VERSION ""

NS_ :

BS_:

BU_:  Battery  Charger  Host

BO_ 2566852863 BATT_eventMatrix_A_9: 8 Battery
 SG_ BATT_packModIdFault_9 : 8|1@1+ (1,0) [0|1] "" Host
 SG_ BATT_packModExitedFromBus_9 : 16|1@1+ (1,0) [0|1] "" Host
 SG_ BATT_packFetChgWelded_9 : 35|1@1+ (1,0) [0|1] "" Host
 SG_ BATT_packFetDsgWelded_9 : 36|1@1+ (1,0) [0|1] "" Host
 SG_ BATT_fetDsgShortedAux_9 : 63|1@1+ (1,0) [0|1] "" Host
 SG_ BATT_fetChgShortedAux_9 : 25|1@1+ (1,0) [0|1] "" Host
 SG_ BATT_prechargeFetFail_9 : 39|1@1+ (1,0) [0|1] "" Host
 SG_ BATT_abnormalResetReason_9 : 31|1@1+ (1,0) [0|1] "" Host
 SG_ BATT_prechargeTooSlow_9 : 49|1@1+ (1,0) [0|1] "" Host
 SG_ BATT_prechargeTooFast_9 : 50|1@1+ (1,0) [0|1] "" Host
 SG_ BATT_prechargeTimeout_9 : 51|1@1+ (1,0) [0|1] "" Host
 SG_ BATT_fetChgShorted_9 : 23|1@1+ (1,0) [0|1] "" Host
 SG_ BATT_fetChgFailToClose_9 : 22|1@1+ (1,0) [0|1] "" Host
 SG_ BATT_packModSelectFault_9 : 21|1@1+ (1,0) [0|1] "" Host
 SG_ BATT_packModConnectFault_9 : 20|1@1+ (1,0) [0|1] "" Host
 SG_ BATT_packModMIA_9 : 19|1@1+ (1,0) [0|1] "" Host
 SG_ BATT_packModImbalance_9 : 18|1@1+ (1,0) [0|1] "" Host
 SG_ BATT_afeFault_9 : 17|1@1+ (1,0) [0|1] "" Host
 SG_ BATT_chargerMIA_9 : 60|1@1+ (1,0) [0|1] "" Host
 SG_ BATT_chargerError_9 : 59|1@1+ (1,0) [0|1] "" Host
 SG_ BATT_vBrickUnderWar_9 : 58|1@1+ (1,0) [0|1] "" Host
 SG_ BATT_vBrickUnderSev_9 : 57|1@1+ (1,0) [0|1] "" Host
 SG_ BATT_vBrickUnderMod_9 : 56|1@1+ (1,0) [0|1] "" Host
 SG_ BATT_vBrickOverWar_9 : 55|1@1+ (1,0) [0|1] "" Host
 SG_ BATT_vBrickOverSev_9 : 54|1@1+ (1,0) [0|1] "" Host
 SG_ BATT_vBrickOverMod_9 : 53|1@1+ (1,0) [0|1] "" Host
 SG_ BATT_vBrickImbalance_9 : 52|1@1+ (1,0) [0|1] "" Host
 SG_ BATT_loggerAlmostFull_9 : 61|1@1+ (1,0) [0|1] "" Host
 SG_ BATT_tempModuleUnderWar_9 : 48|1@1+ (1,0) [0|1] "" Host
 SG_ BATT_tempModuleUnderSev_9 : 47|1@1+ (1,0) [0|1] "" Host
 SG_ BATT_tempModuleUnderMod_9 : 46|1@1+ (1,0) [0|1] "" Host
 SG_ BATT_tempModuleOverWar_9 : 45|1@1+ (1,0) [0|1] "" Host
 SG_ BATT_tempModuleOverSev_9 : 44|1@1+ (1,0) [0|1] "" Host
 SG_ BATT_tempModuleOverMod_9 : 43|1@1+ (1,0) [0|1] "" Host
 SG_ BATT_tempBrickImbalance_9 : 42|1@1+ (1,0) [0|1] "" Host
 SG_ BATT_taskLockupError_9 : 41|1@1+ (1,0) [0|1] "" Host
 SG_ BATT_tempBoardOverWar_9 : 40|1@1+ (1,0) [0|1] "" Host
 SG_ BATT_tempBoardOverSev_9 : 38|1@1+ (1,0) [0|1] "" Host
 SG_ BATT_tempBoardOverMod_9 : 37|1@1+ (1,0) [0|1] "" Host
 SG_ BATT_sensePackVoltError_9 : 34|1@1+ (1,0) [0|1] "" Host
 SG_ BATT_senseLoadVoltError_9 : 33|1@1+ (1,0) [0|1] "" Host
 SG_ BATT_loggerFull_9 : 62|1@1+ (1,0) [0|1] "" Host
 SG_ BATT_senseCurrentError_9 : 32|1@1+ (1,0) [0|1] "" Host
 SG_ BATT_senseBrickTempError_9 : 30|1@1+ (1,0) [0|1] "" Host
 SG_ BATT_resPackHigh_9 : 29|1@1+ (1,0) [0|1] "" Host
 SG_ BATT_ramOverUtilError_9 : 28|1@1+ (1,0) [0|1] "" Host
 SG_ BATT_powerPackInsufficient_9 : 27|1@1+ (1,0) [0|1] "" Host
 SG_ BATT_packCellSoftShort_9 : 26|1@1+ (1,0) [0|1] "" Host
 SG_ BATT_iOverHardware_9 : 24|1@1+ (1,0) [0|1] "" Host
 SG_ BATT_fetOverTemp_9 : 15|1@1+ (1,0) [0|1] "" Host
 SG_ BATT_iOverDischarge_9 : 14|1@1+ (1,0) [0|1] "" Host
 SG_ BATT_iOverCharge_9 : 13|1@1+ (1,0) [0|1] "" Host
 SG_ BATT_inverterDriveMIA_9 : 12|1@1+ (1,0) [0|1] "" Host
 SG_ BATT_iUnderCharge_9 : 11|1@1+ (1,0) [0|1] "" Host
 SG_ BATT_hostMIA_9 : 10|1@1+ (1,0) [0|1] "" Host
 SG_ BATT_fetDsgShorted_9 : 7|1@1+ (1,0) [0|1] "" Host
 SG_ BATT_fetDsgFailToClose_9 : 6|1@1+ (1,0) [0|1] "" Host
 SG_ BATT_capLow_9 : 5|1@1+ (1,0) [0|1] "" Host
 SG_ BATT_brickOverDischarge_9 : 4|1@1+ (1,0) [0|1] "" Host
 SG_ BATT_brickOverCharge_9 : 3|1@1+ (1,0) [0|1] "" Host
 SG_ BATT_bmsProcessorError_9 : 2|1@1+ (1,0) [0|1] "" Host
 SG_ BATT_bmsMemoryError_9 : 1|1@1+ (1,0) [0|1] "" Host
 SG_ BATT_afeError_9 : 0|1@1+ (1,0) [0|1] "" Host

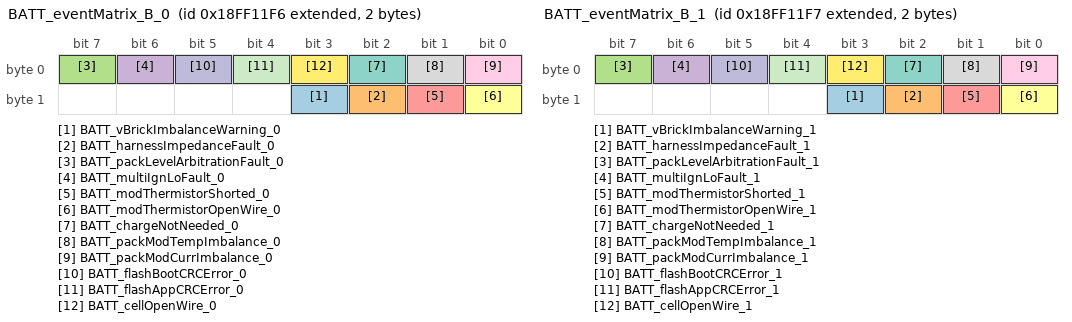
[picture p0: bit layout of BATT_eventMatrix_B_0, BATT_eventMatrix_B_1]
BO_ 2566853110 BATT_eventMatrix_B_0: 2 Battery
 SG_ BATT_vBrickImbalanceWarning_0 : 11|1@1+ (1,0) [0|1] "" Host
 SG_ BATT_harnessImpedanceFault_0 : 10|1@1+ (1,0) [0|1] "mOhms" Host
 SG_ BATT_packLevelArbitrationFault_0 : 7|1@1+ (1,0) [0|1] "" Host
 SG_ BATT_multiIgnLoFault_0 : 6|1@1+ (1,0) [0|1] "" Host
 SG_ BATT_modThermistorShorted_0 : 9|1@1+ (1,0) [0|1] "" Host
 SG_ BATT_modThermistorOpenWire_0 : 8|1@1+ (1,0) [0|1] "" Host
 SG_ BATT_chargeNotNeeded_0 : 2|1@1+ (1,0) [0|1] "" Host
 SG_ BATT_packModTempImbalance_0 : 1|1@1+ (1,0) [0|1] "" Host
 SG_ BATT_packModCurrImbalance_0 : 0|1@1+ (1,0) [0|1] "" Host
 SG_ BATT_flashBootCRCError_0 : 5|1@1+ (1,0) [0|1] "" Host
 SG_ BATT_flashAppCRCError_0 : 4|1@1+ (1,0) [0|1] "" Host
 SG_ BATT_cellOpenWire_0 : 3|1@1+ (1,0) [0|1] "" Host

BO_ 2566853111 BATT_eventMatrix_B_1: 2 Battery
 SG_ BATT_vBrickImbalanceWarning_1 : 11|1@1+ (1,0) [0|1] "" Host
 SG_ BATT_harnessImpedanceFault_1 : 10|1@1+ (1,0) [0|1] "mOhms" Host
 SG_ BATT_packLevelArbitrationFault_1 : 7|1@1+ (1,0) [0|1] "" Host
 SG_ BATT_multiIgnLoFault_1 : 6|1@1+ (1,0) [0|1] "" Host
 SG_ BATT_modThermistorShorted_1 : 9|1@1+ (1,0) [0|1] "" Host
 SG_ BATT_modThermistorOpenWire_1 : 8|1@1+ (1,0) [0|1] "" Host
 SG_ BATT_chargeNotNeeded_1 : 2|1@1+ (1,0) [0|1] "" Host
 SG_ BATT_packModTempImbalance_1 : 1|1@1+ (1,0) [0|1] "" Host
 SG_ BATT_packModCurrImbalance_1 : 0|1@1+ (1,0) [0|1] "" Host
 SG_ BATT_flashBootCRCError_1 : 5|1@1+ (1,0) [0|1] "" Host
 SG_ BATT_flashAppCRCError_1 : 4|1@1+ (1,0) [0|1] "" Host
 SG_ BATT_cellOpenWire_1 : 3|1@1+ (1,0) [0|1] "" Host

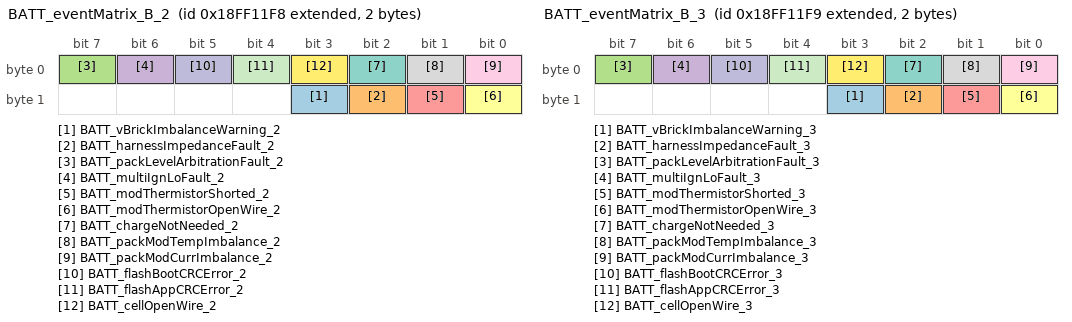
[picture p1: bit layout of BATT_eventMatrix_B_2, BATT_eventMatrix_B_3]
BO_ 2566853112 BATT_eventMatrix_B_2: 2 Battery
 SG_ BATT_vBrickImbalanceWarning_2 : 11|1@1+ (1,0) [0|1] "" Host
 SG_ BATT_harnessImpedanceFault_2 : 10|1@1+ (1,0) [0|1] "mOhms" Host
 SG_ BATT_packLevelArbitrationFault_2 : 7|1@1+ (1,0) [0|1] "" Host
 SG_ BATT_multiIgnLoFault_2 : 6|1@1+ (1,0) [0|1] "" Host
 SG_ BATT_modThermistorShorted_2 : 9|1@1+ (1,0) [0|1] "" Host
 SG_ BATT_modThermistorOpenWire_2 : 8|1@1+ (1,0) [0|1] "" Host
 SG_ BATT_chargeNotNeeded_2 : 2|1@1+ (1,0) [0|1] "" Host
 SG_ BATT_packModTempImbalance_2 : 1|1@1+ (1,0) [0|1] "" Host
 SG_ BATT_packModCurrImbalance_2 : 0|1@1+ (1,0) [0|1] "" Host
 SG_ BATT_flashBootCRCError_2 : 5|1@1+ (1,0) [0|1] "" Host
 SG_ BATT_flashAppCRCError_2 : 4|1@1+ (1,0) [0|1] "" Host
 SG_ BATT_cellOpenWire_2 : 3|1@1+ (1,0) [0|1] "" Host

BO_ 2566853113 BATT_eventMatrix_B_3: 2 Battery
 SG_ BATT_vBrickImbalanceWarning_3 : 11|1@1+ (1,0) [0|1] "" Host
 SG_ BATT_harnessImpedanceFault_3 : 10|1@1+ (1,0) [0|1] "mOhms" Host
 SG_ BATT_packLevelArbitrationFault_3 : 7|1@1+ (1,0) [0|1] "" Host
 SG_ BATT_multiIgnLoFault_3 : 6|1@1+ (1,0) [0|1] "" Host
 SG_ BATT_modThermistorShorted_3 : 9|1@1+ (1,0) [0|1] "" Host
 SG_ BATT_modThermistorOpenWire_3 : 8|1@1+ (1,0) [0|1] "" Host
 SG_ BATT_chargeNotNeeded_3 : 2|1@1+ (1,0) [0|1] "" Host
 SG_ BATT_packModTempImbalance_3 : 1|1@1+ (1,0) [0|1] "" Host
 SG_ BATT_packModCurrImbalance_3 : 0|1@1+ (1,0) [0|1] "" Host
 SG_ BATT_flashBootCRCError_3 : 5|1@1+ (1,0) [0|1] "" Host
 SG_ BATT_flashAppCRCError_3 : 4|1@1+ (1,0) [0|1] "" Host
 SG_ BATT_cellOpenWire_3 : 3|1@1+ (1,0) [0|1] "" Host

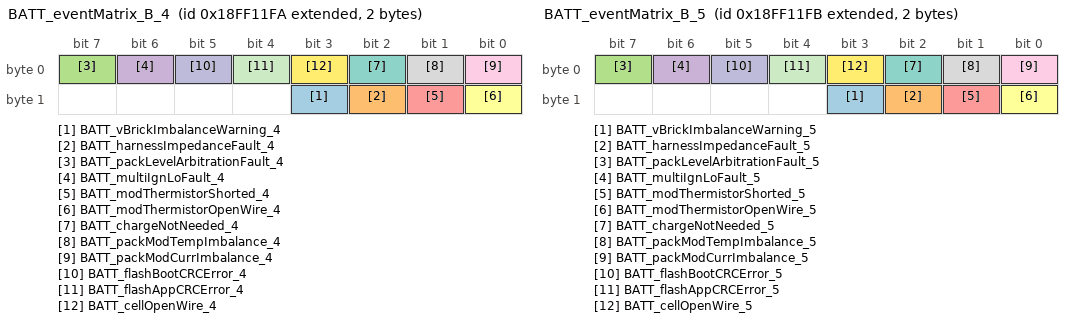
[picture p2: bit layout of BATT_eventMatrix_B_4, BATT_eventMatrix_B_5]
BO_ 2566853114 BATT_eventMatrix_B_4: 2 Battery
 SG_ BATT_vBrickImbalanceWarning_4 : 11|1@1+ (1,0) [0|1] "" Host
 SG_ BATT_harnessImpedanceFault_4 : 10|1@1+ (1,0) [0|1] "mOhms" Host
 SG_ BATT_packLevelArbitrationFault_4 : 7|1@1+ (1,0) [0|1] "" Host
 SG_ BATT_multiIgnLoFault_4 : 6|1@1+ (1,0) [0|1] "" Host
 SG_ BATT_modThermistorShorted_4 : 9|1@1+ (1,0) [0|1] "" Host
 SG_ BATT_modThermistorOpenWire_4 : 8|1@1+ (1,0) [0|1] "" Host
 SG_ BATT_chargeNotNeeded_4 : 2|1@1+ (1,0) [0|1] "" Host
 SG_ BATT_packModTempImbalance_4 : 1|1@1+ (1,0) [0|1] "" Host
 SG_ BATT_packModCurrImbalance_4 : 0|1@1+ (1,0) [0|1] "" Host
 SG_ BATT_flashBootCRCError_4 : 5|1@1+ (1,0) [0|1] "" Host
 SG_ BATT_flashAppCRCError_4 : 4|1@1+ (1,0) [0|1] "" Host
 SG_ BATT_cellOpenWire_4 : 3|1@1+ (1,0) [0|1] "" Host

BO_ 2566853115 BATT_eventMatrix_B_5: 2 Battery
 SG_ BATT_vBrickImbalanceWarning_5 : 11|1@1+ (1,0) [0|1] "" Host
 SG_ BATT_harnessImpedanceFault_5 : 10|1@1+ (1,0) [0|1] "mOhms" Host
 SG_ BATT_packLevelArbitrationFault_5 : 7|1@1+ (1,0) [0|1] "" Host
 SG_ BATT_multiIgnLoFault_5 : 6|1@1+ (1,0) [0|1] "" Host
 SG_ BATT_modThermistorShorted_5 : 9|1@1+ (1,0) [0|1] "" Host
 SG_ BATT_modThermistorOpenWire_5 : 8|1@1+ (1,0) [0|1] "" Host
 SG_ BATT_chargeNotNeeded_5 : 2|1@1+ (1,0) [0|1] "" Host
 SG_ BATT_packModTempImbalance_5 : 1|1@1+ (1,0) [0|1] "" Host
 SG_ BATT_packModCurrImbalance_5 : 0|1@1+ (1,0) [0|1] "" Host
 SG_ BATT_flashBootCRCError_5 : 5|1@1+ (1,0) [0|1] "" Host
 SG_ BATT_flashAppCRCError_5 : 4|1@1+ (1,0) [0|1] "" Host
 SG_ BATT_cellOpenWire_5 : 3|1@1+ (1,0) [0|1] "" Host

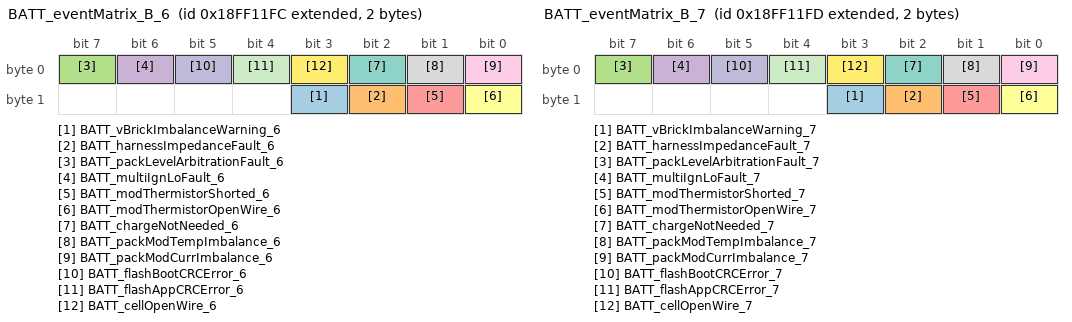
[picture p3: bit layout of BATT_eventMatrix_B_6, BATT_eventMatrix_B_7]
BO_ 2566853116 BATT_eventMatrix_B_6: 2 Battery
 SG_ BATT_vBrickImbalanceWarning_6 : 11|1@1+ (1,0) [0|1] "" Host
 SG_ BATT_harnessImpedanceFault_6 : 10|1@1+ (1,0) [0|1] "mOhms" Host
 SG_ BATT_packLevelArbitrationFault_6 : 7|1@1+ (1,0) [0|1] "" Host
 SG_ BATT_multiIgnLoFault_6 : 6|1@1+ (1,0) [0|1] "" Host
 SG_ BATT_modThermistorShorted_6 : 9|1@1+ (1,0) [0|1] "" Host
 SG_ BATT_modThermistorOpenWire_6 : 8|1@1+ (1,0) [0|1] "" Host
 SG_ BATT_chargeNotNeeded_6 : 2|1@1+ (1,0) [0|1] "" Host
 SG_ BATT_packModTempImbalance_6 : 1|1@1+ (1,0) [0|1] "" Host
 SG_ BATT_packModCurrImbalance_6 : 0|1@1+ (1,0) [0|1] "" Host
 SG_ BATT_flashBootCRCError_6 : 5|1@1+ (1,0) [0|1] "" Host
 SG_ BATT_flashAppCRCError_6 : 4|1@1+ (1,0) [0|1] "" Host
 SG_ BATT_cellOpenWire_6 : 3|1@1+ (1,0) [0|1] "" Host

BO_ 2566853117 BATT_eventMatrix_B_7: 2 Battery
 SG_ BATT_vBrickImbalanceWarning_7 : 11|1@1+ (1,0) [0|1] "" Host
 SG_ BATT_harnessImpedanceFault_7 : 10|1@1+ (1,0) [0|1] "mOhms" Host
 SG_ BATT_packLevelArbitrationFault_7 : 7|1@1+ (1,0) [0|1] "" Host
 SG_ BATT_multiIgnLoFault_7 : 6|1@1+ (1,0) [0|1] "" Host
 SG_ BATT_modThermistorShorted_7 : 9|1@1+ (1,0) [0|1] "" Host
 SG_ BATT_modThermistorOpenWire_7 : 8|1@1+ (1,0) [0|1] "" Host
 SG_ BATT_chargeNotNeeded_7 : 2|1@1+ (1,0) [0|1] "" Host
 SG_ BATT_packModTempImbalance_7 : 1|1@1+ (1,0) [0|1] "" Host
 SG_ BATT_packModCurrImbalance_7 : 0|1@1+ (1,0) [0|1] "" Host
 SG_ BATT_flashBootCRCError_7 : 5|1@1+ (1,0) [0|1] "" Host
 SG_ BATT_flashAppCRCError_7 : 4|1@1+ (1,0) [0|1] "" Host
 SG_ BATT_cellOpenWire_7 : 3|1@1+ (1,0) [0|1] "" Host

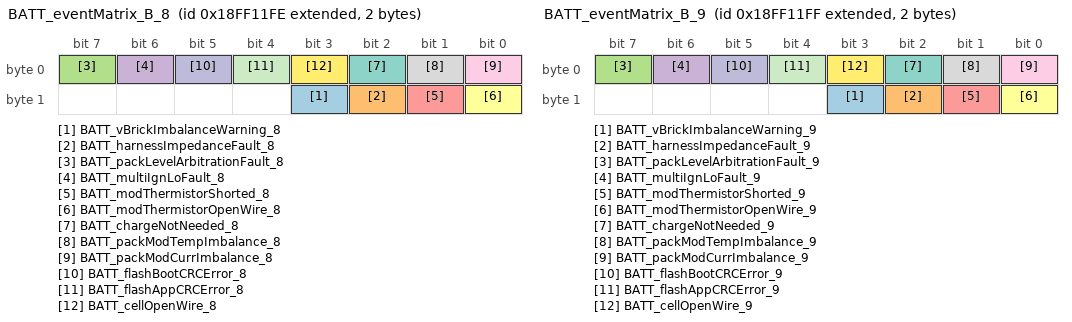
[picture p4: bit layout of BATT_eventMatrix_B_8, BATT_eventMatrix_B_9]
BO_ 2566853118 BATT_eventMatrix_B_8: 2 Battery
 SG_ BATT_vBrickImbalanceWarning_8 : 11|1@1+ (1,0) [0|1] "" Host
 SG_ BATT_harnessImpedanceFault_8 : 10|1@1+ (1,0) [0|1] "mOhms" Host
 SG_ BATT_packLevelArbitrationFault_8 : 7|1@1+ (1,0) [0|1] "" Host
 SG_ BATT_multiIgnLoFault_8 : 6|1@1+ (1,0) [0|1] "" Host
 SG_ BATT_modThermistorShorted_8 : 9|1@1+ (1,0) [0|1] "" Host
 SG_ BATT_modThermistorOpenWire_8 : 8|1@1+ (1,0) [0|1] "" Host
 SG_ BATT_chargeNotNeeded_8 : 2|1@1+ (1,0) [0|1] "" Host
 SG_ BATT_packModTempImbalance_8 : 1|1@1+ (1,0) [0|1] "" Host
 SG_ BATT_packModCurrImbalance_8 : 0|1@1+ (1,0) [0|1] "" Host
 SG_ BATT_flashBootCRCError_8 : 5|1@1+ (1,0) [0|1] "" Host
 SG_ BATT_flashAppCRCError_8 : 4|1@1+ (1,0) [0|1] "" Host
 SG_ BATT_cellOpenWire_8 : 3|1@1+ (1,0) [0|1] "" Host

BO_ 2566853119 BATT_eventMatrix_B_9: 2 Battery
 SG_ BATT_vBrickImbalanceWarning_9 : 11|1@1+ (1,0) [0|1] "" Host
 SG_ BATT_harnessImpedanceFault_9 : 10|1@1+ (1,0) [0|1] "mOhms" Host
 SG_ BATT_packLevelArbitrationFault_9 : 7|1@1+ (1,0) [0|1] "" Host
 SG_ BATT_multiIgnLoFault_9 : 6|1@1+ (1,0) [0|1] "" Host
 SG_ BATT_modThermistorShorted_9 : 9|1@1+ (1,0) [0|1] "" Host
 SG_ BATT_modThermistorOpenWire_9 : 8|1@1+ (1,0) [0|1] "" Host
 SG_ BATT_chargeNotNeeded_9 : 2|1@1+ (1,0) [0|1] "" Host
 SG_ BATT_packModTempImbalance_9 : 1|1@1+ (1,0) [0|1] "" Host
 SG_ BATT_packModCurrImbalance_9 : 0|1@1+ (1,0) [0|1] "" Host
 SG_ BATT_flashBootCRCError_9 : 5|1@1+ (1,0) [0|1] "" Host
 SG_ BATT_flashAppCRCError_9 : 4|1@1+ (1,0) [0|1] "" Host
 SG_ BATT_cellOpenWire_9 : 3|1@1+ (1,0) [0|1] "" Host

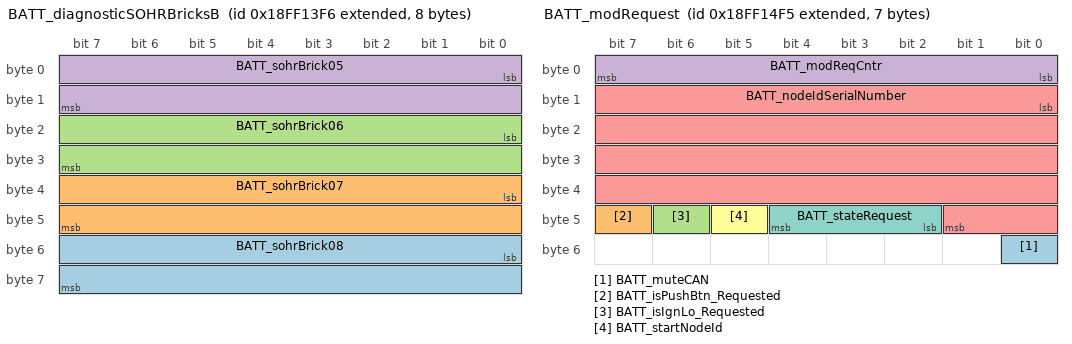
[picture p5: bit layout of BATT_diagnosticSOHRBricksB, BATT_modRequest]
BO_ 2566853622 BATT_diagnosticSOHRBricksB: 8 Battery
 SG_ BATT_sohrBrick08 : 48|16@1+ (0.00075,0) [0|49.15125] "Ah" Host
 SG_ BATT_sohrBrick07 : 32|16@1+ (0.00075,0) [0|49.15125] "Ah" Host
 SG_ BATT_sohrBrick06 : 16|16@1+ (0.00075,0) [0|49.15125] "Ah" Host
 SG_ BATT_sohrBrick05 : 0|16@1+ (0.00075,0) [0|49.15125] "Ah" Host

BO_ 2566853877 BATT_modRequest: 7 Battery
 SG_ BATT_muteCAN : 48|1@1+ (1,0) [0|1] "" Host,Battery
 SG_ BATT_isPushBtn_Requested : 47|1@1+ (1,0) [0|1] "" Battery,Host
 SG_ BATT_isIgnLo_Requested : 46|1@1+ (1,0) [0|1] "" Battery,Host
 SG_ BATT_modReqCntr : 0|8@1+ (1,0) [0|255] "" Battery,Host
 SG_ BATT_nodeIdSerialNumber : 8|34@1+ (1,0) [0|17179869183] "" Battery,Host
 SG_ BATT_startNodeId : 45|1@1+ (1,0) [0|1] "" Battery,Host
 SG_ BATT_stateRequest : 42|3@1+ (1,0) [0|7] "" Battery,Host

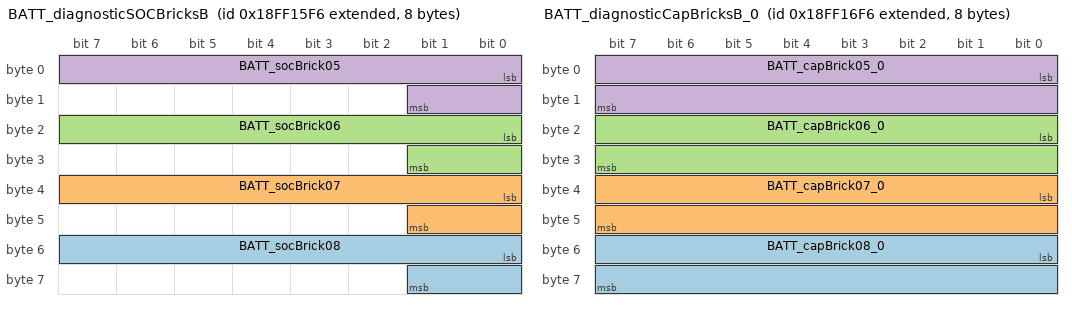
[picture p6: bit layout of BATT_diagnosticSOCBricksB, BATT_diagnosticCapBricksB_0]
BO_ 2566854134 BATT_diagnosticSOCBricksB: 8 Battery
 SG_ BATT_socBrick08 : 48|10@1+ (0.1,0) [0|102.3] "%" Host
 SG_ BATT_socBrick07 : 32|10@1+ (0.1,0) [0|102.3] "%" Host
 SG_ BATT_socBrick06 : 16|10@1+ (0.1,0) [0|102.3] "%" Host
 SG_ BATT_socBrick05 : 0|10@1+ (0.1,0) [0|102.3] "%" Host

BO_ 2566854390 BATT_diagnosticCapBricksB_0: 8 Battery
 SG_ BATT_capBrick08_0 : 48|16@1+ (0.0025,0) [0|163.8375] "Ah" Host
 SG_ BATT_capBrick07_0 : 32|16@1+ (0.0025,0) [0|163.8375] "Ah" Host
 SG_ BATT_capBrick06_0 : 16|16@1+ (0.0025,0) [0|163.8375] "Ah" Host
 SG_ BATT_capBrick05_0 : 0|16@1+ (0.0025,0) [0|163.8375] "Ah" Host

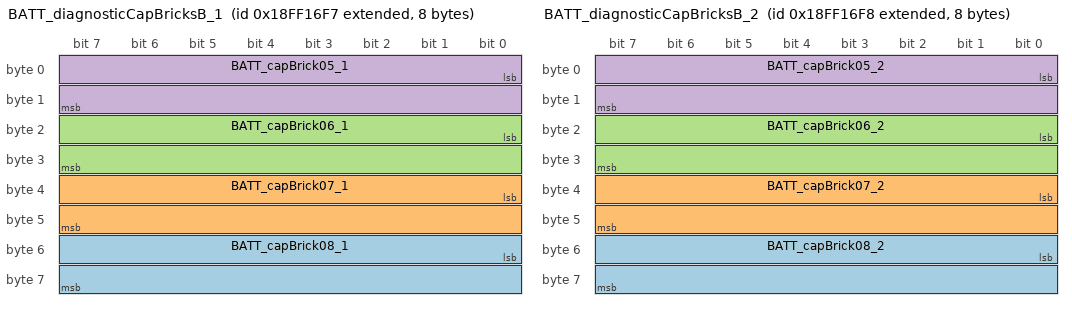
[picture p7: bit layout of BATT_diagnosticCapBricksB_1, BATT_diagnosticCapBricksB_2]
BO_ 2566854391 BATT_diagnosticCapBricksB_1: 8 Battery
 SG_ BATT_capBrick08_1 : 48|16@1+ (0.0025,0) [0|163.8375] "Ah" Host
 SG_ BATT_capBrick07_1 : 32|16@1+ (0.0025,0) [0|163.8375] "Ah" Host
 SG_ BATT_capBrick06_1 : 16|16@1+ (0.0025,0) [0|163.8375] "Ah" Host
 SG_ BATT_capBrick05_1 : 0|16@1+ (0.0025,0) [0|163.8375] "Ah" Host

BO_ 2566854392 BATT_diagnosticCapBricksB_2: 8 Battery
 SG_ BATT_capBrick08_2 : 48|16@1+ (0.0025,0) [0|163.8375] "Ah" Host
 SG_ BATT_capBrick07_2 : 32|16@1+ (0.0025,0) [0|163.8375] "Ah" Host
 SG_ BATT_capBrick06_2 : 16|16@1+ (0.0025,0) [0|163.8375] "Ah" Host
 SG_ BATT_capBrick05_2 : 0|16@1+ (0.0025,0) [0|163.8375] "Ah" Host

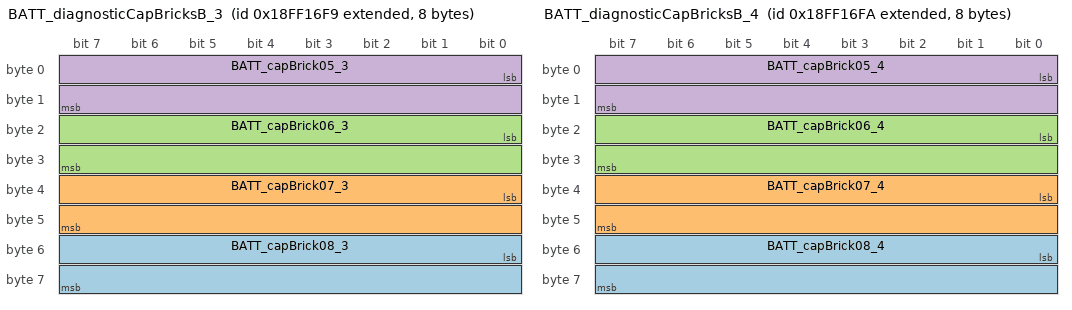
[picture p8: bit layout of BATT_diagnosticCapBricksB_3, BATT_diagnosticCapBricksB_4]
BO_ 2566854393 BATT_diagnosticCapBricksB_3: 8 Battery
 SG_ BATT_capBrick08_3 : 48|16@1+ (0.0025,0) [0|163.8375] "Ah" Host
 SG_ BATT_capBrick07_3 : 32|16@1+ (0.0025,0) [0|163.8375] "Ah" Host
 SG_ BATT_capBrick06_3 : 16|16@1+ (0.0025,0) [0|163.8375] "Ah" Host
 SG_ BATT_capBrick05_3 : 0|16@1+ (0.0025,0) [0|163.8375] "Ah" Host

BO_ 2566854394 BATT_diagnosticCapBricksB_4: 8 Battery
 SG_ BATT_capBrick08_4 : 48|16@1+ (0.0025,0) [0|163.8375] "Ah" Host
 SG_ BATT_capBrick07_4 : 32|16@1+ (0.0025,0) [0|163.8375] "Ah" Host
 SG_ BATT_capBrick06_4 : 16|16@1+ (0.0025,0) [0|163.8375] "Ah" Host
 SG_ BATT_capBrick05_4 : 0|16@1+ (0.0025,0) [0|163.8375] "Ah" Host

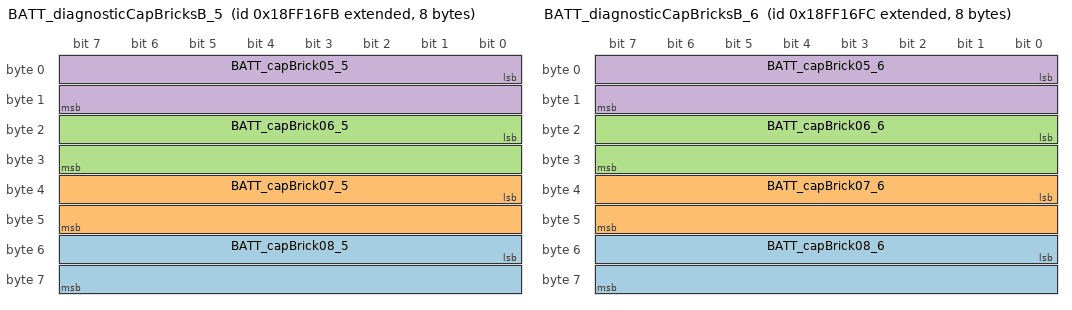
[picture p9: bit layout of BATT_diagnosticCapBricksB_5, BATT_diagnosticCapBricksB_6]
BO_ 2566854395 BATT_diagnosticCapBricksB_5: 8 Battery
 SG_ BATT_capBrick08_5 : 48|16@1+ (0.0025,0) [0|163.8375] "Ah" Host
 SG_ BATT_capBrick07_5 : 32|16@1+ (0.0025,0) [0|163.8375] "Ah" Host
 SG_ BATT_capBrick06_5 : 16|16@1+ (0.0025,0) [0|163.8375] "Ah" Host
 SG_ BATT_capBrick05_5 : 0|16@1+ (0.0025,0) [0|163.8375] "Ah" Host

BO_ 2566854396 BATT_diagnosticCapBricksB_6: 8 Battery
 SG_ BATT_capBrick08_6 : 48|16@1+ (0.0025,0) [0|163.8375] "Ah" Host
 SG_ BATT_capBrick07_6 : 32|16@1+ (0.0025,0) [0|163.8375] "Ah" Host
 SG_ BATT_capBrick06_6 : 16|16@1+ (0.0025,0) [0|163.8375] "Ah" Host
 SG_ BATT_capBrick05_6 : 0|16@1+ (0.0025,0) [0|163.8375] "Ah" Host

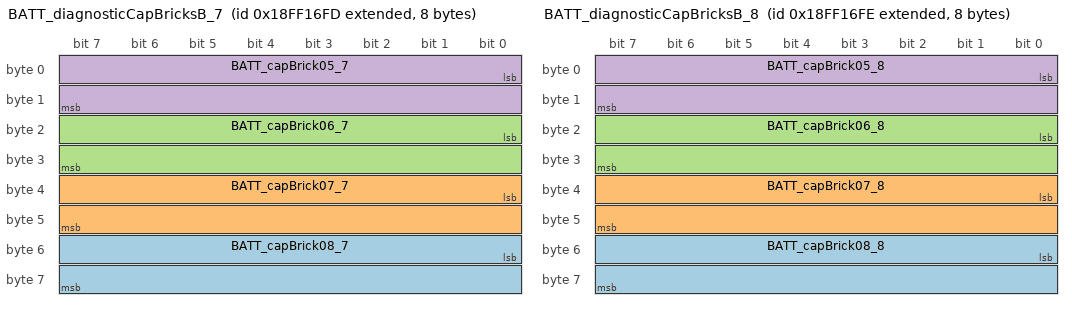
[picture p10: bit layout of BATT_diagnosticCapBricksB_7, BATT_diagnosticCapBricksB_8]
BO_ 2566854397 BATT_diagnosticCapBricksB_7: 8 Battery
 SG_ BATT_capBrick08_7 : 48|16@1+ (0.0025,0) [0|163.8375] "Ah" Host
 SG_ BATT_capBrick07_7 : 32|16@1+ (0.0025,0) [0|163.8375] "Ah" Host
 SG_ BATT_capBrick06_7 : 16|16@1+ (0.0025,0) [0|163.8375] "Ah" Host
 SG_ BATT_capBrick05_7 : 0|16@1+ (0.0025,0) [0|163.8375] "Ah" Host

BO_ 2566854398 BATT_diagnosticCapBricksB_8: 8 Battery
 SG_ BATT_capBrick08_8 : 48|16@1+ (0.0025,0) [0|163.8375] "Ah" Host
 SG_ BATT_capBrick07_8 : 32|16@1+ (0.0025,0) [0|163.8375] "Ah" Host
 SG_ BATT_capBrick06_8 : 16|16@1+ (0.0025,0) [0|163.8375] "Ah" Host
 SG_ BATT_capBrick05_8 : 0|16@1+ (0.0025,0) [0|163.8375] "Ah" Host

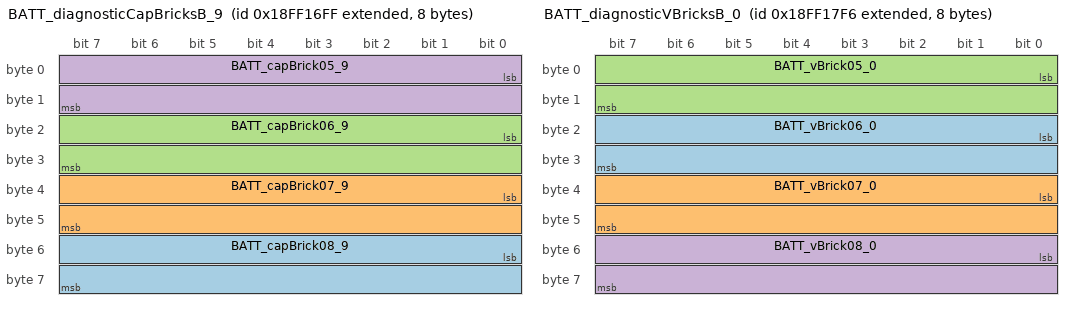
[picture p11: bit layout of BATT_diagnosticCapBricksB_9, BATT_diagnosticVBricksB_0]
BO_ 2566854399 BATT_diagnosticCapBricksB_9: 8 Battery
 SG_ BATT_capBrick08_9 : 48|16@1+ (0.0025,0) [0|163.8375] "Ah" Host
 SG_ BATT_capBrick07_9 : 32|16@1+ (0.0025,0) [0|163.8375] "Ah" Host
 SG_ BATT_capBrick06_9 : 16|16@1+ (0.0025,0) [0|163.8375] "Ah" Host
 SG_ BATT_capBrick05_9 : 0|16@1+ (0.0025,0) [0|163.8375] "Ah" Host

BO_ 2566854646 BATT_diagnosticVBricksB_0: 8 Battery
 SG_ BATT_vBrick06_0 : 16|16@1+ (7.6e-05,0) [0|4.98066] "V" Host
 SG_ BATT_vBrick07_0 : 32|16@1+ (7.6e-05,0) [0|4.98066] "V" Host
 SG_ BATT_vBrick05_0 : 0|16@1+ (7.6e-05,0) [0|4.98066] "V" Host
 SG_ BATT_vBrick08_0 : 48|16@1+ (7.6e-05,0) [0|4.98066] "V" Host

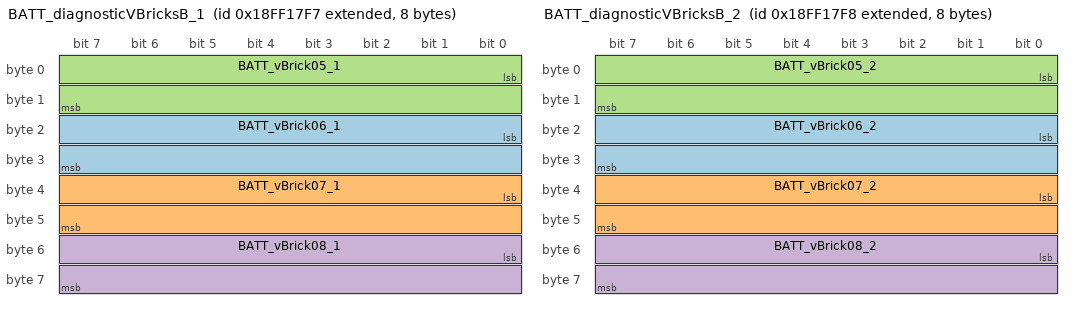
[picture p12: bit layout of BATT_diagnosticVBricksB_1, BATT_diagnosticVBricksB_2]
BO_ 2566854647 BATT_diagnosticVBricksB_1: 8 Battery
 SG_ BATT_vBrick06_1 : 16|16@1+ (7.6e-05,0) [0|4.98066] "V" Host
 SG_ BATT_vBrick07_1 : 32|16@1+ (7.6e-05,0) [0|4.98066] "V" Host
 SG_ BATT_vBrick05_1 : 0|16@1+ (7.6e-05,0) [0|4.98066] "V" Host
 SG_ BATT_vBrick08_1 : 48|16@1+ (7.6e-05,0) [0|4.98066] "V" Host

BO_ 2566854648 BATT_diagnosticVBricksB_2: 8 Battery
 SG_ BATT_vBrick06_2 : 16|16@1+ (7.6e-05,0) [0|4.98066] "V" Host
 SG_ BATT_vBrick07_2 : 32|16@1+ (7.6e-05,0) [0|4.98066] "V" Host
 SG_ BATT_vBrick05_2 : 0|16@1+ (7.6e-05,0) [0|4.98066] "V" Host
 SG_ BATT_vBrick08_2 : 48|16@1+ (7.6e-05,0) [0|4.98066] "V" Host

BO_ 2566854649 BATT_diagnosticVBricksB_3: 8 Battery
 SG_ BATT_vBrick06_3 : 16|16@1+ (7.6e-05,0) [0|4.98066] "V" Host
 SG_ BATT_vBrick07_3 : 32|16@1+ (7.6e-05,0) [0|4.98066] "V" Host
 SG_ BATT_vBrick05_3 : 0|16@1+ (7.6e-05,0) [0|4.98066] "V" Host
 SG_ BATT_vBrick08_3 : 48|16@1+ (7.6e-05,0) [0|4.98066] "V" Host

BO_ 2566854650 BATT_diagnosticVBricksB_4: 8 Battery
 SG_ BATT_vBrick06_4 : 16|16@1+ (7.6e-05,0) [0|4.98066] "V" Host
 SG_ BATT_vBrick07_4 : 32|16@1+ (7.6e-05,0) [0|4.98066] "V" Host
 SG_ BATT_vBrick05_4 : 0|16@1+ (7.6e-05,0) [0|4.98066] "V" Host
 SG_ BATT_vBrick08_4 : 48|16@1+ (7.6e-05,0) [0|4.98066] "V" Host

BO_ 2566854651 BATT_diagnosticVBricksB_5: 8 Battery
 SG_ BATT_vBrick06_5 : 16|16@1+ (7.6e-05,0) [0|4.98066] "V" Host
 SG_ BATT_vBrick07_5 : 32|16@1+ (7.6e-05,0) [0|4.98066] "V" Host
 SG_ BATT_vBrick05_5 : 0|16@1+ (7.6e-05,0) [0|4.98066] "V" Host
 SG_ BATT_vBrick08_5 : 48|16@1+ (7.6e-05,0) [0|4.98066] "V" Host

BO_ 2566854652 BATT_diagnosticVBricksB_6: 8 Battery
 SG_ BATT_vBrick06_6 : 16|16@1+ (7.6e-05,0) [0|4.98066] "V" Host
 SG_ BATT_vBrick07_6 : 32|16@1+ (7.6e-05,0) [0|4.98066] "V" Host
 SG_ BATT_vBrick05_6 : 0|16@1+ (7.6e-05,0) [0|4.98066] "V" Host
 SG_ BATT_vBrick08_6 : 48|16@1+ (7.6e-05,0) [0|4.98066] "V" Host

BO_ 2566854653 BATT_diagnosticVBricksB_7: 8 Battery
 SG_ BATT_vBrick06_7 : 16|16@1+ (7.6e-05,0) [0|4.98066] "V" Host
 SG_ BATT_vBrick07_7 : 32|16@1+ (7.6e-05,0) [0|4.98066] "V" Host
 SG_ BATT_vBrick05_7 : 0|16@1+ (7.6e-05,0) [0|4.98066] "V" Host
 SG_ BATT_vBrick08_7 : 48|16@1+ (7.6e-05,0) [0|4.98066] "V" Host

BO_ 2566854654 BATT_diagnosticVBricksB_8: 8 Battery
 SG_ BATT_vBrick06_8 : 16|16@1+ (7.6e-05,0) [0|4.98066] "V" Host
 SG_ BATT_vBrick07_8 : 32|16@1+ (7.6e-05,0) [0|4.98066] "V" Host
 SG_ BATT_vBrick05_8 : 0|16@1+ (7.6e-05,0) [0|4.98066] "V" Host
 SG_ BATT_vBrick08_8 : 48|16@1+ (7.6e-05,0) [0|4.98066] "V" Host

BO_ 2566854655 BATT_diagnosticVBricksB_9: 8 Battery
 SG_ BATT_vBrick06_9 : 16|16@1+ (7.6e-05,0) [0|4.98066] "V" Host
 SG_ BATT_vBrick07_9 : 32|16@1+ (7.6e-05,0) [0|4.98066] "V" Host
 SG_ BATT_vBrick05_9 : 0|16@1+ (7.6e-05,0) [0|4.98066] "V" Host
 SG_ BATT_vBrick08_9 : 48|16@1+ (7.6e-05,0) [0|4.98066] "V" Host

BO_ 2566854902 BATT_diagnosticResBricksB: 8 Battery
 SG_ BATT_resBrick08 : 48|16@1+ (0.01,0) [0|655.35] "mOhms" Host
 SG_ BATT_resBrick07 : 32|16@1+ (0.01,0) [0|655.35] "mOhms" Host
 SG_ BATT_resBrick06 : 16|16@1+ (0.01,0) [0|655.35] "mOhms" Host
 SG_ BATT_resBrick05 : 0|16@1+ (0.01,0) [0|655.35] "mOhms" Host

BO_ 2566855158 BATT_modTemperaturesB_0: 8 Battery
 SG_ BATT_tPreChg_0 : 16|16@1- (0.1,0) [-40|125] "deg C" Host
 SG_ BATT_tShunt_0 : 48|16@1- (0.1,0) [-40|125] "deg C" Host
 SG_ BATT_tFET_0 : 32|16@1- (0.1,0) [-40|125] "deg C" Host

BO_ 2566855159 BATT_modTemperaturesB_1: 8 Battery
 SG_ BATT_tPreChg_1 : 16|16@1- (0.1,0) [-40|125] "deg C" Host
 SG_ BATT_tShunt_1 : 48|16@1- (0.1,0) [-40|125] "deg C" Host
 SG_ BATT_tFET_1 : 32|16@1- (0.1,0) [-40|125] "deg C" Host

BO_ 2566855160 BATT_modTemperaturesB_2: 8 Battery
 SG_ BATT_tPreChg_2 : 16|16@1- (0.1,0) [-40|125] "deg C" Host
 SG_ BATT_tShunt_2 : 48|16@1- (0.1,0) [-40|125] "deg C" Host
 SG_ BATT_tFET_2 : 32|16@1- (0.1,0) [-40|125] "deg C" Host

BO_ 2566855161 BATT_modTemperaturesB_3: 8 Battery
 SG_ BATT_tPreChg_3 : 16|16@1- (0.1,0) [-40|125] "deg C" Host
 SG_ BATT_tShunt_3 : 48|16@1- (0.1,0) [-40|125] "deg C" Host
 SG_ BATT_tFET_3 : 32|16@1- (0.1,0) [-40|125] "deg C" Host

BO_ 2566855162 BATT_modTemperaturesB_4: 8 Battery
 SG_ BATT_tPreChg_4 : 16|16@1- (0.1,0) [-40|125] "deg C" Host
 SG_ BATT_tShunt_4 : 48|16@1- (0.1,0) [-40|125] "deg C" Host
 SG_ BATT_tFET_4 : 32|16@1- (0.1,0) [-40|125] "deg C" Host

BO_ 2566855163 BATT_modTemperaturesB_5: 8 Battery
 SG_ BATT_tPreChg_5 : 16|16@1- (0.1,0) [-40|125] "deg C" Host
 SG_ BATT_tShunt_5 : 48|16@1- (0.1,0) [-40|125] "deg C" Host
 SG_ BATT_tFET_5 : 32|16@1- (0.1,0) [-40|125] "deg C" Host

BO_ 2566855164 BATT_modTemperaturesB_6: 8 Battery
 SG_ BATT_tPreChg_6 : 16|16@1- (0.1,0) [-40|125] "deg C" Host
 SG_ BATT_tShunt_6 : 48|16@1- (0.1,0) [-40|125] "deg C" Host
 SG_ BATT_tFET_6 : 32|16@1- (0.1,0) [-40|125] "deg C" Host

BO_ 2566855165 BATT_modTemperaturesB_7: 8 Battery
 SG_ BATT_tPreChg_7 : 16|16@1- (0.1,0) [-40|125] "deg C" Host
 SG_ BATT_tShunt_7 : 48|16@1- (0.1,0) [-40|125] "deg C" Host
 SG_ BATT_tFET_7 : 32|16@1- (0.1,0) [-40|125] "deg C" Host

BO_ 2566855166 BATT_modTemperaturesB_8: 8 Battery
 SG_ BATT_tPreChg_8 : 16|16@1- (0.1,0) [-40|125] "deg C" Host
 SG_ BATT_tShunt_8 : 48|16@1- (0.1,0) [-40|125] "deg C" Host
 SG_ BATT_tFET_8 : 32|16@1- (0.1,0) [-40|125] "deg C" Host

BO_ 2566855167 BATT_modTemperaturesB_9: 8 Battery
 SG_ BATT_tPreChg_9 : 16|16@1- (0.1,0) [-40|125] "deg C" Host
 SG_ BATT_tShunt_9 : 48|16@1- (0.1,0) [-40|125] "deg C" Host
 SG_ BATT_tFET_9 : 32|16@1- (0.1,0) [-40|125] "deg C" Host

BO_ 2566856694 BATT_boardIO_0: 3 Battery
 SG_ BATT_boardIO_nSD_PWR_AVL_0 : 20|1@1+ (1,0) [0|0] "" Host
 SG_ BATT_boardIO_nL9963_FAULT_0 : 19|1@1+ (1,0) [0|0] "" Host
 SG_ BATT_boardIO_PRE_CHG_FB_0 : 18|1@1+ (1,0) [0|0] "" Host
 SG_ BATT_boardIO_BTN_WAKE_LCH_0 : 17|1@1+ (1,0) [0|0] "" Host
 SG_ BATT_boardIO_BTN_WAKE_0 : 16|1@1+ (1,0) [0|0] "" Host
 SG_ BATT_boardIO_IGN_L_0 : 13|1@1+ (1,0) [0|0] "" Host
 SG_ BATT_boardIO_IGN_H_0 : 12|1@1+ (1,0) [0|0] "" Host
 SG_ BATT_boardIO_EXT_5V_STATUS_0 : 11|1@1+ (1,0) [0|0] "" Host
 SG_ BATT_boardIO_L9963_FAULT_LA_0 : 10|1@1+ (1,0) [0|0] "" Host
 SG_ BATT_boardIO_RTC_WAKE_LA_0 : 9|1@1+ (1,0) [0|0] "" Host
 SG_ BATT_boardIO_CAN_WAKE_LATCH_0 : 8|1@1+ (1,0) [0|0] "" Host
 SG_ BATT_boardIO_DIS_OC_FLT_LA_0 : 5|1@1+ (1,0) [0|1] "" Host
 SG_ BATT_boardIO_RTC_WAKE_LATCH_0 : 4|1@1+ (1,0) [0|0] "" Host
 SG_ BATT_boardIO_L9963_FAULT_0 : 3|1@1+ (1,0) [0|1] "" Host
 SG_ BATT_boardIO_IGN_L_LCH_0 : 2|1@1+ (1,0) [0|0] "" Host
 SG_ BATT_boardIO_IGN_H_LCH_0 : 1|1@1+ (1,0) [0|0] "" Host
 SG_ BATT_boardIO_CAN_WAKE_0 : 0|1@1+ (1,0) [0|1] "" Host

BO_ 2566856695 BATT_boardIO_1: 3 Battery
 SG_ BATT_boardIO_nSD_PWR_AVL_1 : 20|1@1+ (1,0) [0|0] "" Host
 SG_ BATT_boardIO_nL9963_FAULT_1 : 19|1@1+ (1,0) [0|0] "" Host
 SG_ BATT_boardIO_PRE_CHG_FB_1 : 18|1@1+ (1,0) [0|0] "" Host
 SG_ BATT_boardIO_BTN_WAKE_LCH_1 : 17|1@1+ (1,0) [0|0] "" Host
 SG_ BATT_boardIO_BTN_WAKE_1 : 16|1@1+ (1,0) [0|0] "" Host
 SG_ BATT_boardIO_IGN_L_1 : 13|1@1+ (1,0) [0|0] "" Host
 SG_ BATT_boardIO_IGN_H_1 : 12|1@1+ (1,0) [0|0] "" Host
 SG_ BATT_boardIO_EXT_5V_STATUS_1 : 11|1@1+ (1,0) [0|0] "" Host
 SG_ BATT_boardIO_L9963_FAULT_LA_1 : 10|1@1+ (1,0) [0|0] "" Host
 SG_ BATT_boardIO_RTC_WAKE_LA_1 : 9|1@1+ (1,0) [0|0] "" Host
 SG_ BATT_boardIO_CAN_WAKE_LATCH_1 : 8|1@1+ (1,0) [0|0] "" Host
 SG_ BATT_boardIO_DIS_OC_FLT_LA_1 : 5|1@1+ (1,0) [0|1] "" Host
 SG_ BATT_boardIO_RTC_WAKE_LATCH_1 : 4|1@1+ (1,0) [0|0] "" Host
 SG_ BATT_boardIO_L9963_FAULT_1 : 3|1@1+ (1,0) [0|1] "" Host
 SG_ BATT_boardIO_IGN_L_LCH_1 : 2|1@1+ (1,0) [0|0] "" Host
 SG_ BATT_boardIO_IGN_H_LCH_1 : 1|1@1+ (1,0) [0|0] "" Host
 SG_ BATT_boardIO_CAN_WAKE_1 : 0|1@1+ (1,0) [0|1] "" Host

BO_ 2566856696 BATT_boardIO_2: 3 Battery
 SG_ BATT_boardIO_nSD_PWR_AVL_2 : 20|1@1+ (1,0) [0|0] "" Host
 SG_ BATT_boardIO_nL9963_FAULT_2 : 19|1@1+ (1,0) [0|0] "" Host
 SG_ BATT_boardIO_PRE_CHG_FB_2 : 18|1@1+ (1,0) [0|0] "" Host
 SG_ BATT_boardIO_BTN_WAKE_LCH_2 : 17|1@1+ (1,0) [0|0] "" Host
 SG_ BATT_boardIO_BTN_WAKE_2 : 16|1@1+ (1,0) [0|0] "" Host
 SG_ BATT_boardIO_IGN_L_2 : 13|1@1+ (1,0) [0|0] "" Host
 SG_ BATT_boardIO_IGN_H_2 : 12|1@1+ (1,0) [0|0] "" Host
 SG_ BATT_boardIO_EXT_5V_STATUS_2 : 11|1@1+ (1,0) [0|0] "" Host
 SG_ BATT_boardIO_L9963_FAULT_LA_2 : 10|1@1+ (1,0) [0|0] "" Host
 SG_ BATT_boardIO_RTC_WAKE_LA_2 : 9|1@1+ (1,0) [0|0] "" Host
 SG_ BATT_boardIO_CAN_WAKE_LATCH_2 : 8|1@1+ (1,0) [0|0] "" Host
 SG_ BATT_boardIO_DIS_OC_FLT_LA_2 : 5|1@1+ (1,0) [0|1] "" Host
 SG_ BATT_boardIO_RTC_WAKE_LATCH_2 : 4|1@1+ (1,0) [0|0] "" Host
 SG_ BATT_boardIO_L9963_FAULT_2 : 3|1@1+ (1,0) [0|1] "" Host
 SG_ BATT_boardIO_IGN_L_LCH_2 : 2|1@1+ (1,0) [0|0] "" Host
 SG_ BATT_boardIO_IGN_H_LCH_2 : 1|1@1+ (1,0) [0|0] "" Host
 SG_ BATT_boardIO_CAN_WAKE_2 : 0|1@1+ (1,0) [0|1] "" Host

BO_ 2566856697 BATT_boardIO_3: 3 Battery
 SG_ BATT_boardIO_nSD_PWR_AVL_3 : 20|1@1+ (1,0) [0|0] "" Host
 SG_ BATT_boardIO_nL9963_FAULT_3 : 19|1@1+ (1,0) [0|0] "" Host
 SG_ BATT_boardIO_PRE_CHG_FB_3 : 18|1@1+ (1,0) [0|0] "" Host
 SG_ BATT_boardIO_BTN_WAKE_LCH_3 : 17|1@1+ (1,0) [0|0] "" Host
 SG_ BATT_boardIO_BTN_WAKE_3 : 16|1@1+ (1,0) [0|0] "" Host
 SG_ BATT_boardIO_IGN_L_3 : 13|1@1+ (1,0) [0|0] "" Host
 SG_ BATT_boardIO_IGN_H_3 : 12|1@1+ (1,0) [0|0] "" Host
 SG_ BATT_boardIO_EXT_5V_STATUS_3 : 11|1@1+ (1,0) [0|0] "" Host
 SG_ BATT_boardIO_L9963_FAULT_LA_3 : 10|1@1+ (1,0) [0|0] "" Host
 SG_ BATT_boardIO_RTC_WAKE_LA_3 : 9|1@1+ (1,0) [0|0] "" Host
 SG_ BATT_boardIO_CAN_WAKE_LATCH_3 : 8|1@1+ (1,0) [0|0] "" Host
 SG_ BATT_boardIO_DIS_OC_FLT_LA_3 : 5|1@1+ (1,0) [0|1] "" Host
 SG_ BATT_boardIO_RTC_WAKE_LATCH_3 : 4|1@1+ (1,0) [0|0] "" Host
 SG_ BATT_boardIO_L9963_FAULT_3 : 3|1@1+ (1,0) [0|1] "" Host
 SG_ BATT_boardIO_IGN_L_LCH_3 : 2|1@1+ (1,0) [0|0] "" Host
 SG_ BATT_boardIO_IGN_H_LCH_3 : 1|1@1+ (1,0) [0|0] "" Host
 SG_ BATT_boardIO_CAN_WAKE_3 : 0|1@1+ (1,0) [0|1] "" Host

BO_ 2566856698 BATT_boardIO_4: 3 Battery
 SG_ BATT_boardIO_nSD_PWR_AVL_4 : 20|1@1+ (1,0) [0|0] "" Host
 SG_ BATT_boardIO_nL9963_FAULT_4 : 19|1@1+ (1,0) [0|0] "" Host
 SG_ BATT_boardIO_PRE_CHG_FB_4 : 18|1@1+ (1,0) [0|0] "" Host
 SG_ BATT_boardIO_BTN_WAKE_LCH_4 : 17|1@1+ (1,0) [0|0] "" Host
 SG_ BATT_boardIO_BTN_WAKE_4 : 16|1@1+ (1,0) [0|0] "" Host
 SG_ BATT_boardIO_IGN_L_4 : 13|1@1+ (1,0) [0|0] "" Host
 SG_ BATT_boardIO_IGN_H_4 : 12|1@1+ (1,0) [0|0] "" Host
 SG_ BATT_boardIO_EXT_5V_STATUS_4 : 11|1@1+ (1,0) [0|0] "" Host
 SG_ BATT_boardIO_L9963_FAULT_LA_4 : 10|1@1+ (1,0) [0|0] "" Host
 SG_ BATT_boardIO_RTC_WAKE_LA_4 : 9|1@1+ (1,0) [0|0] "" Host
 SG_ BATT_boardIO_CAN_WAKE_LATCH_4 : 8|1@1+ (1,0) [0|0] "" Host
 SG_ BATT_boardIO_DIS_OC_FLT_LA_4 : 5|1@1+ (1,0) [0|1] "" Host
 SG_ BATT_boardIO_RTC_WAKE_LATCH_4 : 4|1@1+ (1,0) [0|0] "" Host
 SG_ BATT_boardIO_L9963_FAULT_4 : 3|1@1+ (1,0) [0|1] "" Host
 SG_ BATT_boardIO_IGN_L_LCH_4 : 2|1@1+ (1,0) [0|0] "" Host
 SG_ BATT_boardIO_IGN_H_LCH_4 : 1|1@1+ (1,0) [0|0] "" Host
 SG_ BATT_boardIO_CAN_WAKE_4 : 0|1@1+ (1,0) [0|1] "" Host

BO_ 2566856699 BATT_boardIO_5: 3 Battery
 SG_ BATT_boardIO_nSD_PWR_AVL_5 : 20|1@1+ (1,0) [0|0] "" Host
 SG_ BATT_boardIO_nL9963_FAULT_5 : 19|1@1+ (1,0) [0|0] "" Host
 SG_ BATT_boardIO_PRE_CHG_FB_5 : 18|1@1+ (1,0) [0|0] "" Host
 SG_ BATT_boardIO_BTN_WAKE_LCH_5 : 17|1@1+ (1,0) [0|0] "" Host
 SG_ BATT_boardIO_BTN_WAKE_5 : 16|1@1+ (1,0) [0|0] "" Host
 SG_ BATT_boardIO_IGN_L_5 : 13|1@1+ (1,0) [0|0] "" Host
 SG_ BATT_boardIO_IGN_H_5 : 12|1@1+ (1,0) [0|0] "" Host
 SG_ BATT_boardIO_EXT_5V_STATUS_5 : 11|1@1+ (1,0) [0|0] "" Host
 SG_ BATT_boardIO_L9963_FAULT_LA_5 : 10|1@1+ (1,0) [0|0] "" Host
 SG_ BATT_boardIO_RTC_WAKE_LA_5 : 9|1@1+ (1,0) [0|0] "" Host
 SG_ BATT_boardIO_CAN_WAKE_LATCH_5 : 8|1@1+ (1,0) [0|0] "" Host
 SG_ BATT_boardIO_DIS_OC_FLT_LA_5 : 5|1@1+ (1,0) [0|1] "" Host
 SG_ BATT_boardIO_RTC_WAKE_LATCH_5 : 4|1@1+ (1,0) [0|0] "" Host
 SG_ BATT_boardIO_L9963_FAULT_5 : 3|1@1+ (1,0) [0|1] "" Host
 SG_ BATT_boardIO_IGN_L_LCH_5 : 2|1@1+ (1,0) [0|0] "" Host
 SG_ BATT_boardIO_IGN_H_LCH_5 : 1|1@1+ (1,0) [0|0] "" Host
 SG_ BATT_boardIO_CAN_WAKE_5 : 0|1@1+ (1,0) [0|1] "" Host

BO_ 2566856700 BATT_boardIO_6: 3 Battery
 SG_ BATT_boardIO_nSD_PWR_AVL_6 : 20|1@1+ (1,0) [0|0] "" Host
 SG_ BATT_boardIO_nL9963_FAULT_6 : 19|1@1+ (1,0) [0|0] "" Host
 SG_ BATT_boardIO_PRE_CHG_FB_6 : 18|1@1+ (1,0) [0|0] "" Host
 SG_ BATT_boardIO_BTN_WAKE_LCH_6 : 17|1@1+ (1,0) [0|0] "" Host
 SG_ BATT_boardIO_BTN_WAKE_6 : 16|1@1+ (1,0) [0|0] "" Host
 SG_ BATT_boardIO_IGN_L_6 : 13|1@1+ (1,0) [0|0] "" Host
 SG_ BATT_boardIO_IGN_H_6 : 12|1@1+ (1,0) [0|0] "" Host
 SG_ BATT_boardIO_EXT_5V_STATUS_6 : 11|1@1+ (1,0) [0|0] "" Host
 SG_ BATT_boardIO_L9963_FAULT_LA_6 : 10|1@1+ (1,0) [0|0] "" Host
 SG_ BATT_boardIO_RTC_WAKE_LA_6 : 9|1@1+ (1,0) [0|0] "" Host
 SG_ BATT_boardIO_CAN_WAKE_LATCH_6 : 8|1@1+ (1,0) [0|0] "" Host
 SG_ BATT_boardIO_DIS_OC_FLT_LA_6 : 5|1@1+ (1,0) [0|1] "" Host
 SG_ BATT_boardIO_RTC_WAKE_LATCH_6 : 4|1@1+ (1,0) [0|0] "" Host
 SG_ BATT_boardIO_L9963_FAULT_6 : 3|1@1+ (1,0) [0|1] "" Host
 SG_ BATT_boardIO_IGN_L_LCH_6 : 2|1@1+ (1,0) [0|0] "" Host
 SG_ BATT_boardIO_IGN_H_LCH_6 : 1|1@1+ (1,0) [0|0] "" Host
 SG_ BATT_boardIO_CAN_WAKE_6 : 0|1@1+ (1,0) [0|1] "" Host

BO_ 2566856701 BATT_boardIO_7: 3 Battery
 SG_ BATT_boardIO_nSD_PWR_AVL_7 : 20|1@1+ (1,0) [0|0] "" Host
 SG_ BATT_boardIO_nL9963_FAULT_7 : 19|1@1+ (1,0) [0|0] "" Host
 SG_ BATT_boardIO_PRE_CHG_FB_7 : 18|1@1+ (1,0) [0|0] "" Host
 SG_ BATT_boardIO_BTN_WAKE_LCH_7 : 17|1@1+ (1,0) [0|0] "" Host
 SG_ BATT_boardIO_BTN_WAKE_7 : 16|1@1+ (1,0) [0|0] "" Host
 SG_ BATT_boardIO_IGN_L_7 : 13|1@1+ (1,0) [0|0] "" Host
 SG_ BATT_boardIO_IGN_H_7 : 12|1@1+ (1,0) [0|0] "" Host
 SG_ BATT_boardIO_EXT_5V_STATUS_7 : 11|1@1+ (1,0) [0|0] "" Host
 SG_ BATT_boardIO_L9963_FAULT_LA_7 : 10|1@1+ (1,0) [0|0] "" Host
 SG_ BATT_boardIO_RTC_WAKE_LA_7 : 9|1@1+ (1,0) [0|0] "" Host
 SG_ BATT_boardIO_CAN_WAKE_LATCH_7 : 8|1@1+ (1,0) [0|0] "" Host
 SG_ BATT_boardIO_DIS_OC_FLT_LA_7 : 5|1@1+ (1,0) [0|1] "" Host
 SG_ BATT_boardIO_RTC_WAKE_LATCH_7 : 4|1@1+ (1,0) [0|0] "" Host
 SG_ BATT_boardIO_L9963_FAULT_7 : 3|1@1+ (1,0) [0|1] "" Host
 SG_ BATT_boardIO_IGN_L_LCH_7 : 2|1@1+ (1,0) [0|0] "" Host
 SG_ BATT_boardIO_IGN_H_LCH_7 : 1|1@1+ (1,0) [0|0] "" Host
 SG_ BATT_boardIO_CAN_WAKE_7 : 0|1@1+ (1,0) [0|1] "" Host

BO_ 2566856702 BATT_boardIO_8: 3 Battery
 SG_ BATT_boardIO_nSD_PWR_AVL_8 : 20|1@1+ (1,0) [0|0] "" Host
 SG_ BATT_boardIO_nL9963_FAULT_8 : 19|1@1+ (1,0) [0|0] "" Host
 SG_ BATT_boardIO_PRE_CHG_FB_8 : 18|1@1+ (1,0) [0|0] "" Host
 SG_ BATT_boardIO_BTN_WAKE_LCH_8 : 17|1@1+ (1,0) [0|0] "" Host
 SG_ BATT_boardIO_BTN_WAKE_8 : 16|1@1+ (1,0) [0|0] "" Host
 SG_ BATT_boardIO_IGN_L_8 : 13|1@1+ (1,0) [0|0] "" Host
 SG_ BATT_boardIO_IGN_H_8 : 12|1@1+ (1,0) [0|0] "" Host
 SG_ BATT_boardIO_EXT_5V_STATUS_8 : 11|1@1+ (1,0) [0|0] "" Host
 SG_ BATT_boardIO_L9963_FAULT_LA_8 : 10|1@1+ (1,0) [0|0] "" Host
 SG_ BATT_boardIO_RTC_WAKE_LA_8 : 9|1@1+ (1,0) [0|0] "" Host
 SG_ BATT_boardIO_CAN_WAKE_LATCH_8 : 8|1@1+ (1,0) [0|0] "" Host
 SG_ BATT_boardIO_DIS_OC_FLT_LA_8 : 5|1@1+ (1,0) [0|1] "" Host
 SG_ BATT_boardIO_RTC_WAKE_LATCH_8 : 4|1@1+ (1,0) [0|0] "" Host
 SG_ BATT_boardIO_L9963_FAULT_8 : 3|1@1+ (1,0) [0|1] "" Host
 SG_ BATT_boardIO_IGN_L_LCH_8 : 2|1@1+ (1,0) [0|0] "" Host
 SG_ BATT_boardIO_IGN_H_LCH_8 : 1|1@1+ (1,0) [0|0] "" Host
 SG_ BATT_boardIO_CAN_WAKE_8 : 0|1@1+ (1,0) [0|1] "" Host

BO_ 2566856703 BATT_boardIO_9: 3 Battery
 SG_ BATT_boardIO_nSD_PWR_AVL_9 : 20|1@1+ (1,0) [0|0] "" Host
 SG_ BATT_boardIO_nL9963_FAULT_9 : 19|1@1+ (1,0) [0|0] "" Host
 SG_ BATT_boardIO_PRE_CHG_FB_9 : 18|1@1+ (1,0) [0|0] "" Host
 SG_ BATT_boardIO_BTN_WAKE_LCH_9 : 17|1@1+ (1,0) [0|0] "" Host
 SG_ BATT_boardIO_BTN_WAKE_9 : 16|1@1+ (1,0) [0|0] "" Host
 SG_ BATT_boardIO_IGN_L_9 : 13|1@1+ (1,0) [0|0] "" Host
 SG_ BATT_boardIO_IGN_H_9 : 12|1@1+ (1,0) [0|0] "" Host
 SG_ BATT_boardIO_EXT_5V_STATUS_9 : 11|1@1+ (1,0) [0|0] "" Host
 SG_ BATT_boardIO_L9963_FAULT_LA_9 : 10|1@1+ (1,0) [0|0] "" Host
 SG_ BATT_boardIO_RTC_WAKE_LA_9 : 9|1@1+ (1,0) [0|0] "" Host
 SG_ BATT_boardIO_CAN_WAKE_LATCH_9 : 8|1@1+ (1,0) [0|0] "" Host
 SG_ BATT_boardIO_DIS_OC_FLT_LA_9 : 5|1@1+ (1,0) [0|1] "" Host
 SG_ BATT_boardIO_RTC_WAKE_LATCH_9 : 4|1@1+ (1,0) [0|0] "" Host
 SG_ BATT_boardIO_L9963_FAULT_9 : 3|1@1+ (1,0) [0|1] "" Host
 SG_ BATT_boardIO_IGN_L_LCH_9 : 2|1@1+ (1,0) [0|0] "" Host
 SG_ BATT_boardIO_IGN_H_LCH_9 : 1|1@1+ (1,0) [0|0] "" Host
 SG_ BATT_boardIO_CAN_WAKE_9 : 0|1@1+ (1,0) [0|1] "" Host

BO_ 2566857718 BATT_diagnosticSOHRBricksC: 8 Battery
 SG_ BATT_sohrBrick12 : 48|16@1+ (0.00075,0) [0|49.15125] "Ah" Host
 SG_ BATT_sohrBrick11 : 32|16@1+ (0.00075,0) [0|49.15125] "Ah" Host
 SG_ BATT_sohrBrick10 : 16|16@1+ (0.00075,0) [0|49.15125] "Ah" Host
 SG_ BATT_sohrBrick09 : 0|16@1+ (0.00075,0) [0|49.15125] "Ah" Host

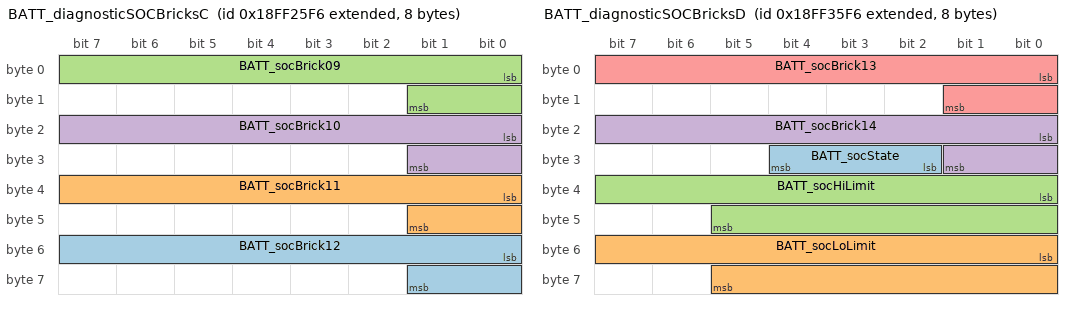
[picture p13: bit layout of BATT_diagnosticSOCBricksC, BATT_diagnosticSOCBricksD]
BO_ 2566858230 BATT_diagnosticSOCBricksC: 8 Battery
 SG_ BATT_socBrick12 : 48|10@1+ (0.1,0) [0|102.3] "%" Host
 SG_ BATT_socBrick11 : 32|10@1+ (0.1,0) [0|102.3] "%" Host
 SG_ BATT_socBrick09 : 0|10@1+ (0.1,0) [0|102.3] "%" Host
 SG_ BATT_socBrick10 : 16|10@1+ (0.1,0) [0|102.3] "%" Host

BO_ 2566858486 BATT_diagnosticCapBricksC_0: 8 Battery
 SG_ BATT_capBrick12_0 : 48|16@1+ (0.0025,0) [0|163.8375] "Ah" Host
 SG_ BATT_capBrick11_0 : 32|16@1+ (0.0025,0) [0|163.8375] "Ah" Host
 SG_ BATT_capBrick09_0 : 0|16@1+ (0.0025,0) [0|163.8375] "Ah" Host
 SG_ BATT_capBrick10_0 : 16|16@1+ (0.0025,0) [0|163.8375] "Ah" Host

BO_ 2566858487 BATT_diagnosticCapBricksC_1: 8 Battery
 SG_ BATT_capBrick12_1 : 48|16@1+ (0.0025,0) [0|163.8375] "Ah" Host
 SG_ BATT_capBrick11_1 : 32|16@1+ (0.0025,0) [0|163.8375] "Ah" Host
 SG_ BATT_capBrick09_1 : 0|16@1+ (0.0025,0) [0|163.8375] "Ah" Host
 SG_ BATT_capBrick10_1 : 16|16@1+ (0.0025,0) [0|163.8375] "Ah" Host

BO_ 2566858488 BATT_diagnosticCapBricksC_2: 8 Battery
 SG_ BATT_capBrick12_2 : 48|16@1+ (0.0025,0) [0|163.8375] "Ah" Host
 SG_ BATT_capBrick11_2 : 32|16@1+ (0.0025,0) [0|163.8375] "Ah" Host
 SG_ BATT_capBrick09_2 : 0|16@1+ (0.0025,0) [0|163.8375] "Ah" Host
 SG_ BATT_capBrick10_2 : 16|16@1+ (0.0025,0) [0|163.8375] "Ah" Host

BO_ 2566858489 BATT_diagnosticCapBricksC_3: 8 Battery
 SG_ BATT_capBrick12_3 : 48|16@1+ (0.0025,0) [0|163.8375] "Ah" Host
 SG_ BATT_capBrick11_3 : 32|16@1+ (0.0025,0) [0|163.8375] "Ah" Host
 SG_ BATT_capBrick09_3 : 0|16@1+ (0.0025,0) [0|163.8375] "Ah" Host
 SG_ BATT_capBrick10_3 : 16|16@1+ (0.0025,0) [0|163.8375] "Ah" Host

BO_ 2566858490 BATT_diagnosticCapBricksC_4: 8 Battery
 SG_ BATT_capBrick12_4 : 48|16@1+ (0.0025,0) [0|163.8375] "Ah" Host
 SG_ BATT_capBrick11_4 : 32|16@1+ (0.0025,0) [0|163.8375] "Ah" Host
 SG_ BATT_capBrick09_4 : 0|16@1+ (0.0025,0) [0|163.8375] "Ah" Host
 SG_ BATT_capBrick10_4 : 16|16@1+ (0.0025,0) [0|163.8375] "Ah" Host

BO_ 2566858491 BATT_diagnosticCapBricksC_5: 8 Battery
 SG_ BATT_capBrick12_5 : 48|16@1+ (0.0025,0) [0|163.8375] "Ah" Host
 SG_ BATT_capBrick11_5 : 32|16@1+ (0.0025,0) [0|163.8375] "Ah" Host
 SG_ BATT_capBrick09_5 : 0|16@1+ (0.0025,0) [0|163.8375] "Ah" Host
 SG_ BATT_capBrick10_5 : 16|16@1+ (0.0025,0) [0|163.8375] "Ah" Host

BO_ 2566858492 BATT_diagnosticCapBricksC_6: 8 Battery
 SG_ BATT_capBrick12_6 : 48|16@1+ (0.0025,0) [0|163.8375] "Ah" Host
 SG_ BATT_capBrick11_6 : 32|16@1+ (0.0025,0) [0|163.8375] "Ah" Host
 SG_ BATT_capBrick09_6 : 0|16@1+ (0.0025,0) [0|163.8375] "Ah" Host
 SG_ BATT_capBrick10_6 : 16|16@1+ (0.0025,0) [0|163.8375] "Ah" Host

BO_ 2566858493 BATT_diagnosticCapBricksC_7: 8 Battery
 SG_ BATT_capBrick12_7 : 48|16@1+ (0.0025,0) [0|163.8375] "Ah" Host
 SG_ BATT_capBrick11_7 : 32|16@1+ (0.0025,0) [0|163.8375] "Ah" Host
 SG_ BATT_capBrick09_7 : 0|16@1+ (0.0025,0) [0|163.8375] "Ah" Host
 SG_ BATT_capBrick10_7 : 16|16@1+ (0.0025,0) [0|163.8375] "Ah" Host

BO_ 2566858494 BATT_diagnosticCapBricksC_8: 8 Battery
 SG_ BATT_capBrick12_8 : 48|16@1+ (0.0025,0) [0|163.8375] "Ah" Host
 SG_ BATT_capBrick11_8 : 32|16@1+ (0.0025,0) [0|163.8375] "Ah" Host
 SG_ BATT_capBrick09_8 : 0|16@1+ (0.0025,0) [0|163.8375] "Ah" Host
 SG_ BATT_capBrick10_8 : 16|16@1+ (0.0025,0) [0|163.8375] "Ah" Host

BO_ 2566858495 BATT_diagnosticCapBricksC_9: 8 Battery
 SG_ BATT_capBrick12_9 : 48|16@1+ (0.0025,0) [0|163.8375] "Ah" Host
 SG_ BATT_capBrick11_9 : 32|16@1+ (0.0025,0) [0|163.8375] "Ah" Host
 SG_ BATT_capBrick09_9 : 0|16@1+ (0.0025,0) [0|163.8375] "Ah" Host
 SG_ BATT_capBrick10_9 : 16|16@1+ (0.0025,0) [0|163.8375] "Ah" Host

BO_ 2566858742 BATT_diagnosticVBricksC_0: 8 Battery
 SG_ BATT_vBrick12_0 : 48|16@1+ (7.6e-05,0) [0|4.98066] "V" Host
 SG_ BATT_vBrick11_0 : 32|16@1+ (7.6e-05,0) [0|4.98066] "V" Host
 SG_ BATT_vBrick10_0 : 16|16@1+ (7.6e-05,0) [0|4.98066] "V" Host
 SG_ BATT_vBrick09_0 : 0|16@1+ (7.6e-05,0) [0|4.98066] "V" Host

BO_ 2566858743 BATT_diagnosticVBricksC_1: 8 Battery
 SG_ BATT_vBrick12_1 : 48|16@1+ (7.6e-05,0) [0|4.98066] "V" Host
 SG_ BATT_vBrick11_1 : 32|16@1+ (7.6e-05,0) [0|4.98066] "V" Host
 SG_ BATT_vBrick10_1 : 16|16@1+ (7.6e-05,0) [0|4.98066] "V" Host
 SG_ BATT_vBrick09_1 : 0|16@1+ (7.6e-05,0) [0|4.98066] "V" Host

BO_ 2566858744 BATT_diagnosticVBricksC_2: 8 Battery
 SG_ BATT_vBrick12_2 : 48|16@1+ (7.6e-05,0) [0|4.98066] "V" Host
 SG_ BATT_vBrick11_2 : 32|16@1+ (7.6e-05,0) [0|4.98066] "V" Host
 SG_ BATT_vBrick10_2 : 16|16@1+ (7.6e-05,0) [0|4.98066] "V" Host
 SG_ BATT_vBrick09_2 : 0|16@1+ (7.6e-05,0) [0|4.98066] "V" Host

BO_ 2566858745 BATT_diagnosticVBricksC_3: 8 Battery
 SG_ BATT_vBrick12_3 : 48|16@1+ (7.6e-05,0) [0|4.98066] "V" Host
 SG_ BATT_vBrick11_3 : 32|16@1+ (7.6e-05,0) [0|4.98066] "V" Host
 SG_ BATT_vBrick10_3 : 16|16@1+ (7.6e-05,0) [0|4.98066] "V" Host
 SG_ BATT_vBrick09_3 : 0|16@1+ (7.6e-05,0) [0|4.98066] "V" Host

BO_ 2566858746 BATT_diagnosticVBricksC_4: 8 Battery
 SG_ BATT_vBrick12_4 : 48|16@1+ (7.6e-05,0) [0|4.98066] "V" Host
 SG_ BATT_vBrick11_4 : 32|16@1+ (7.6e-05,0) [0|4.98066] "V" Host
 SG_ BATT_vBrick10_4 : 16|16@1+ (7.6e-05,0) [0|4.98066] "V" Host
 SG_ BATT_vBrick09_4 : 0|16@1+ (7.6e-05,0) [0|4.98066] "V" Host

BO_ 2566858747 BATT_diagnosticVBricksC_5: 8 Battery
 SG_ BATT_vBrick12_5 : 48|16@1+ (7.6e-05,0) [0|4.98066] "V" Host
 SG_ BATT_vBrick11_5 : 32|16@1+ (7.6e-05,0) [0|4.98066] "V" Host
 SG_ BATT_vBrick10_5 : 16|16@1+ (7.6e-05,0) [0|4.98066] "V" Host
 SG_ BATT_vBrick09_5 : 0|16@1+ (7.6e-05,0) [0|4.98066] "V" Host

BO_ 2566858748 BATT_diagnosticVBricksC_6: 8 Battery
 SG_ BATT_vBrick12_6 : 48|16@1+ (7.6e-05,0) [0|4.98066] "V" Host
 SG_ BATT_vBrick11_6 : 32|16@1+ (7.6e-05,0) [0|4.98066] "V" Host
 SG_ BATT_vBrick10_6 : 16|16@1+ (7.6e-05,0) [0|4.98066] "V" Host
 SG_ BATT_vBrick09_6 : 0|16@1+ (7.6e-05,0) [0|4.98066] "V" Host

BO_ 2566858749 BATT_diagnosticVBricksC_7: 8 Battery
 SG_ BATT_vBrick12_7 : 48|16@1+ (7.6e-05,0) [0|4.98066] "V" Host
 SG_ BATT_vBrick11_7 : 32|16@1+ (7.6e-05,0) [0|4.98066] "V" Host
 SG_ BATT_vBrick10_7 : 16|16@1+ (7.6e-05,0) [0|4.98066] "V" Host
 SG_ BATT_vBrick09_7 : 0|16@1+ (7.6e-05,0) [0|4.98066] "V" Host

BO_ 2566858750 BATT_diagnosticVBricksC_8: 8 Battery
 SG_ BATT_vBrick12_8 : 48|16@1+ (7.6e-05,0) [0|4.98066] "V" Host
 SG_ BATT_vBrick11_8 : 32|16@1+ (7.6e-05,0) [0|4.98066] "V" Host
 SG_ BATT_vBrick10_8 : 16|16@1+ (7.6e-05,0) [0|4.98066] "V" Host
 SG_ BATT_vBrick09_8 : 0|16@1+ (7.6e-05,0) [0|4.98066] "V" Host

BO_ 2566858751 BATT_diagnosticVBricksC_9: 8 Battery
 SG_ BATT_vBrick12_9 : 48|16@1+ (7.6e-05,0) [0|4.98066] "V" Host
 SG_ BATT_vBrick11_9 : 32|16@1+ (7.6e-05,0) [0|4.98066] "V" Host
 SG_ BATT_vBrick10_9 : 16|16@1+ (7.6e-05,0) [0|4.98066] "V" Host
 SG_ BATT_vBrick09_9 : 0|16@1+ (7.6e-05,0) [0|4.98066] "V" Host

BO_ 2566858998 BATT_diagnosticResBricksC: 8 Battery
 SG_ BATT_resBrick12 : 48|16@1+ (0.01,0) [0|655.35] "mOhms" Host
 SG_ BATT_resBrick11 : 32|16@1+ (0.01,0) [0|655.35] "mOhms" Host
 SG_ BATT_resBrick09 : 0|16@1+ (0.01,0) [0|655.35] "mOhms" Host
 SG_ BATT_resBrick10 : 16|16@1+ (0.01,0) [0|655.35] "mOhms" Host

BO_ 2566861814 BATT_diagnosticSOHRBricksD: 4 Battery
 SG_ BATT_sohrBrick14 : 16|16@1+ (0.00075,0) [0|49.15125] "Ah" Host
 SG_ BATT_sohrBrick13 : 0|16@1+ (0.00075,0) [0|49.15125] "Ah" Host

BO_ 2566862326 BATT_diagnosticSOCBricksD: 8 Battery
 SG_ BATT_socState : 26|3@1+ (1,0) [0|7] "" Host
 SG_ BATT_socLoLimit : 48|14@1+ (1,0) [0|16383] "" Host
 SG_ BATT_socHiLimit : 32|14@1+ (1,0) [0|16383] "" Host
 SG_ BATT_socBrick14 : 16|10@1+ (0.1,0) [0|102.3] "%" Host
 SG_ BATT_socBrick13 : 0|10@1+ (0.1,0) [0|102.3] "%" Host

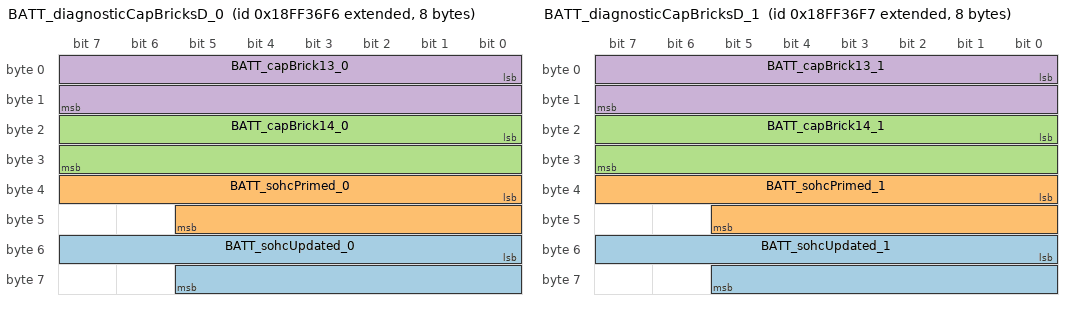
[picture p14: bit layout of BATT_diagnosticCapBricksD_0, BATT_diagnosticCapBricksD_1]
BO_ 2566862582 BATT_diagnosticCapBricksD_0: 8 Battery
 SG_ BATT_sohcUpdated_0 : 48|14@1+ (1,0) [0|16383] "" Host
 SG_ BATT_sohcPrimed_0 : 32|14@1+ (1,0) [0|16383] "" Host
 SG_ BATT_capBrick14_0 : 16|16@1+ (0.0025,0) [0|163.8375] "Ah" Host
 SG_ BATT_capBrick13_0 : 0|16@1+ (0.0025,0) [0|163.8375] "Ah" Host

BO_ 2566862583 BATT_diagnosticCapBricksD_1: 8 Battery
 SG_ BATT_sohcUpdated_1 : 48|14@1+ (1,0) [0|16383] "" Host
 SG_ BATT_sohcPrimed_1 : 32|14@1+ (1,0) [0|16383] "" Host
 SG_ BATT_capBrick14_1 : 16|16@1+ (0.0025,0) [0|163.8375] "Ah" Host
 SG_ BATT_capBrick13_1 : 0|16@1+ (0.0025,0) [0|163.8375] "Ah" Host

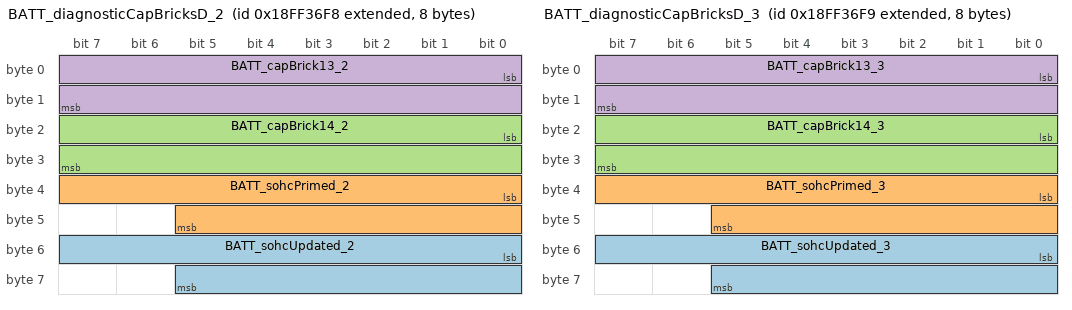
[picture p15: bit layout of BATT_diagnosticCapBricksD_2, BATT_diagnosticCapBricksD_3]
BO_ 2566862584 BATT_diagnosticCapBricksD_2: 8 Battery
 SG_ BATT_sohcUpdated_2 : 48|14@1+ (1,0) [0|16383] "" Host
 SG_ BATT_sohcPrimed_2 : 32|14@1+ (1,0) [0|16383] "" Host
 SG_ BATT_capBrick14_2 : 16|16@1+ (0.0025,0) [0|163.8375] "Ah" Host
 SG_ BATT_capBrick13_2 : 0|16@1+ (0.0025,0) [0|163.8375] "Ah" Host

BO_ 2566862585 BATT_diagnosticCapBricksD_3: 8 Battery
 SG_ BATT_sohcUpdated_3 : 48|14@1+ (1,0) [0|16383] "" Host
 SG_ BATT_sohcPrimed_3 : 32|14@1+ (1,0) [0|16383] "" Host
 SG_ BATT_capBrick14_3 : 16|16@1+ (0.0025,0) [0|163.8375] "Ah" Host
 SG_ BATT_capBrick13_3 : 0|16@1+ (0.0025,0) [0|163.8375] "Ah" Host

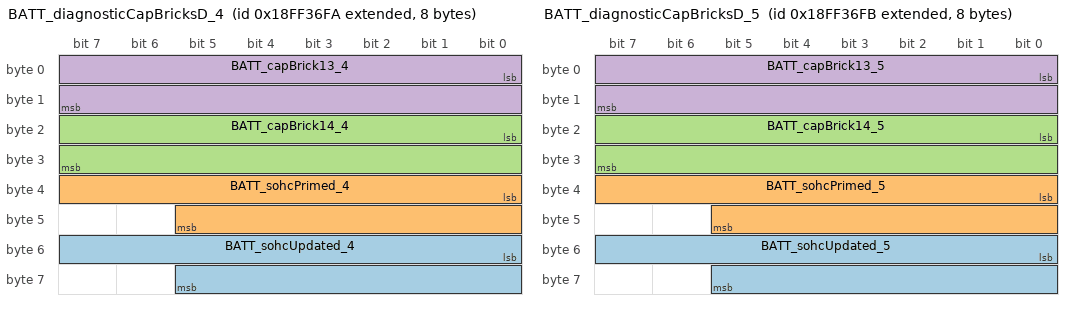
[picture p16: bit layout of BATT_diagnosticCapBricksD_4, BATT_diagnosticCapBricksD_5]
BO_ 2566862586 BATT_diagnosticCapBricksD_4: 8 Battery
 SG_ BATT_sohcUpdated_4 : 48|14@1+ (1,0) [0|16383] "" Host
 SG_ BATT_sohcPrimed_4 : 32|14@1+ (1,0) [0|16383] "" Host
 SG_ BATT_capBrick14_4 : 16|16@1+ (0.0025,0) [0|163.8375] "Ah" Host
 SG_ BATT_capBrick13_4 : 0|16@1+ (0.0025,0) [0|163.8375] "Ah" Host

BO_ 2566862587 BATT_diagnosticCapBricksD_5: 8 Battery
 SG_ BATT_sohcUpdated_5 : 48|14@1+ (1,0) [0|16383] "" Host
 SG_ BATT_sohcPrimed_5 : 32|14@1+ (1,0) [0|16383] "" Host
 SG_ BATT_capBrick14_5 : 16|16@1+ (0.0025,0) [0|163.8375] "Ah" Host
 SG_ BATT_capBrick13_5 : 0|16@1+ (0.0025,0) [0|163.8375] "Ah" Host

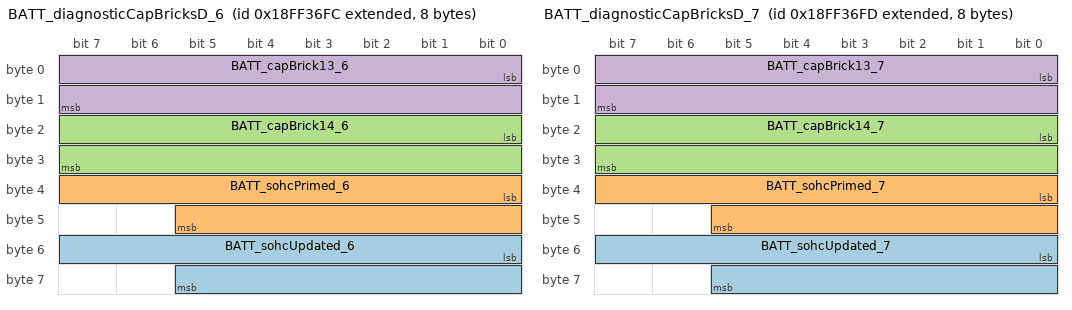
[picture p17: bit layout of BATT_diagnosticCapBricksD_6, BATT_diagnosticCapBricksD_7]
BO_ 2566862588 BATT_diagnosticCapBricksD_6: 8 Battery
 SG_ BATT_sohcUpdated_6 : 48|14@1+ (1,0) [0|16383] "" Host
 SG_ BATT_sohcPrimed_6 : 32|14@1+ (1,0) [0|16383] "" Host
 SG_ BATT_capBrick14_6 : 16|16@1+ (0.0025,0) [0|163.8375] "Ah" Host
 SG_ BATT_capBrick13_6 : 0|16@1+ (0.0025,0) [0|163.8375] "Ah" Host

BO_ 2566862589 BATT_diagnosticCapBricksD_7: 8 Battery
 SG_ BATT_sohcUpdated_7 : 48|14@1+ (1,0) [0|16383] "" Host
 SG_ BATT_sohcPrimed_7 : 32|14@1+ (1,0) [0|16383] "" Host
 SG_ BATT_capBrick14_7 : 16|16@1+ (0.0025,0) [0|163.8375] "Ah" Host
 SG_ BATT_capBrick13_7 : 0|16@1+ (0.0025,0) [0|163.8375] "Ah" Host

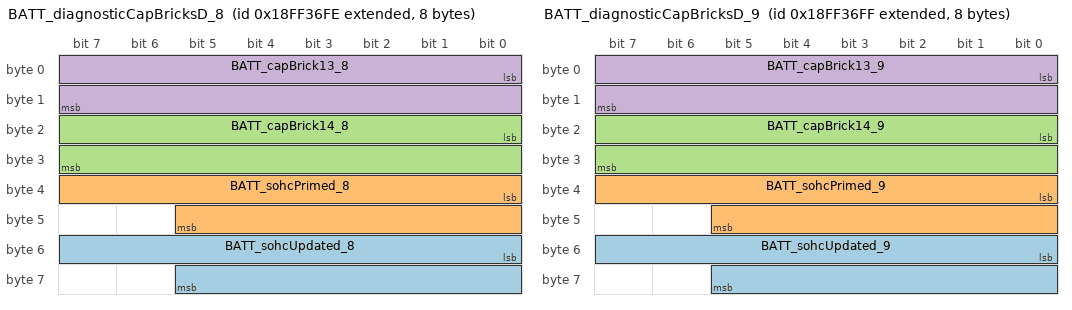
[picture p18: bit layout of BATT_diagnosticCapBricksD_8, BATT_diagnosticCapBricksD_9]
BO_ 2566862590 BATT_diagnosticCapBricksD_8: 8 Battery
 SG_ BATT_sohcUpdated_8 : 48|14@1+ (1,0) [0|16383] "" Host
 SG_ BATT_sohcPrimed_8 : 32|14@1+ (1,0) [0|16383] "" Host
 SG_ BATT_capBrick14_8 : 16|16@1+ (0.0025,0) [0|163.8375] "Ah" Host
 SG_ BATT_capBrick13_8 : 0|16@1+ (0.0025,0) [0|163.8375] "Ah" Host

BO_ 2566862591 BATT_diagnosticCapBricksD_9: 8 Battery
 SG_ BATT_sohcUpdated_9 : 48|14@1+ (1,0) [0|16383] "" Host
 SG_ BATT_sohcPrimed_9 : 32|14@1+ (1,0) [0|16383] "" Host
 SG_ BATT_capBrick14_9 : 16|16@1+ (0.0025,0) [0|163.8375] "Ah" Host
 SG_ BATT_capBrick13_9 : 0|16@1+ (0.0025,0) [0|163.8375] "Ah" Host

BO_ 2566862838 BATT_diagnosticVBricksD_0: 4 Battery
 SG_ BATT_vBrick14_0 : 16|16@1+ (7.6e-05,0) [0|4.98066] "V" Host
 SG_ BATT_vBrick13_0 : 0|16@1+ (7.6e-05,0) [0|4.98066] "V" Host

BO_ 2566862839 BATT_diagnosticVBricksD_1: 4 Battery
 SG_ BATT_vBrick14_1 : 16|16@1+ (7.6e-05,0) [0|4.98066] "V" Host
 SG_ BATT_vBrick13_1 : 0|16@1+ (7.6e-05,0) [0|4.98066] "V" Host

BO_ 2566862840 BATT_diagnosticVBricksD_2: 4 Battery
 SG_ BATT_vBrick14_2 : 16|16@1+ (7.6e-05,0) [0|4.98066] "V" Host
 SG_ BATT_vBrick13_2 : 0|16@1+ (7.6e-05,0) [0|4.98066] "V" Host

BO_ 2566862841 BATT_diagnosticVBricksD_3: 4 Battery
 SG_ BATT_vBrick14_3 : 16|16@1+ (7.6e-05,0) [0|4.98066] "V" Host
 SG_ BATT_vBrick13_3 : 0|16@1+ (7.6e-05,0) [0|4.98066] "V" Host

BO_ 2566862842 BATT_diagnosticVBricksD_4: 4 Battery
 SG_ BATT_vBrick14_4 : 16|16@1+ (7.6e-05,0) [0|4.98066] "V" Host
 SG_ BATT_vBrick13_4 : 0|16@1+ (7.6e-05,0) [0|4.98066] "V" Host

BO_ 2566862843 BATT_diagnosticVBricksD_5: 4 Battery
 SG_ BATT_vBrick14_5 : 16|16@1+ (7.6e-05,0) [0|4.98066] "V" Host
 SG_ BATT_vBrick13_5 : 0|16@1+ (7.6e-05,0) [0|4.98066] "V" Host

BO_ 2566862844 BATT_diagnosticVBricksD_6: 4 Battery
 SG_ BATT_vBrick14_6 : 16|16@1+ (7.6e-05,0) [0|4.98066] "V" Host
 SG_ BATT_vBrick13_6 : 0|16@1+ (7.6e-05,0) [0|4.98066] "V" Host

BO_ 2566862845 BATT_diagnosticVBricksD_7: 4 Battery
 SG_ BATT_vBrick14_7 : 16|16@1+ (7.6e-05,0) [0|4.98066] "V" Host
 SG_ BATT_vBrick13_7 : 0|16@1+ (7.6e-05,0) [0|4.98066] "V" Host

BO_ 2566862846 BATT_diagnosticVBricksD_8: 4 Battery
 SG_ BATT_vBrick14_8 : 16|16@1+ (7.6e-05,0) [0|4.98066] "V" Host
 SG_ BATT_vBrick13_8 : 0|16@1+ (7.6e-05,0) [0|4.98066] "V" Host

BO_ 2566862847 BATT_diagnosticVBricksD_9: 4 Battery
 SG_ BATT_vBrick14_9 : 16|16@1+ (7.6e-05,0) [0|4.98066] "V" Host
 SG_ BATT_vBrick13_9 : 0|16@1+ (7.6e-05,0) [0|4.98066] "V" Host

BO_ 2566863094 BATT_diagnosticResBricksD: 4 Battery
 SG_ BATT_resBrick14 : 16|16@1+ (0.01,0) [0|655.35] "mOhms" Host
 SG_ BATT_resBrick13 : 0|16@1+ (0.01,0) [0|655.35] "mOhms" Host

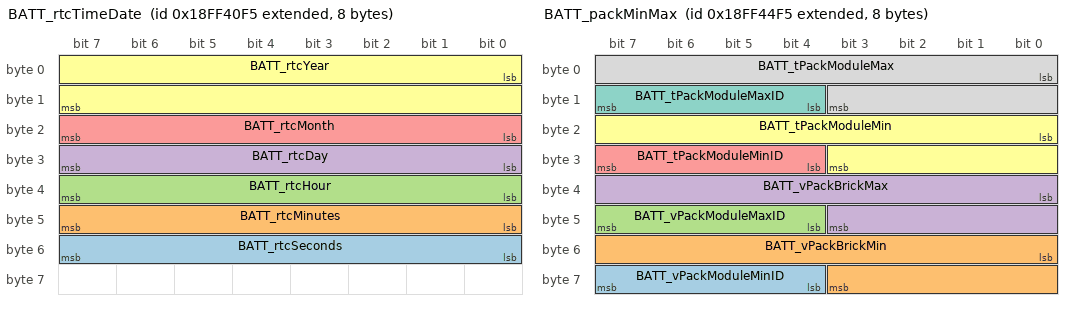
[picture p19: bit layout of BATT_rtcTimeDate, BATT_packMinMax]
BO_ 2566865141 BATT_rtcTimeDate: 8 Battery
 SG_ BATT_rtcSeconds : 48|8@1+ (1,0) [0|59] "" Host
 SG_ BATT_rtcMinutes : 40|8@1+ (1,0) [0|59] "" Host
 SG_ BATT_rtcHour : 32|8@1+ (1,0) [0|23] "" Host
 SG_ BATT_rtcDay : 24|8@1+ (1,0) [1|31] "" Host
 SG_ BATT_rtcMonth : 16|8@1+ (1,0) [1|12] "" Host
 SG_ BATT_rtcYear : 0|16@1+ (1,0) [2016|2099] "" Host

BO_ 2566865397 BATT_packHvStatus: 8 Battery
 SG_ BATT_iPackFiltered : 48|16@1- (0.05,0) [-1638.4|1638.35] "A" Host
 SG_ BATT_vPack : 32|16@1+ (0.01,0) [0|70] "V" Host
 SG_ BATT_vPackLoad : 0|16@1+ (0.01,0) [0|70] "V" Host
 SG_ BATT_iPack : 16|16@1- (0.04,0) [-1310.72|1310.68] "A" Host

BO_ 2566866165 BATT_packMinMax: 8 Battery
 SG_ BATT_vPackModuleMinID : 60|4@1+ (1,0) [0|10] "" Host
 SG_ BATT_vPackBrickMin : 48|12@1+ (0.002,0) [0|4.98066] "V" Host
 SG_ BATT_vPackModuleMaxID : 44|4@1+ (1,0) [0|10] "" Host
 SG_ BATT_vPackBrickMax : 32|12@1+ (0.002,0) [0|4.98066] "V" Host
 SG_ BATT_tPackModuleMinID : 28|4@1+ (1,0) [0|10] "" Host
 SG_ BATT_tPackModuleMin : 16|12@1- (0.1,0) [-40|125] "deg C" Host
 SG_ BATT_tPackModuleMaxID : 12|4@1+ (1,0) [0|10] "" Host
 SG_ BATT_tPackModuleMax : 0|12@1- (0.1,0) [-40|125] "deg C" Host

CM_ BO_ 2566852863 "Message with flags from event matrix";
CM_ SG_ 2566852863 BATT_packModIdFault_9 "0 - Battery pack module ID okay (default)
1 - Battery pack module ID fault";
CM_ SG_ 2566852863 BATT_packModExitedFromBus_9 "0 - Battery pack modules OK (default)
1 - Battery pack module(s) exited from the bus during charge or drive";
CM_ SG_ 2566852863 BATT_packFetChgWelded_9 "0 - Battery pack module CHG FETs not welded (default)
1 - Battery pack module CHG FETs welded ";
CM_ SG_ 2566852863 BATT_packFetDsgWelded_9 "0 - Battery pack module DSG FETs not welded (default)
1 - Battery pack module DSG FETs welded ";
CM_ SG_ 2566852863 BATT_fetDsgShortedAux_9 "0 - FETs are operational (default)
1 - FET is shorted detected by auxiliary diagnostic";
CM_ SG_ 2566852863 BATT_fetChgShortedAux_9 "0 - FETs are operational (default)
1 - FET is shorted detected by auxiliary diagnostic";
CM_ SG_ 2566852863 BATT_prechargeFetFail_9 "0 - Precharge FET okay (default)
1 - Precharge FET failed";
CM_ SG_ 2566852863 BATT_abnormalResetReason_9 "0 - Reset reason okay (default)
1 - Abnormal reset reason";
CM_ SG_ 2566852863 BATT_prechargeTooSlow_9 "0 - Precharge okay (default)
1 - Precharge too slow";
CM_ SG_ 2566852863 BATT_prechargeTooFast_9 "0 - Precharge okay (default)
1 - Precharge too fast";
CM_ SG_ 2566852863 BATT_prechargeTimeout_9 "0 - Precharge okay (default)
1 - Precharge timeout";
CM_ SG_ 2566852863 BATT_fetChgShorted_9 "0 - FETs are operational (default)
1 - FET is shorted";
CM_ SG_ 2566852863 BATT_fetChgFailToClose_9 "0 - FETs are operational (default)
1 -  FET fail to close";
CM_ SG_ 2566852863 BATT_packModSelectFault_9 "0 - Battery pack module selection okay (default)
1 - Battery pack module selection fault";
CM_ SG_ 2566852863 BATT_packModConnectFault_9 "0 - Battery pack module connection okay (default)
1 - Battery pack module connection fault";
CM_ SG_ 2566852863 BATT_packModMIA_9 "0 - Battery pack modules not MIA (default)
1 - Battery pack module MIA";
CM_ SG_ 2566852863 BATT_packModImbalance_9 "0 - Battery pack modules balanced (default)
1 - Battery pack module imblance present";
CM_ SG_ 2566852863 BATT_afeFault_9 "0 - BMS AFE okay (default)
1 - BMS AFE fault";
CM_ SG_ 2566852863 BATT_chargerMIA_9 "0 - Charger communications okay (default)
1 - Charger MIA";
CM_ SG_ 2566852863 BATT_chargerError_9 "0 - Charger working as intended (default)
1 - Charger error";
CM_ SG_ 2566852863 BATT_vBrickUnderWar_9 "0 - Brick voltage okay (default)
1 - Brick undervoltage warning";
CM_ SG_ 2566852863 BATT_vBrickUnderSev_9 "0 - Brick voltage okay (default)
1 - Brick undervoltage severe";
CM_ SG_ 2566852863 BATT_vBrickUnderMod_9 "0 - Brick voltage okay (default)
1 - Brick undervoltage moderate";
CM_ SG_ 2566852863 BATT_vBrickOverWar_9 "0 - Brick voltage okay (default)
1 - Brick overvoltage warning";
CM_ SG_ 2566852863 BATT_vBrickOverSev_9 "0 - Brick voltage okay (default)
1 - Brick overvoltage severe";
CM_ SG_ 2566852863 BATT_vBrickOverMod_9 "0 - Brick voltage okay (default)
1 - Brick overvoltage moderate";
CM_ SG_ 2566852863 BATT_vBrickImbalance_9 "0 - Battery brick voltage okay (default)
1 - Battery brick voltage imbalance";
CM_ SG_ 2566852863 BATT_loggerAlmostFull_9 "0 - Logger not almost full (default)
1 - Logger almost full (section >= 80%) ";
CM_ SG_ 2566852863 BATT_tempModuleUnderWar_9 "0 - Battery temperature okay (default)
1 - Battery under temperature warning";
CM_ SG_ 2566852863 BATT_tempModuleUnderSev_9 "0 - Battery temperature okay (default)
1 - Battery under temperature severe";
CM_ SG_ 2566852863 BATT_tempModuleUnderMod_9 "0 - Battery temperature okay (default)
1 - Battery under temperature moderate";
CM_ SG_ 2566852863 BATT_tempModuleOverWar_9 "0 - Battery temperature okay (default)
1 - Battery over temperature warning";
CM_ SG_ 2566852863 BATT_tempModuleOverSev_9 "0 - Battery temperature okay (default)
1 - Battery over temperature severe";
CM_ SG_ 2566852863 BATT_tempModuleOverMod_9 "0 - Battery temperature okay (default)
1 - Battery over temperature moderate";
CM_ SG_ 2566852863 BATT_tempBrickImbalance_9 "0 - Brick temperatures are balanced (default)
1 - Brick temperatures are imbalanced";
CM_ SG_ 2566852863 BATT_taskLockupError_9 "0 - Tasks okay (default)
1 - Task lockup error";
CM_ SG_ 2566852863 BATT_tempBoardOverWar_9 "0 - Ambient temperature okay (default)
1 - Ambient over temperature warning";
CM_ SG_ 2566852863 BATT_tempBoardOverSev_9 "0 - Temperature okay (default)
1 - Ambient over temperature severe";
CM_ SG_ 2566852863 BATT_tempBoardOverMod_9 "0 - Ambient temperature okay (default)
1 - Ambient over temparature moderate";
CM_ SG_ 2566852863 BATT_sensePackVoltError_9 "0 - Sensor okay (default)
1 - Sensor for pack voltage error";
CM_ SG_ 2566852863 BATT_senseLoadVoltError_9 "0 - Sensor okay (default)
1 - Sensor for load voltage error";
CM_ SG_ 2566852863 BATT_loggerFull_9 "0 - Logger not full (default)
1 - Logger full ";
CM_ SG_ 2566852863 BATT_senseCurrentError_9 "0 - Sensor okay (default)
1 - Sensor for current error";
CM_ SG_ 2566852863 BATT_senseBrickTempError_9 "0 - Sensor okay (default)
1 - Brick temperature sensor error";
CM_ SG_ 2566852863 BATT_resPackHigh_9 "0 - Battery pack resistance okay (default)
1 - Battery pack resistance high (High SOH-R)";
CM_ SG_ 2566852863 BATT_ramOverUtilError_9 "0 - RAM okay (default)
1 - RAM over utilization";
CM_ SG_ 2566852863 BATT_powerPackInsufficient_9 "0 - Battery pack power okay (default)
1 - Battery pack power insufficient";
CM_ SG_ 2566852863 BATT_packCellSoftShort_9 "0 - Battery back cells are okay (default)
1 - Battery pack cell soft short";
CM_ SG_ 2566852863 BATT_iOverHardware_9 "0 - Hardware current okay (default)
1 - Overcurrent in hardware";
CM_ SG_ 2566852863 BATT_fetOverTemp_9 "0 - FET temperature okay (default)
1 - Overtemp at FETs";
CM_ SG_ 2566852863 BATT_iOverDischarge_9 "0 - Discharge okay (default)
1 - Overcurrent during discharge";
CM_ SG_ 2566852863 BATT_iOverCharge_9 "0 - Charging okay (default)
1 - Overcurrent during charging";
CM_ SG_ 2566852863 BATT_inverterDriveMIA_9 "0 - Inverter drive present (default)
1 - Inverter drive MIA";
CM_ SG_ 2566852863 BATT_iUnderCharge_9 "0 - Normal charging (default)
1 -  Charging undercurrent (discharging)";
CM_ SG_ 2566852863 BATT_hostMIA_9 "0 - host communication open (default)
1 - host MIA";
CM_ SG_ 2566852863 BATT_fetDsgShorted_9 "0 - FETs are operational (default)
1 - FET is shorted";
CM_ SG_ 2566852863 BATT_fetDsgFailToClose_9 "0 - FETs are operational (default)
1 -  FET fail to close";
CM_ SG_ 2566852863 BATT_capLow_9 "0 - Battery capacity normal (SOH-C) (default)
1 - Low battery capacity (Low SOH-C)";
CM_ SG_ 2566852863 BATT_brickOverDischarge_9 "0 - Battery brick charge is normal (default)
1 - Battery brick is overdischarged";
CM_ SG_ 2566852863 BATT_brickOverCharge_9 "0 - Battery brick charge is normal (default)
1 - Battery brick is overcharged";
CM_ SG_ 2566852863 BATT_bmsProcessorError_9 "0 - No BMS processor failure (default)
1 - BMS processor failure";
CM_ SG_ 2566852863 BATT_bmsMemoryError_9 "0 - No BMS memory error
1 - BMS memory error";
CM_ SG_ 2566852863 BATT_afeError_9 "0 - No BMS AFE error (default)
1 - BMS AFE error";
CM_ BO_ 2566853110 "Message with flags from event matrix";
CM_ SG_ 2566853110 BATT_vBrickImbalanceWarning_0 "0 - Battery brick voltage okay (default)
1 - Battery brick voltage imbalance";
CM_ SG_ 2566853110 BATT_harnessImpedanceFault_0 "Harness Impedance fault
";
CM_ SG_ 2566853110 BATT_packLevelArbitrationFault_0 "0 - Pack Level Arbitration fault clear (default)
1 - Pack Level Arbitration fault";
CM_ SG_ 2566853110 BATT_multiIgnLoFault_0 "0 - Single module has IGN_LO connection (default)
1 - Multimodule have IGN_LO connections";
CM_ SG_ 2566853110 BATT_modThermistorShorted_0 "0 - module thermistor okay (default)
1 - module thermistor shorted";
CM_ SG_ 2566853110 BATT_modThermistorOpenWire_0 "0 - module thermistor okay (default)
1 - module thermistor open wire";
CM_ SG_ 2566853110 BATT_chargeNotNeeded_0 "0 - Local module charge needed (default)
1 - Local module charge not needed";
CM_ SG_ 2566853110 BATT_packModTempImbalance_0 "0 - Battery pack module temperatures okay (default)
1 - Battery pack module temperature imblance present";
CM_ SG_ 2566853110 BATT_packModCurrImbalance_0 "0 - Battery pack module curent okay (default)
1 - Battery pack module current imblance present";
CM_ SG_ 2566853110 BATT_flashBootCRCError_0 "0 - No flash bootloader CRC error (default)
1 - Flash bootloader CRC error";
CM_ SG_ 2566853110 BATT_flashAppCRCError_0 "0 - No flash app CRC error (default)
1 -  Flash App CRC error";
CM_ SG_ 2566853110 BATT_cellOpenWire_0 "0 - Reset reason okay (default)
1 - Abnormal reset reason";
CM_ BO_ 2566853111 "Message with flags from event matrix";
CM_ SG_ 2566853111 BATT_vBrickImbalanceWarning_1 "0 - Battery brick voltage okay (default)
1 - Battery brick voltage imbalance";
CM_ SG_ 2566853111 BATT_harnessImpedanceFault_1 "Harness Impedance fault
";
CM_ SG_ 2566853111 BATT_packLevelArbitrationFault_1 "0 - Pack Level Arbitration fault clear (default)
1 - Pack Level Arbitration fault";
CM_ SG_ 2566853111 BATT_multiIgnLoFault_1 "0 - Single module has IGN_LO connection (default)
1 - Multimodule have IGN_LO connections";
CM_ SG_ 2566853111 BATT_modThermistorShorted_1 "0 - module thermistor okay (default)
1 - module thermistor shorted";
CM_ SG_ 2566853111 BATT_modThermistorOpenWire_1 "0 - module thermistor okay (default)
1 - module thermistor open wire";
CM_ SG_ 2566853111 BATT_chargeNotNeeded_1 "0 - Local module charge needed (default)
1 - Local module charge not needed";
CM_ SG_ 2566853111 BATT_packModTempImbalance_1 "0 - Battery pack module temperatures okay (default)
1 - Battery pack module temperature imblance present";
CM_ SG_ 2566853111 BATT_packModCurrImbalance_1 "0 - Battery pack module curent okay (default)
1 - Battery pack module current imblance present";
CM_ SG_ 2566853111 BATT_flashBootCRCError_1 "0 - No flash bootloader CRC error (default)
1 - Flash bootloader CRC error";
CM_ SG_ 2566853111 BATT_flashAppCRCError_1 "0 - No flash app CRC error (default)
1 -  Flash App CRC error";
CM_ SG_ 2566853111 BATT_cellOpenWire_1 "0 - Reset reason okay (default)
1 - Abnormal reset reason";
CM_ BO_ 2566853112 "Message with flags from event matrix";
CM_ SG_ 2566853112 BATT_vBrickImbalanceWarning_2 "0 - Battery brick voltage okay (default)
1 - Battery brick voltage imbalance";
CM_ SG_ 2566853112 BATT_harnessImpedanceFault_2 "Harness Impedance fault
";
CM_ SG_ 2566853112 BATT_packLevelArbitrationFault_2 "0 - Pack Level Arbitration fault clear (default)
1 - Pack Level Arbitration fault";
CM_ SG_ 2566853112 BATT_multiIgnLoFault_2 "0 - Single module has IGN_LO connection (default)
1 - Multimodule have IGN_LO connections";
CM_ SG_ 2566853112 BATT_modThermistorShorted_2 "0 - module thermistor okay (default)
1 - module thermistor shorted";
CM_ SG_ 2566853112 BATT_modThermistorOpenWire_2 "0 - module thermistor okay (default)
1 - module thermistor open wire";
CM_ SG_ 2566853112 BATT_chargeNotNeeded_2 "0 - Local module charge needed (default)
1 - Local module charge not needed";
CM_ SG_ 2566853112 BATT_packModTempImbalance_2 "0 - Battery pack module temperatures okay (default)
1 - Battery pack module temperature imblance present";
CM_ SG_ 2566853112 BATT_packModCurrImbalance_2 "0 - Battery pack module curent okay (default)
1 - Battery pack module current imblance present";
CM_ SG_ 2566853112 BATT_flashBootCRCError_2 "0 - No flash bootloader CRC error (default)
1 - Flash bootloader CRC error";
CM_ SG_ 2566853112 BATT_flashAppCRCError_2 "0 - No flash app CRC error (default)
1 -  Flash App CRC error";
CM_ SG_ 2566853112 BATT_cellOpenWire_2 "0 - Reset reason okay (default)
1 - Abnormal reset reason";
CM_ BO_ 2566853113 "Message with flags from event matrix";
CM_ SG_ 2566853113 BATT_vBrickImbalanceWarning_3 "0 - Battery brick voltage okay (default)
1 - Battery brick voltage imbalance";
CM_ SG_ 2566853113 BATT_harnessImpedanceFault_3 "Harness Impedance fault
";
CM_ SG_ 2566853113 BATT_packLevelArbitrationFault_3 "0 - Pack Level Arbitration fault clear (default)
1 - Pack Level Arbitration fault";
CM_ SG_ 2566853113 BATT_multiIgnLoFault_3 "0 - Single module has IGN_LO connection (default)
1 - Multimodule have IGN_LO connections";
CM_ SG_ 2566853113 BATT_modThermistorShorted_3 "0 - module thermistor okay (default)
1 - module thermistor shorted";
CM_ SG_ 2566853113 BATT_modThermistorOpenWire_3 "0 - module thermistor okay (default)
1 - module thermistor open wire";
CM_ SG_ 2566853113 BATT_chargeNotNeeded_3 "0 - Local module charge needed (default)
1 - Local module charge not needed";
CM_ SG_ 2566853113 BATT_packModTempImbalance_3 "0 - Battery pack module temperatures okay (default)
1 - Battery pack module temperature imblance present";
CM_ SG_ 2566853113 BATT_packModCurrImbalance_3 "0 - Battery pack module curent okay (default)
1 - Battery pack module current imblance present";
CM_ SG_ 2566853113 BATT_flashBootCRCError_3 "0 - No flash bootloader CRC error (default)
1 - Flash bootloader CRC error";
CM_ SG_ 2566853113 BATT_flashAppCRCError_3 "0 - No flash app CRC error (default)
1 -  Flash App CRC error";
CM_ SG_ 2566853113 BATT_cellOpenWire_3 "0 - Reset reason okay (default)
1 - Abnormal reset reason";
CM_ BO_ 2566853114 "Message with flags from event matrix";
CM_ SG_ 2566853114 BATT_vBrickImbalanceWarning_4 "0 - Battery brick voltage okay (default)
1 - Battery brick voltage imbalance";
CM_ SG_ 2566853114 BATT_harnessImpedanceFault_4 "Harness Impedance fault
";
CM_ SG_ 2566853114 BATT_packLevelArbitrationFault_4 "0 - Pack Level Arbitration fault clear (default)
1 - Pack Level Arbitration fault";
CM_ SG_ 2566853114 BATT_multiIgnLoFault_4 "0 - Single module has IGN_LO connection (default)
1 - Multimodule have IGN_LO connections";
CM_ SG_ 2566853114 BATT_modThermistorShorted_4 "0 - module thermistor okay (default)
1 - module thermistor shorted";
CM_ SG_ 2566853114 BATT_modThermistorOpenWire_4 "0 - module thermistor okay (default)
1 - module thermistor open wire";
CM_ SG_ 2566853114 BATT_chargeNotNeeded_4 "0 - Local module charge needed (default)
1 - Local module charge not needed";
CM_ SG_ 2566853114 BATT_packModTempImbalance_4 "0 - Battery pack module temperatures okay (default)
1 - Battery pack module temperature imblance present";
CM_ SG_ 2566853114 BATT_packModCurrImbalance_4 "0 - Battery pack module curent okay (default)
1 - Battery pack module current imblance present";
CM_ SG_ 2566853114 BATT_flashBootCRCError_4 "0 - No flash bootloader CRC error (default)
1 - Flash bootloader CRC error";
CM_ SG_ 2566853114 BATT_flashAppCRCError_4 "0 - No flash app CRC error (default)
1 -  Flash App CRC error";
CM_ SG_ 2566853114 BATT_cellOpenWire_4 "0 - Reset reason okay (default)
1 - Abnormal reset reason";
CM_ BO_ 2566853115 "Message with flags from event matrix";
CM_ SG_ 2566853115 BATT_vBrickImbalanceWarning_5 "0 - Battery brick voltage okay (default)
1 - Battery brick voltage imbalance";
CM_ SG_ 2566853115 BATT_harnessImpedanceFault_5 "Harness Impedance fault
";
CM_ SG_ 2566853115 BATT_packLevelArbitrationFault_5 "0 - Pack Level Arbitration fault clear (default)
1 - Pack Level Arbitration fault";
CM_ SG_ 2566853115 BATT_multiIgnLoFault_5 "0 - Single module has IGN_LO connection (default)
1 - Multimodule have IGN_LO connections";
CM_ SG_ 2566853115 BATT_modThermistorShorted_5 "0 - module thermistor okay (default)
1 - module thermistor shorted";
CM_ SG_ 2566853115 BATT_modThermistorOpenWire_5 "0 - module thermistor okay (default)
1 - module thermistor open wire";
CM_ SG_ 2566853115 BATT_chargeNotNeeded_5 "0 - Local module charge needed (default)
1 - Local module charge not needed";
CM_ SG_ 2566853115 BATT_packModTempImbalance_5 "0 - Battery pack module temperatures okay (default)
1 - Battery pack module temperature imblance present";
CM_ SG_ 2566853115 BATT_packModCurrImbalance_5 "0 - Battery pack module curent okay (default)
1 - Battery pack module current imblance present";
CM_ SG_ 2566853115 BATT_flashBootCRCError_5 "0 - No flash bootloader CRC error (default)
1 - Flash bootloader CRC error";
CM_ SG_ 2566853115 BATT_flashAppCRCError_5 "0 - No flash app CRC error (default)
1 -  Flash App CRC error";
CM_ SG_ 2566853115 BATT_cellOpenWire_5 "0 - Reset reason okay (default)
1 - Abnormal reset reason";
CM_ BO_ 2566853116 "Message with flags from event matrix";
CM_ SG_ 2566853116 BATT_vBrickImbalanceWarning_6 "0 - Battery brick voltage okay (default)
1 - Battery brick voltage imbalance";
CM_ SG_ 2566853116 BATT_harnessImpedanceFault_6 "Harness Impedance fault
";
CM_ SG_ 2566853116 BATT_packLevelArbitrationFault_6 "0 - Pack Level Arbitration fault clear (default)
1 - Pack Level Arbitration fault";
CM_ SG_ 2566853116 BATT_multiIgnLoFault_6 "0 - Single module has IGN_LO connection (default)
1 - Multimodule have IGN_LO connections";
CM_ SG_ 2566853116 BATT_modThermistorShorted_6 "0 - module thermistor okay (default)
1 - module thermistor shorted";
CM_ SG_ 2566853116 BATT_modThermistorOpenWire_6 "0 - module thermistor okay (default)
1 - module thermistor open wire";
CM_ SG_ 2566853116 BATT_chargeNotNeeded_6 "0 - Local module charge needed (default)
1 - Local module charge not needed";
CM_ SG_ 2566853116 BATT_packModTempImbalance_6 "0 - Battery pack module temperatures okay (default)
1 - Battery pack module temperature imblance present";
CM_ SG_ 2566853116 BATT_packModCurrImbalance_6 "0 - Battery pack module curent okay (default)
1 - Battery pack module current imblance present";
CM_ SG_ 2566853116 BATT_flashBootCRCError_6 "0 - No flash bootloader CRC error (default)
1 - Flash bootloader CRC error";
CM_ SG_ 2566853116 BATT_flashAppCRCError_6 "0 - No flash app CRC error (default)
1 -  Flash App CRC error";
CM_ SG_ 2566853116 BATT_cellOpenWire_6 "0 - Reset reason okay (default)
1 - Abnormal reset reason";
CM_ BO_ 2566853117 "Message with flags from event matrix";
CM_ SG_ 2566853117 BATT_vBrickImbalanceWarning_7 "0 - Battery brick voltage okay (default)
1 - Battery brick voltage imbalance";
CM_ SG_ 2566853117 BATT_harnessImpedanceFault_7 "Harness Impedance fault
";
CM_ SG_ 2566853117 BATT_packLevelArbitrationFault_7 "0 - Pack Level Arbitration fault clear (default)
1 - Pack Level Arbitration fault";
CM_ SG_ 2566853117 BATT_multiIgnLoFault_7 "0 - Single module has IGN_LO connection (default)
1 - Multimodule have IGN_LO connections";
CM_ SG_ 2566853117 BATT_modThermistorShorted_7 "0 - module thermistor okay (default)
1 - module thermistor shorted";
CM_ SG_ 2566853117 BATT_modThermistorOpenWire_7 "0 - module thermistor okay (default)
1 - module thermistor open wire";
CM_ SG_ 2566853117 BATT_chargeNotNeeded_7 "0 - Local module charge needed (default)
1 - Local module charge not needed";
CM_ SG_ 2566853117 BATT_packModTempImbalance_7 "0 - Battery pack module temperatures okay (default)
1 - Battery pack module temperature imblance present";
CM_ SG_ 2566853117 BATT_packModCurrImbalance_7 "0 - Battery pack module curent okay (default)
1 - Battery pack module current imblance present";
CM_ SG_ 2566853117 BATT_flashBootCRCError_7 "0 - No flash bootloader CRC error (default)
1 - Flash bootloader CRC error";
CM_ SG_ 2566853117 BATT_flashAppCRCError_7 "0 - No flash app CRC error (default)
1 -  Flash App CRC error";
CM_ SG_ 2566853117 BATT_cellOpenWire_7 "0 - Reset reason okay (default)
1 - Abnormal reset reason";
CM_ BO_ 2566853118 "Message with flags from event matrix";
CM_ SG_ 2566853118 BATT_vBrickImbalanceWarning_8 "0 - Battery brick voltage okay (default)
1 - Battery brick voltage imbalance";
CM_ SG_ 2566853118 BATT_harnessImpedanceFault_8 "Harness Impedance fault
";
CM_ SG_ 2566853118 BATT_packLevelArbitrationFault_8 "0 - Pack Level Arbitration fault clear (default)
1 - Pack Level Arbitration fault";
CM_ SG_ 2566853118 BATT_multiIgnLoFault_8 "0 - Single module has IGN_LO connection (default)
1 - Multimodule have IGN_LO connections";
CM_ SG_ 2566853118 BATT_modThermistorShorted_8 "0 - module thermistor okay (default)
1 - module thermistor shorted";
CM_ SG_ 2566853118 BATT_modThermistorOpenWire_8 "0 - module thermistor okay (default)
1 - module thermistor open wire";
CM_ SG_ 2566853118 BATT_chargeNotNeeded_8 "0 - Local module charge needed (default)
1 - Local module charge not needed";
CM_ SG_ 2566853118 BATT_packModTempImbalance_8 "0 - Battery pack module temperatures okay (default)
1 - Battery pack module temperature imblance present";
CM_ SG_ 2566853118 BATT_packModCurrImbalance_8 "0 - Battery pack module curent okay (default)
1 - Battery pack module current imblance present";
CM_ SG_ 2566853118 BATT_flashBootCRCError_8 "0 - No flash bootloader CRC error (default)
1 - Flash bootloader CRC error";
CM_ SG_ 2566853118 BATT_flashAppCRCError_8 "0 - No flash app CRC error (default)
1 -  Flash App CRC error";
CM_ SG_ 2566853118 BATT_cellOpenWire_8 "0 - Reset reason okay (default)
1 - Abnormal reset reason";
CM_ BO_ 2566853119 "Message with flags from event matrix";
CM_ SG_ 2566853119 BATT_vBrickImbalanceWarning_9 "0 - Battery brick voltage okay (default)
1 - Battery brick voltage imbalance";
CM_ SG_ 2566853119 BATT_harnessImpedanceFault_9 "Harness Impedance fault
";
CM_ SG_ 2566853119 BATT_packLevelArbitrationFault_9 "0 - Pack Level Arbitration fault clear (default)
1 - Pack Level Arbitration fault";
CM_ SG_ 2566853119 BATT_multiIgnLoFault_9 "0 - Single module has IGN_LO connection (default)
1 - Multimodule have IGN_LO connections";
CM_ SG_ 2566853119 BATT_modThermistorShorted_9 "0 - module thermistor okay (default)
1 - module thermistor shorted";
CM_ SG_ 2566853119 BATT_modThermistorOpenWire_9 "0 - module thermistor okay (default)
1 - module thermistor open wire";
CM_ SG_ 2566853119 BATT_chargeNotNeeded_9 "0 - Local module charge needed (default)
1 - Local module charge not needed";
CM_ SG_ 2566853119 BATT_packModTempImbalance_9 "0 - Battery pack module temperatures okay (default)
1 - Battery pack module temperature imblance present";
CM_ SG_ 2566853119 BATT_packModCurrImbalance_9 "0 - Battery pack module curent okay (default)
1 - Battery pack module current imblance present";
CM_ SG_ 2566853119 BATT_flashBootCRCError_9 "0 - No flash bootloader CRC error (default)
1 - Flash bootloader CRC error";
CM_ SG_ 2566853119 BATT_flashAppCRCError_9 "0 - No flash app CRC error (default)
1 -  Flash App CRC error";
CM_ SG_ 2566853119 BATT_cellOpenWire_9 "0 - Reset reason okay (default)
1 - Abnormal reset reason";
CM_ BO_ 2566853877 "BATT battery request";
CM_ SG_ 2566853877 BATT_muteCAN "0 if CAN mute is not requested
1 if CAN mute is requested
";
CM_ SG_ 2566853877 BATT_isPushBtn_Requested "0 if PUSH_BTN pin is NOT pressed
1 if PUSH_BTN pin is pressed for 3 secs and released";
CM_ SG_ 2566853877 BATT_isIgnLo_Requested "0 if IGN_LO pin is NOT triggered
1 if IGN_LO pin is triggered ";
CM_ SG_ 2566853877 BATT_modReqCntr "BATT_modRequest msg counter";
CM_ SG_ 2566853877 BATT_nodeIdSerialNumber "Unique serial number";
CM_ SG_ 2566853877 BATT_startNodeId "Start node ID claim flag from BATT";
CM_ SG_ 2566853877 BATT_stateRequest "State to be requested from battery module";
CM_ BO_ 2566854390 "Capacity of bricks 5-8";
CM_ SG_ 2566854390 BATT_capBrick08_0 "Capacity of brick 8";
CM_ SG_ 2566854390 BATT_capBrick07_0 "Capacity of brick 7";
CM_ SG_ 2566854390 BATT_capBrick06_0 "Capacity of brick 6";
CM_ SG_ 2566854390 BATT_capBrick05_0 "Capacity of brick 5";
CM_ BO_ 2566854391 "Capacity of bricks 5-8";
CM_ SG_ 2566854391 BATT_capBrick08_1 "Capacity of brick 8";
CM_ SG_ 2566854391 BATT_capBrick07_1 "Capacity of brick 7";
CM_ SG_ 2566854391 BATT_capBrick06_1 "Capacity of brick 6";
CM_ SG_ 2566854391 BATT_capBrick05_1 "Capacity of brick 5";
CM_ BO_ 2566854392 "Capacity of bricks 5-8";
CM_ SG_ 2566854392 BATT_capBrick08_2 "Capacity of brick 8";
CM_ SG_ 2566854392 BATT_capBrick07_2 "Capacity of brick 7";
CM_ SG_ 2566854392 BATT_capBrick06_2 "Capacity of brick 6";
CM_ SG_ 2566854392 BATT_capBrick05_2 "Capacity of brick 5";
CM_ BO_ 2566854393 "Capacity of bricks 5-8";
CM_ SG_ 2566854393 BATT_capBrick08_3 "Capacity of brick 8";
CM_ SG_ 2566854393 BATT_capBrick07_3 "Capacity of brick 7";
CM_ SG_ 2566854393 BATT_capBrick06_3 "Capacity of brick 6";
CM_ SG_ 2566854393 BATT_capBrick05_3 "Capacity of brick 5";
CM_ BO_ 2566854394 "Capacity of bricks 5-8";
CM_ SG_ 2566854394 BATT_capBrick08_4 "Capacity of brick 8";
CM_ SG_ 2566854394 BATT_capBrick07_4 "Capacity of brick 7";
CM_ SG_ 2566854394 BATT_capBrick06_4 "Capacity of brick 6";
CM_ SG_ 2566854394 BATT_capBrick05_4 "Capacity of brick 5";
CM_ BO_ 2566854395 "Capacity of bricks 5-8";
CM_ SG_ 2566854395 BATT_capBrick08_5 "Capacity of brick 8";
CM_ SG_ 2566854395 BATT_capBrick07_5 "Capacity of brick 7";
CM_ SG_ 2566854395 BATT_capBrick06_5 "Capacity of brick 6";
CM_ SG_ 2566854395 BATT_capBrick05_5 "Capacity of brick 5";
CM_ BO_ 2566854396 "Capacity of bricks 5-8";
CM_ SG_ 2566854396 BATT_capBrick08_6 "Capacity of brick 8";
CM_ SG_ 2566854396 BATT_capBrick07_6 "Capacity of brick 7";
CM_ SG_ 2566854396 BATT_capBrick06_6 "Capacity of brick 6";
CM_ SG_ 2566854396 BATT_capBrick05_6 "Capacity of brick 5";
CM_ BO_ 2566854397 "Capacity of bricks 5-8";
CM_ SG_ 2566854397 BATT_capBrick08_7 "Capacity of brick 8";
CM_ SG_ 2566854397 BATT_capBrick07_7 "Capacity of brick 7";
CM_ SG_ 2566854397 BATT_capBrick06_7 "Capacity of brick 6";
CM_ SG_ 2566854397 BATT_capBrick05_7 "Capacity of brick 5";
CM_ BO_ 2566854398 "Capacity of bricks 5-8";
CM_ SG_ 2566854398 BATT_capBrick08_8 "Capacity of brick 8";
CM_ SG_ 2566854398 BATT_capBrick07_8 "Capacity of brick 7";
CM_ SG_ 2566854398 BATT_capBrick06_8 "Capacity of brick 6";
CM_ SG_ 2566854398 BATT_capBrick05_8 "Capacity of brick 5";
CM_ BO_ 2566854399 "Capacity of bricks 5-8";
CM_ SG_ 2566854399 BATT_capBrick08_9 "Capacity of brick 8";
CM_ SG_ 2566854399 BATT_capBrick07_9 "Capacity of brick 7";
CM_ SG_ 2566854399 BATT_capBrick06_9 "Capacity of brick 6";
CM_ SG_ 2566854399 BATT_capBrick05_9 "Capacity of brick 5";
CM_ BO_ 2566854646 "Voltages of bricks 5-8";
CM_ SG_ 2566854646 BATT_vBrick06_0 "Voltage of brick 6";
CM_ SG_ 2566854646 BATT_vBrick07_0 "Voltage of brick 7";
CM_ SG_ 2566854646 BATT_vBrick05_0 "Voltage of brick 5";
CM_ SG_ 2566854646 BATT_vBrick08_0 "Voltage of brick 8";
CM_ BO_ 2566854647 "Voltages of bricks 5-8";
CM_ SG_ 2566854647 BATT_vBrick06_1 "Voltage of brick 6";
CM_ SG_ 2566854647 BATT_vBrick07_1 "Voltage of brick 7";
CM_ SG_ 2566854647 BATT_vBrick05_1 "Voltage of brick 5";
CM_ SG_ 2566854647 BATT_vBrick08_1 "Voltage of brick 8";
CM_ BO_ 2566854648 "Voltages of bricks 5-8";
CM_ SG_ 2566854648 BATT_vBrick06_2 "Voltage of brick 6";
CM_ SG_ 2566854648 BATT_vBrick07_2 "Voltage of brick 7";
CM_ SG_ 2566854648 BATT_vBrick05_2 "Voltage of brick 5";
CM_ SG_ 2566854648 BATT_vBrick08_2 "Voltage of brick 8";
CM_ BO_ 2566854649 "Voltages of bricks 5-8";
CM_ SG_ 2566854649 BATT_vBrick06_3 "Voltage of brick 6";
CM_ SG_ 2566854649 BATT_vBrick07_3 "Voltage of brick 7";
CM_ SG_ 2566854649 BATT_vBrick05_3 "Voltage of brick 5";
CM_ SG_ 2566854649 BATT_vBrick08_3 "Voltage of brick 8";
CM_ BO_ 2566854650 "Voltages of bricks 5-8";
CM_ SG_ 2566854650 BATT_vBrick06_4 "Voltage of brick 6";
CM_ SG_ 2566854650 BATT_vBrick07_4 "Voltage of brick 7";
CM_ SG_ 2566854650 BATT_vBrick05_4 "Voltage of brick 5";
CM_ SG_ 2566854650 BATT_vBrick08_4 "Voltage of brick 8";
CM_ BO_ 2566854651 "Voltages of bricks 5-8";
CM_ SG_ 2566854651 BATT_vBrick06_5 "Voltage of brick 6";
CM_ SG_ 2566854651 BATT_vBrick07_5 "Voltage of brick 7";
CM_ SG_ 2566854651 BATT_vBrick05_5 "Voltage of brick 5";
CM_ SG_ 2566854651 BATT_vBrick08_5 "Voltage of brick 8";
CM_ BO_ 2566854652 "Voltages of bricks 5-8";
CM_ SG_ 2566854652 BATT_vBrick06_6 "Voltage of brick 6";
CM_ SG_ 2566854652 BATT_vBrick07_6 "Voltage of brick 7";
CM_ SG_ 2566854652 BATT_vBrick05_6 "Voltage of brick 5";
CM_ SG_ 2566854652 BATT_vBrick08_6 "Voltage of brick 8";
CM_ BO_ 2566854653 "Voltages of bricks 5-8";
CM_ SG_ 2566854653 BATT_vBrick06_7 "Voltage of brick 6";
CM_ SG_ 2566854653 BATT_vBrick07_7 "Voltage of brick 7";
CM_ SG_ 2566854653 BATT_vBrick05_7 "Voltage of brick 5";
CM_ SG_ 2566854653 BATT_vBrick08_7 "Voltage of brick 8";
CM_ BO_ 2566854654 "Voltages of bricks 5-8";
CM_ SG_ 2566854654 BATT_vBrick06_8 "Voltage of brick 6";
CM_ SG_ 2566854654 BATT_vBrick07_8 "Voltage of brick 7";
CM_ SG_ 2566854654 BATT_vBrick05_8 "Voltage of brick 5";
CM_ SG_ 2566854654 BATT_vBrick08_8 "Voltage of brick 8";
CM_ BO_ 2566854655 "Voltages of bricks 5-8";
CM_ SG_ 2566854655 BATT_vBrick06_9 "Voltage of brick 6";
CM_ SG_ 2566854655 BATT_vBrick07_9 "Voltage of brick 7";
CM_ SG_ 2566854655 BATT_vBrick05_9 "Voltage of brick 5";
CM_ SG_ 2566854655 BATT_vBrick08_9 "Voltage of brick 8";
CM_ SG_ 2566855158 BATT_tPreChg_0 "Temperature of current shunt";
CM_ SG_ 2566855158 BATT_tShunt_0 "Temperature of current shunt";
CM_ SG_ 2566855158 BATT_tFET_0 "Temperature of FETs";
CM_ SG_ 2566855159 BATT_tPreChg_1 "Temperature of current shunt";
CM_ SG_ 2566855159 BATT_tShunt_1 "Temperature of current shunt";
CM_ SG_ 2566855159 BATT_tFET_1 "Temperature of FETs";
CM_ SG_ 2566855160 BATT_tPreChg_2 "Temperature of current shunt";
CM_ SG_ 2566855160 BATT_tShunt_2 "Temperature of current shunt";
CM_ SG_ 2566855160 BATT_tFET_2 "Temperature of FETs";
CM_ SG_ 2566855161 BATT_tPreChg_3 "Temperature of current shunt";
CM_ SG_ 2566855161 BATT_tShunt_3 "Temperature of current shunt";
CM_ SG_ 2566855161 BATT_tFET_3 "Temperature of FETs";
CM_ SG_ 2566855162 BATT_tPreChg_4 "Temperature of current shunt";
CM_ SG_ 2566855162 BATT_tShunt_4 "Temperature of current shunt";
CM_ SG_ 2566855162 BATT_tFET_4 "Temperature of FETs";
CM_ SG_ 2566855163 BATT_tPreChg_5 "Temperature of current shunt";
CM_ SG_ 2566855163 BATT_tShunt_5 "Temperature of current shunt";
CM_ SG_ 2566855163 BATT_tFET_5 "Temperature of FETs";
CM_ SG_ 2566855164 BATT_tPreChg_6 "Temperature of current shunt";
CM_ SG_ 2566855164 BATT_tShunt_6 "Temperature of current shunt";
CM_ SG_ 2566855164 BATT_tFET_6 "Temperature of FETs";
CM_ SG_ 2566855165 BATT_tPreChg_7 "Temperature of current shunt";
CM_ SG_ 2566855165 BATT_tShunt_7 "Temperature of current shunt";
CM_ SG_ 2566855165 BATT_tFET_7 "Temperature of FETs";
CM_ SG_ 2566855166 BATT_tPreChg_8 "Temperature of current shunt";
CM_ SG_ 2566855166 BATT_tShunt_8 "Temperature of current shunt";
CM_ SG_ 2566855166 BATT_tFET_8 "Temperature of FETs";
CM_ SG_ 2566855167 BATT_tPreChg_9 "Temperature of current shunt";
CM_ SG_ 2566855167 BATT_tShunt_9 "Temperature of current shunt";
CM_ SG_ 2566855167 BATT_tFET_9 "Temperature of FETs";
CM_ SG_ 2566856694 BATT_boardIO_IGN_L_0 "Ignition Low input signal status";
CM_ SG_ 2566856694 BATT_boardIO_IGN_H_0 "Ignition High input signal status";
CM_ SG_ 2566856694 BATT_boardIO_EXT_5V_STATUS_0 "Ext 5V input signal status";
CM_ SG_ 2566856694 BATT_boardIO_L9963_FAULT_LA_0 "L9963_FAULT input signal status";
CM_ SG_ 2566856694 BATT_boardIO_RTC_WAKE_LA_0 "RTC_WAKE_LA input signal status";
CM_ SG_ 2566856694 BATT_boardIO_CAN_WAKE_LATCH_0 "CAN_WAKE_LA input signal status";
CM_ SG_ 2566856694 BATT_boardIO_DIS_OC_FLT_LA_0 "DIS_OC_FLT_LA input signal status";
CM_ SG_ 2566856694 BATT_boardIO_RTC_WAKE_LATCH_0 "RTC_WAKE_LATCH input signal status";
CM_ SG_ 2566856694 BATT_boardIO_L9963_FAULT_0 "L9963_FAULT input signal status";
CM_ SG_ 2566856694 BATT_boardIO_IGN_L_LCH_0 "Ignition Low latched input signal status";
CM_ SG_ 2566856694 BATT_boardIO_IGN_H_LCH_0 "Ignition High latched input signal status";
CM_ SG_ 2566856694 BATT_boardIO_CAN_WAKE_0 "CAN_WAKE_LATCH input signal status";
CM_ SG_ 2566856695 BATT_boardIO_IGN_L_1 "Ignition Low input signal status";
CM_ SG_ 2566856695 BATT_boardIO_IGN_H_1 "Ignition High input signal status";
CM_ SG_ 2566856695 BATT_boardIO_EXT_5V_STATUS_1 "Ext 5V input signal status";
CM_ SG_ 2566856695 BATT_boardIO_L9963_FAULT_LA_1 "L9963_FAULT input signal status";
CM_ SG_ 2566856695 BATT_boardIO_RTC_WAKE_LA_1 "RTC_WAKE_LA input signal status";
CM_ SG_ 2566856695 BATT_boardIO_CAN_WAKE_LATCH_1 "CAN_WAKE_LA input signal status";
CM_ SG_ 2566856695 BATT_boardIO_DIS_OC_FLT_LA_1 "DIS_OC_FLT_LA input signal status";
CM_ SG_ 2566856695 BATT_boardIO_RTC_WAKE_LATCH_1 "RTC_WAKE_LATCH input signal status";
CM_ SG_ 2566856695 BATT_boardIO_L9963_FAULT_1 "L9963_FAULT input signal status";
CM_ SG_ 2566856695 BATT_boardIO_IGN_L_LCH_1 "Ignition Low latched input signal status";
CM_ SG_ 2566856695 BATT_boardIO_IGN_H_LCH_1 "Ignition High latched input signal status";
CM_ SG_ 2566856695 BATT_boardIO_CAN_WAKE_1 "CAN_WAKE_LATCH input signal status";
CM_ SG_ 2566856696 BATT_boardIO_IGN_L_2 "Ignition Low input signal status";
CM_ SG_ 2566856696 BATT_boardIO_IGN_H_2 "Ignition High input signal status";
CM_ SG_ 2566856696 BATT_boardIO_EXT_5V_STATUS_2 "Ext 5V input signal status";
CM_ SG_ 2566856696 BATT_boardIO_L9963_FAULT_LA_2 "L9963_FAULT input signal status";
CM_ SG_ 2566856696 BATT_boardIO_RTC_WAKE_LA_2 "RTC_WAKE_LA input signal status";
CM_ SG_ 2566856696 BATT_boardIO_CAN_WAKE_LATCH_2 "CAN_WAKE_LA input signal status";
CM_ SG_ 2566856696 BATT_boardIO_DIS_OC_FLT_LA_2 "DIS_OC_FLT_LA input signal status";
CM_ SG_ 2566856696 BATT_boardIO_RTC_WAKE_LATCH_2 "RTC_WAKE_LATCH input signal status";
CM_ SG_ 2566856696 BATT_boardIO_L9963_FAULT_2 "L9963_FAULT input signal status";
CM_ SG_ 2566856696 BATT_boardIO_IGN_L_LCH_2 "Ignition Low latched input signal status";
CM_ SG_ 2566856696 BATT_boardIO_IGN_H_LCH_2 "Ignition High latched input signal status";
CM_ SG_ 2566856696 BATT_boardIO_CAN_WAKE_2 "CAN_WAKE_LATCH input signal status";
CM_ SG_ 2566856697 BATT_boardIO_IGN_L_3 "Ignition Low input signal status";
CM_ SG_ 2566856697 BATT_boardIO_IGN_H_3 "Ignition High input signal status";
CM_ SG_ 2566856697 BATT_boardIO_EXT_5V_STATUS_3 "Ext 5V input signal status";
CM_ SG_ 2566856697 BATT_boardIO_L9963_FAULT_LA_3 "L9963_FAULT input signal status";
CM_ SG_ 2566856697 BATT_boardIO_RTC_WAKE_LA_3 "RTC_WAKE_LA input signal status";
CM_ SG_ 2566856697 BATT_boardIO_CAN_WAKE_LATCH_3 "CAN_WAKE_LA input signal status";
CM_ SG_ 2566856697 BATT_boardIO_DIS_OC_FLT_LA_3 "DIS_OC_FLT_LA input signal status";
CM_ SG_ 2566856697 BATT_boardIO_RTC_WAKE_LATCH_3 "RTC_WAKE_LATCH input signal status";
CM_ SG_ 2566856697 BATT_boardIO_L9963_FAULT_3 "L9963_FAULT input signal status";
CM_ SG_ 2566856697 BATT_boardIO_IGN_L_LCH_3 "Ignition Low latched input signal status";
CM_ SG_ 2566856697 BATT_boardIO_IGN_H_LCH_3 "Ignition High latched input signal status";
CM_ SG_ 2566856697 BATT_boardIO_CAN_WAKE_3 "CAN_WAKE_LATCH input signal status";
CM_ SG_ 2566856698 BATT_boardIO_IGN_L_4 "Ignition Low input signal status";
CM_ SG_ 2566856698 BATT_boardIO_IGN_H_4 "Ignition High input signal status";
CM_ SG_ 2566856698 BATT_boardIO_EXT_5V_STATUS_4 "Ext 5V input signal status";
CM_ SG_ 2566856698 BATT_boardIO_L9963_FAULT_LA_4 "L9963_FAULT input signal status";
CM_ SG_ 2566856698 BATT_boardIO_RTC_WAKE_LA_4 "RTC_WAKE_LA input signal status";
CM_ SG_ 2566856698 BATT_boardIO_CAN_WAKE_LATCH_4 "CAN_WAKE_LA input signal status";
CM_ SG_ 2566856698 BATT_boardIO_DIS_OC_FLT_LA_4 "DIS_OC_FLT_LA input signal status";
CM_ SG_ 2566856698 BATT_boardIO_RTC_WAKE_LATCH_4 "RTC_WAKE_LATCH input signal status";
CM_ SG_ 2566856698 BATT_boardIO_L9963_FAULT_4 "L9963_FAULT input signal status";
CM_ SG_ 2566856698 BATT_boardIO_IGN_L_LCH_4 "Ignition Low latched input signal status";
CM_ SG_ 2566856698 BATT_boardIO_IGN_H_LCH_4 "Ignition High latched input signal status";
CM_ SG_ 2566856698 BATT_boardIO_CAN_WAKE_4 "CAN_WAKE_LATCH input signal status";
CM_ SG_ 2566856699 BATT_boardIO_IGN_L_5 "Ignition Low input signal status";
CM_ SG_ 2566856699 BATT_boardIO_IGN_H_5 "Ignition High input signal status";
CM_ SG_ 2566856699 BATT_boardIO_EXT_5V_STATUS_5 "Ext 5V input signal status";
CM_ SG_ 2566856699 BATT_boardIO_L9963_FAULT_LA_5 "L9963_FAULT input signal status";
CM_ SG_ 2566856699 BATT_boardIO_RTC_WAKE_LA_5 "RTC_WAKE_LA input signal status";
CM_ SG_ 2566856699 BATT_boardIO_CAN_WAKE_LATCH_5 "CAN_WAKE_LA input signal status";
CM_ SG_ 2566856699 BATT_boardIO_DIS_OC_FLT_LA_5 "DIS_OC_FLT_LA input signal status";
CM_ SG_ 2566856699 BATT_boardIO_RTC_WAKE_LATCH_5 "RTC_WAKE_LATCH input signal status";
CM_ SG_ 2566856699 BATT_boardIO_L9963_FAULT_5 "L9963_FAULT input signal status";
CM_ SG_ 2566856699 BATT_boardIO_IGN_L_LCH_5 "Ignition Low latched input signal status";
CM_ SG_ 2566856699 BATT_boardIO_IGN_H_LCH_5 "Ignition High latched input signal status";
CM_ SG_ 2566856699 BATT_boardIO_CAN_WAKE_5 "CAN_WAKE_LATCH input signal status";
CM_ SG_ 2566856700 BATT_boardIO_IGN_L_6 "Ignition Low input signal status";
CM_ SG_ 2566856700 BATT_boardIO_IGN_H_6 "Ignition High input signal status";
CM_ SG_ 2566856700 BATT_boardIO_EXT_5V_STATUS_6 "Ext 5V input signal status";
CM_ SG_ 2566856700 BATT_boardIO_L9963_FAULT_LA_6 "L9963_FAULT input signal status";
CM_ SG_ 2566856700 BATT_boardIO_RTC_WAKE_LA_6 "RTC_WAKE_LA input signal status";
CM_ SG_ 2566856700 BATT_boardIO_CAN_WAKE_LATCH_6 "CAN_WAKE_LA input signal status";
CM_ SG_ 2566856700 BATT_boardIO_DIS_OC_FLT_LA_6 "DIS_OC_FLT_LA input signal status";
CM_ SG_ 2566856700 BATT_boardIO_RTC_WAKE_LATCH_6 "RTC_WAKE_LATCH input signal status";
CM_ SG_ 2566856700 BATT_boardIO_L9963_FAULT_6 "L9963_FAULT input signal status";
CM_ SG_ 2566856700 BATT_boardIO_IGN_L_LCH_6 "Ignition Low latched input signal status";
CM_ SG_ 2566856700 BATT_boardIO_IGN_H_LCH_6 "Ignition High latched input signal status";
CM_ SG_ 2566856700 BATT_boardIO_CAN_WAKE_6 "CAN_WAKE_LATCH input signal status";
CM_ SG_ 2566856701 BATT_boardIO_IGN_L_7 "Ignition Low input signal status";
CM_ SG_ 2566856701 BATT_boardIO_IGN_H_7 "Ignition High input signal status";
CM_ SG_ 2566856701 BATT_boardIO_EXT_5V_STATUS_7 "Ext 5V input signal status";
CM_ SG_ 2566856701 BATT_boardIO_L9963_FAULT_LA_7 "L9963_FAULT input signal status";
CM_ SG_ 2566856701 BATT_boardIO_RTC_WAKE_LA_7 "RTC_WAKE_LA input signal status";
CM_ SG_ 2566856701 BATT_boardIO_CAN_WAKE_LATCH_7 "CAN_WAKE_LA input signal status";
CM_ SG_ 2566856701 BATT_boardIO_DIS_OC_FLT_LA_7 "DIS_OC_FLT_LA input signal status";
CM_ SG_ 2566856701 BATT_boardIO_RTC_WAKE_LATCH_7 "RTC_WAKE_LATCH input signal status";
CM_ SG_ 2566856701 BATT_boardIO_L9963_FAULT_7 "L9963_FAULT input signal status";
CM_ SG_ 2566856701 BATT_boardIO_IGN_L_LCH_7 "Ignition Low latched input signal status";
CM_ SG_ 2566856701 BATT_boardIO_IGN_H_LCH_7 "Ignition High latched input signal status";
CM_ SG_ 2566856701 BATT_boardIO_CAN_WAKE_7 "CAN_WAKE_LATCH input signal status";
CM_ SG_ 2566856702 BATT_boardIO_IGN_L_8 "Ignition Low input signal status";
CM_ SG_ 2566856702 BATT_boardIO_IGN_H_8 "Ignition High input signal status";
CM_ SG_ 2566856702 BATT_boardIO_EXT_5V_STATUS_8 "Ext 5V input signal status";
CM_ SG_ 2566856702 BATT_boardIO_L9963_FAULT_LA_8 "L9963_FAULT input signal status";
CM_ SG_ 2566856702 BATT_boardIO_RTC_WAKE_LA_8 "RTC_WAKE_LA input signal status";
CM_ SG_ 2566856702 BATT_boardIO_CAN_WAKE_LATCH_8 "CAN_WAKE_LA input signal status";
CM_ SG_ 2566856702 BATT_boardIO_DIS_OC_FLT_LA_8 "DIS_OC_FLT_LA input signal status";
CM_ SG_ 2566856702 BATT_boardIO_RTC_WAKE_LATCH_8 "RTC_WAKE_LATCH input signal status";
CM_ SG_ 2566856702 BATT_boardIO_L9963_FAULT_8 "L9963_FAULT input signal status";
CM_ SG_ 2566856702 BATT_boardIO_IGN_L_LCH_8 "Ignition Low latched input signal status";
CM_ SG_ 2566856702 BATT_boardIO_IGN_H_LCH_8 "Ignition High latched input signal status";
CM_ SG_ 2566856702 BATT_boardIO_CAN_WAKE_8 "CAN_WAKE_LATCH input signal status";
CM_ SG_ 2566856703 BATT_boardIO_IGN_L_9 "Ignition Low input signal status";
CM_ SG_ 2566856703 BATT_boardIO_IGN_H_9 "Ignition High input signal status";
CM_ SG_ 2566856703 BATT_boardIO_EXT_5V_STATUS_9 "Ext 5V input signal status";
CM_ SG_ 2566856703 BATT_boardIO_L9963_FAULT_LA_9 "L9963_FAULT input signal status";
CM_ SG_ 2566856703 BATT_boardIO_RTC_WAKE_LA_9 "RTC_WAKE_LA input signal status";
CM_ SG_ 2566856703 BATT_boardIO_CAN_WAKE_LATCH_9 "CAN_WAKE_LA input signal status";
CM_ SG_ 2566856703 BATT_boardIO_DIS_OC_FLT_LA_9 "DIS_OC_FLT_LA input signal status";
CM_ SG_ 2566856703 BATT_boardIO_RTC_WAKE_LATCH_9 "RTC_WAKE_LATCH input signal status";
CM_ SG_ 2566856703 BATT_boardIO_L9963_FAULT_9 "L9963_FAULT input signal status";
CM_ SG_ 2566856703 BATT_boardIO_IGN_L_LCH_9 "Ignition Low latched input signal status";
CM_ SG_ 2566856703 BATT_boardIO_IGN_H_LCH_9 "Ignition High latched input signal status";
CM_ SG_ 2566856703 BATT_boardIO_CAN_WAKE_9 "CAN_WAKE_LATCH input signal status";
CM_ BO_ 2566858486 "Capacity of bricks 9-12";
CM_ SG_ 2566858486 BATT_capBrick12_0 "Capacity of brick 12";
CM_ SG_ 2566858486 BATT_capBrick11_0 "Capacity of brick 11";
CM_ SG_ 2566858486 BATT_capBrick09_0 "Capacity of brick 9";
CM_ SG_ 2566858486 BATT_capBrick10_0 "Capacity of brick 10";
CM_ BO_ 2566858487 "Capacity of bricks 9-12";
CM_ SG_ 2566858487 BATT_capBrick12_1 "Capacity of brick 12";
CM_ SG_ 2566858487 BATT_capBrick11_1 "Capacity of brick 11";
CM_ SG_ 2566858487 BATT_capBrick09_1 "Capacity of brick 9";
CM_ SG_ 2566858487 BATT_capBrick10_1 "Capacity of brick 10";
CM_ BO_ 2566858488 "Capacity of bricks 9-12";
CM_ SG_ 2566858488 BATT_capBrick12_2 "Capacity of brick 12";
CM_ SG_ 2566858488 BATT_capBrick11_2 "Capacity of brick 11";
CM_ SG_ 2566858488 BATT_capBrick09_2 "Capacity of brick 9";
CM_ SG_ 2566858488 BATT_capBrick10_2 "Capacity of brick 10";
CM_ BO_ 2566858489 "Capacity of bricks 9-12";
CM_ SG_ 2566858489 BATT_capBrick12_3 "Capacity of brick 12";
CM_ SG_ 2566858489 BATT_capBrick11_3 "Capacity of brick 11";
CM_ SG_ 2566858489 BATT_capBrick09_3 "Capacity of brick 9";
CM_ SG_ 2566858489 BATT_capBrick10_3 "Capacity of brick 10";
CM_ BO_ 2566858490 "Capacity of bricks 9-12";
CM_ SG_ 2566858490 BATT_capBrick12_4 "Capacity of brick 12";
CM_ SG_ 2566858490 BATT_capBrick11_4 "Capacity of brick 11";
CM_ SG_ 2566858490 BATT_capBrick09_4 "Capacity of brick 9";
CM_ SG_ 2566858490 BATT_capBrick10_4 "Capacity of brick 10";
CM_ BO_ 2566858491 "Capacity of bricks 9-12";
CM_ SG_ 2566858491 BATT_capBrick12_5 "Capacity of brick 12";
CM_ SG_ 2566858491 BATT_capBrick11_5 "Capacity of brick 11";
CM_ SG_ 2566858491 BATT_capBrick09_5 "Capacity of brick 9";
CM_ SG_ 2566858491 BATT_capBrick10_5 "Capacity of brick 10";
CM_ BO_ 2566858492 "Capacity of bricks 9-12";
CM_ SG_ 2566858492 BATT_capBrick12_6 "Capacity of brick 12";
CM_ SG_ 2566858492 BATT_capBrick11_6 "Capacity of brick 11";
CM_ SG_ 2566858492 BATT_capBrick09_6 "Capacity of brick 9";
CM_ SG_ 2566858492 BATT_capBrick10_6 "Capacity of brick 10";
CM_ BO_ 2566858493 "Capacity of bricks 9-12";
CM_ SG_ 2566858493 BATT_capBrick12_7 "Capacity of brick 12";
CM_ SG_ 2566858493 BATT_capBrick11_7 "Capacity of brick 11";
CM_ SG_ 2566858493 BATT_capBrick09_7 "Capacity of brick 9";
CM_ SG_ 2566858493 BATT_capBrick10_7 "Capacity of brick 10";
CM_ BO_ 2566858494 "Capacity of bricks 9-12";
CM_ SG_ 2566858494 BATT_capBrick12_8 "Capacity of brick 12";
CM_ SG_ 2566858494 BATT_capBrick11_8 "Capacity of brick 11";
CM_ SG_ 2566858494 BATT_capBrick09_8 "Capacity of brick 9";
CM_ SG_ 2566858494 BATT_capBrick10_8 "Capacity of brick 10";
CM_ BO_ 2566858495 "Capacity of bricks 9-12";
CM_ SG_ 2566858495 BATT_capBrick12_9 "Capacity of brick 12";
CM_ SG_ 2566858495 BATT_capBrick11_9 "Capacity of brick 11";
CM_ SG_ 2566858495 BATT_capBrick09_9 "Capacity of brick 9";
CM_ SG_ 2566858495 BATT_capBrick10_9 "Capacity of brick 10";
CM_ BO_ 2566858742 "Voltages of bricks 9-12";
CM_ SG_ 2566858742 BATT_vBrick12_0 "Voltage of brick 12";
CM_ SG_ 2566858742 BATT_vBrick11_0 "Voltage of brick 11";
CM_ SG_ 2566858742 BATT_vBrick10_0 "Voltage of brick 10";
CM_ SG_ 2566858742 BATT_vBrick09_0 "Voltage of brick 9";
CM_ BO_ 2566858743 "Voltages of bricks 9-12";
CM_ SG_ 2566858743 BATT_vBrick12_1 "Voltage of brick 12";
CM_ SG_ 2566858743 BATT_vBrick11_1 "Voltage of brick 11";
CM_ SG_ 2566858743 BATT_vBrick10_1 "Voltage of brick 10";
CM_ SG_ 2566858743 BATT_vBrick09_1 "Voltage of brick 9";
CM_ BO_ 2566858744 "Voltages of bricks 9-12";
CM_ SG_ 2566858744 BATT_vBrick12_2 "Voltage of brick 12";
CM_ SG_ 2566858744 BATT_vBrick11_2 "Voltage of brick 11";
CM_ SG_ 2566858744 BATT_vBrick10_2 "Voltage of brick 10";
CM_ SG_ 2566858744 BATT_vBrick09_2 "Voltage of brick 9";
CM_ BO_ 2566858745 "Voltages of bricks 9-12";
CM_ SG_ 2566858745 BATT_vBrick12_3 "Voltage of brick 12";
CM_ SG_ 2566858745 BATT_vBrick11_3 "Voltage of brick 11";
CM_ SG_ 2566858745 BATT_vBrick10_3 "Voltage of brick 10";
CM_ SG_ 2566858745 BATT_vBrick09_3 "Voltage of brick 9";
CM_ BO_ 2566858746 "Voltages of bricks 9-12";
CM_ SG_ 2566858746 BATT_vBrick12_4 "Voltage of brick 12";
CM_ SG_ 2566858746 BATT_vBrick11_4 "Voltage of brick 11";
CM_ SG_ 2566858746 BATT_vBrick10_4 "Voltage of brick 10";
CM_ SG_ 2566858746 BATT_vBrick09_4 "Voltage of brick 9";
CM_ BO_ 2566858747 "Voltages of bricks 9-12";
CM_ SG_ 2566858747 BATT_vBrick12_5 "Voltage of brick 12";
CM_ SG_ 2566858747 BATT_vBrick11_5 "Voltage of brick 11";
CM_ SG_ 2566858747 BATT_vBrick10_5 "Voltage of brick 10";
CM_ SG_ 2566858747 BATT_vBrick09_5 "Voltage of brick 9";
CM_ BO_ 2566858748 "Voltages of bricks 9-12";
CM_ SG_ 2566858748 BATT_vBrick12_6 "Voltage of brick 12";
CM_ SG_ 2566858748 BATT_vBrick11_6 "Voltage of brick 11";
CM_ SG_ 2566858748 BATT_vBrick10_6 "Voltage of brick 10";
CM_ SG_ 2566858748 BATT_vBrick09_6 "Voltage of brick 9";
CM_ BO_ 2566858749 "Voltages of bricks 9-12";
CM_ SG_ 2566858749 BATT_vBrick12_7 "Voltage of brick 12";
CM_ SG_ 2566858749 BATT_vBrick11_7 "Voltage of brick 11";
CM_ SG_ 2566858749 BATT_vBrick10_7 "Voltage of brick 10";
CM_ SG_ 2566858749 BATT_vBrick09_7 "Voltage of brick 9";
CM_ BO_ 2566858750 "Voltages of bricks 9-12";
CM_ SG_ 2566858750 BATT_vBrick12_8 "Voltage of brick 12";
CM_ SG_ 2566858750 BATT_vBrick11_8 "Voltage of brick 11";
CM_ SG_ 2566858750 BATT_vBrick10_8 "Voltage of brick 10";
CM_ SG_ 2566858750 BATT_vBrick09_8 "Voltage of brick 9";
CM_ BO_ 2566858751 "Voltages of bricks 9-12";
CM_ SG_ 2566858751 BATT_vBrick12_9 "Voltage of brick 12";
CM_ SG_ 2566858751 BATT_vBrick11_9 "Voltage of brick 11";
CM_ SG_ 2566858751 BATT_vBrick10_9 "Voltage of brick 10";
CM_ SG_ 2566858751 BATT_vBrick09_9 "Voltage of brick 9";
CM_ BO_ 2566862582 "Capacity of bricks 13-14";
CM_ SG_ 2566862582 BATT_sohcUpdated_0 "SOHC Updated Mask";
CM_ SG_ 2566862582 BATT_sohcPrimed_0 "SOHC Primed Mask";
CM_ SG_ 2566862582 BATT_capBrick14_0 "Capacity of brick 14";
CM_ SG_ 2566862582 BATT_capBrick13_0 "Capacity of brick 13";
CM_ BO_ 2566862583 "Capacity of bricks 13-14";
CM_ SG_ 2566862583 BATT_sohcUpdated_1 "SOHC Updated Mask";
CM_ SG_ 2566862583 BATT_sohcPrimed_1 "SOHC Primed Mask";
CM_ SG_ 2566862583 BATT_capBrick14_1 "Capacity of brick 14";
CM_ SG_ 2566862583 BATT_capBrick13_1 "Capacity of brick 13";
CM_ BO_ 2566862584 "Capacity of bricks 13-14";
CM_ SG_ 2566862584 BATT_sohcUpdated_2 "SOHC Updated Mask";
CM_ SG_ 2566862584 BATT_sohcPrimed_2 "SOHC Primed Mask";
CM_ SG_ 2566862584 BATT_capBrick14_2 "Capacity of brick 14";
CM_ SG_ 2566862584 BATT_capBrick13_2 "Capacity of brick 13";
CM_ BO_ 2566862585 "Capacity of bricks 13-14";
CM_ SG_ 2566862585 BATT_sohcUpdated_3 "SOHC Updated Mask";
CM_ SG_ 2566862585 BATT_sohcPrimed_3 "SOHC Primed Mask";
CM_ SG_ 2566862585 BATT_capBrick14_3 "Capacity of brick 14";
CM_ SG_ 2566862585 BATT_capBrick13_3 "Capacity of brick 13";
CM_ BO_ 2566862586 "Capacity of bricks 13-14";
CM_ SG_ 2566862586 BATT_sohcUpdated_4 "SOHC Updated Mask";
CM_ SG_ 2566862586 BATT_sohcPrimed_4 "SOHC Primed Mask";
CM_ SG_ 2566862586 BATT_capBrick14_4 "Capacity of brick 14";
CM_ SG_ 2566862586 BATT_capBrick13_4 "Capacity of brick 13";
CM_ BO_ 2566862587 "Capacity of bricks 13-14";
CM_ SG_ 2566862587 BATT_sohcUpdated_5 "SOHC Updated Mask";
CM_ SG_ 2566862587 BATT_sohcPrimed_5 "SOHC Primed Mask";
CM_ SG_ 2566862587 BATT_capBrick14_5 "Capacity of brick 14";
CM_ SG_ 2566862587 BATT_capBrick13_5 "Capacity of brick 13";
CM_ BO_ 2566862588 "Capacity of bricks 13-14";
CM_ SG_ 2566862588 BATT_sohcUpdated_6 "SOHC Updated Mask";
CM_ SG_ 2566862588 BATT_sohcPrimed_6 "SOHC Primed Mask";
CM_ SG_ 2566862588 BATT_capBrick14_6 "Capacity of brick 14";
CM_ SG_ 2566862588 BATT_capBrick13_6 "Capacity of brick 13";
CM_ BO_ 2566862589 "Capacity of bricks 13-14";
CM_ SG_ 2566862589 BATT_sohcUpdated_7 "SOHC Updated Mask";
CM_ SG_ 2566862589 BATT_sohcPrimed_7 "SOHC Primed Mask";
CM_ SG_ 2566862589 BATT_capBrick14_7 "Capacity of brick 14";
CM_ SG_ 2566862589 BATT_capBrick13_7 "Capacity of brick 13";
CM_ BO_ 2566862590 "Capacity of bricks 13-14";
CM_ SG_ 2566862590 BATT_sohcUpdated_8 "SOHC Updated Mask";
CM_ SG_ 2566862590 BATT_sohcPrimed_8 "SOHC Primed Mask";
CM_ SG_ 2566862590 BATT_capBrick14_8 "Capacity of brick 14";
CM_ SG_ 2566862590 BATT_capBrick13_8 "Capacity of brick 13";
CM_ BO_ 2566862591 "Capacity of bricks 13-14";
CM_ SG_ 2566862591 BATT_sohcUpdated_9 "SOHC Updated Mask";
CM_ SG_ 2566862591 BATT_sohcPrimed_9 "SOHC Primed Mask";
CM_ SG_ 2566862591 BATT_capBrick14_9 "Capacity of brick 14";
CM_ SG_ 2566862591 BATT_capBrick13_9 "Capacity of brick 13";
CM_ BO_ 2566862838 "Voltages of bricks 13-14";
CM_ SG_ 2566862838 BATT_vBrick14_0 "Voltage of brick 14";
CM_ SG_ 2566862838 BATT_vBrick13_0 "Voltage of brick 13";
CM_ BO_ 2566862839 "Voltages of bricks 13-14";
CM_ SG_ 2566862839 BATT_vBrick14_1 "Voltage of brick 14";
CM_ SG_ 2566862839 BATT_vBrick13_1 "Voltage of brick 13";
CM_ BO_ 2566862840 "Voltages of bricks 13-14";
CM_ SG_ 2566862840 BATT_vBrick14_2 "Voltage of brick 14";
CM_ SG_ 2566862840 BATT_vBrick13_2 "Voltage of brick 13";
CM_ BO_ 2566862841 "Voltages of bricks 13-14";
CM_ SG_ 2566862841 BATT_vBrick14_3 "Voltage of brick 14";
CM_ SG_ 2566862841 BATT_vBrick13_3 "Voltage of brick 13";
CM_ BO_ 2566862842 "Voltages of bricks 13-14";
CM_ SG_ 2566862842 BATT_vBrick14_4 "Voltage of brick 14";
CM_ SG_ 2566862842 BATT_vBrick13_4 "Voltage of brick 13";
CM_ BO_ 2566862843 "Voltages of bricks 13-14";
CM_ SG_ 2566862843 BATT_vBrick14_5 "Voltage of brick 14";
CM_ SG_ 2566862843 BATT_vBrick13_5 "Voltage of brick 13";
CM_ BO_ 2566862844 "Voltages of bricks 13-14";
CM_ SG_ 2566862844 BATT_vBrick14_6 "Voltage of brick 14";
CM_ SG_ 2566862844 BATT_vBrick13_6 "Voltage of brick 13";
CM_ BO_ 2566862845 "Voltages of bricks 13-14";
CM_ SG_ 2566862845 BATT_vBrick14_7 "Voltage of brick 14";
CM_ SG_ 2566862845 BATT_vBrick13_7 "Voltage of brick 13";
CM_ BO_ 2566862846 "Voltages of bricks 13-14";
CM_ SG_ 2566862846 BATT_vBrick14_8 "Voltage of brick 14";
CM_ SG_ 2566862846 BATT_vBrick13_8 "Voltage of brick 13";
CM_ BO_ 2566862847 "Voltages of bricks 13-14";
CM_ SG_ 2566862847 BATT_vBrick14_9 "Voltage of brick 14";
CM_ SG_ 2566862847 BATT_vBrick13_9 "Voltage of brick 13";
CM_ SG_ 2566865397 BATT_iPackFiltered "Filtered charge/discharge rate in ampere - positive for charge, negative for discharge.";
CM_ SG_ 2566865397 BATT_vPack "Voltage of the pack";
CM_ SG_ 2566865397 BATT_vPackLoad "Voltage measured across load";
CM_ SG_ 2566865397 BATT_iPack "Pack current - combined current of all modules";
CM_ BO_ 2566866165 "Battery min-max data";
CM_ SG_ 2566866165 BATT_vPackModuleMinID "ID of minimum brick voltage ";
CM_ SG_ 2566866165 BATT_vPackBrickMin "Minimum brick voltage ";
CM_ SG_ 2566866165 BATT_vPackModuleMaxID "ID of maximum brick voltage ";
CM_ SG_ 2566866165 BATT_vPackBrickMax "Maximum brick voltage ";
CM_ SG_ 2566866165 BATT_tPackModuleMinID "ID of minimum Battery temperature ";
CM_ SG_ 2566866165 BATT_tPackModuleMin "Minimum Battery temperature";
CM_ SG_ 2566866165 BATT_tPackModuleMaxID "ID of maximum Battery temperature ";
CM_ SG_ 2566866165 BATT_tPackModuleMax "Maximum Battery temperature";
BA_DEF_ SG_  "SigType" ENUM "Default","Range","RangeSigned","ASCII","Discrete","Control","ReferencePGN","DTC","StringDelimiter","StringLength","StringLengthControl","MessageCounter","MessageChecksum";
BA_DEF_ SG_  "GenSigSendType" ENUM "Cyclic","OnWrite","OnWriteWithRepetition","OnChange","OnChangeWithRepetition","IfActive","IfActiveWithRepetition","NoSigSendType";
BA_DEF_ BO_  "GenMsgDiag" ENUM "No","Yes";
BA_DEF_ BO_  "GenMsgInstanced" STRING ;
BA_DEF_ SG_  "GenSigType" ENUM "Extended","Diagnostic","Standard","Modified";
BA_DEF_ BO_  "GenMsgCycleTime" INT 0 0;
BA_DEF_ SG_  "GenSigSNA" INT 0 65535;
BA_DEF_ SG_  "Access" ENUM "r","rw";
BA_DEF_ BO_  "VFrameFormat" ENUM "StandardCAN","ExtendedCAN","reserved","J1939PG";
BA_DEF_DEF_  "SigType" "Default";
BA_DEF_DEF_  "GenSigSendType" "Cyclic";
BA_DEF_DEF_  "GenMsgDiag" "No";
BA_DEF_DEF_  "GenMsgInstanced" "No";
BA_DEF_DEF_  "GenSigType" "Standard";
BA_DEF_DEF_  "GenMsgCycleTime" 0;
BA_DEF_DEF_  "GenSigSNA" 0;
BA_DEF_DEF_  "Access" "r";
BA_DEF_DEF_  "VFrameFormat" "J1939PG";
BA_ "GenMsgDiag" BO_ 2566854390 1;
BA_ "GenMsgDiag" BO_ 2566854391 1;
BA_ "GenMsgDiag" BO_ 2566854392 1;
BA_ "GenMsgDiag" BO_ 2566854393 1;
BA_ "GenMsgDiag" BO_ 2566854394 1;
BA_ "GenMsgDiag" BO_ 2566854395 1;
BA_ "GenMsgDiag" BO_ 2566854396 1;
BA_ "GenMsgDiag" BO_ 2566854397 1;
BA_ "GenMsgDiag" BO_ 2566854398 1;
BA_ "GenMsgDiag" BO_ 2566854399 1;
BA_ "GenMsgDiag" BO_ 2566854646 1;
BA_ "GenMsgDiag" BO_ 2566854647 1;
BA_ "GenMsgDiag" BO_ 2566854648 1;
BA_ "GenMsgDiag" BO_ 2566854649 1;
BA_ "GenMsgDiag" BO_ 2566854650 1;
BA_ "GenMsgDiag" BO_ 2566854651 1;
BA_ "GenMsgDiag" BO_ 2566854652 1;
BA_ "GenMsgDiag" BO_ 2566854653 1;
BA_ "GenMsgDiag" BO_ 2566854654 1;
BA_ "GenMsgDiag" BO_ 2566854655 1;
BA_ "GenMsgDiag" BO_ 2566855158 1;
BA_ "GenMsgDiag" BO_ 2566855159 1;
BA_ "GenMsgDiag" BO_ 2566855160 1;
BA_ "GenMsgDiag" BO_ 2566855161 1;
BA_ "GenMsgDiag" BO_ 2566855162 1;
BA_ "GenMsgDiag" BO_ 2566855163 1;
BA_ "GenMsgDiag" BO_ 2566855164 1;
BA_ "GenMsgDiag" BO_ 2566855165 1;
BA_ "GenMsgDiag" BO_ 2566855166 1;
BA_ "GenMsgDiag" BO_ 2566855167 1;
BA_ "GenMsgDiag" BO_ 2566858486 1;
BA_ "GenMsgDiag" BO_ 2566858487 1;
BA_ "GenMsgDiag" BO_ 2566858488 1;
BA_ "GenMsgDiag" BO_ 2566858489 1;
BA_ "GenMsgDiag" BO_ 2566858490 1;
BA_ "GenMsgDiag" BO_ 2566858491 1;
BA_ "GenMsgDiag" BO_ 2566858492 1;
BA_ "GenMsgDiag" BO_ 2566858493 1;
BA_ "GenMsgDiag" BO_ 2566858494 1;
BA_ "GenMsgDiag" BO_ 2566858495 1;
BA_ "GenMsgDiag" BO_ 2566858742 1;
BA_ "GenMsgDiag" BO_ 2566858743 1;
BA_ "GenMsgDiag" BO_ 2566858744 1;
BA_ "GenMsgDiag" BO_ 2566858745 1;
BA_ "GenMsgDiag" BO_ 2566858746 1;
BA_ "GenMsgDiag" BO_ 2566858747 1;
BA_ "GenMsgDiag" BO_ 2566858748 1;
BA_ "GenMsgDiag" BO_ 2566858749 1;
BA_ "GenMsgDiag" BO_ 2566858750 1;
BA_ "GenMsgDiag" BO_ 2566858751 1;
BA_ "GenMsgDiag" BO_ 2566862582 1;
BA_ "GenMsgDiag" BO_ 2566862583 1;
BA_ "GenMsgDiag" BO_ 2566862584 1;
BA_ "GenMsgDiag" BO_ 2566862585 1;
BA_ "GenMsgDiag" BO_ 2566862586 1;
BA_ "GenMsgDiag" BO_ 2566862587 1;
BA_ "GenMsgDiag" BO_ 2566862588 1;
BA_ "GenMsgDiag" BO_ 2566862589 1;
BA_ "GenMsgDiag" BO_ 2566862590 1;
BA_ "GenMsgDiag" BO_ 2566862591 1;
BA_ "GenMsgDiag" BO_ 2566862838 1;
BA_ "GenMsgDiag" BO_ 2566862839 1;
BA_ "GenMsgDiag" BO_ 2566862840 1;
BA_ "GenMsgDiag" BO_ 2566862841 1;
BA_ "GenMsgDiag" BO_ 2566862842 1;
BA_ "GenMsgDiag" BO_ 2566862843 1;
BA_ "GenMsgDiag" BO_ 2566862844 1;
BA_ "GenMsgDiag" BO_ 2566862845 1;
BA_ "GenMsgDiag" BO_ 2566862846 1;
BA_ "GenMsgDiag" BO_ 2566862847 1;
BA_ "GenMsgInstanced" BO_ 2566852863 "False";
BA_ "GenMsgInstanced" BO_ 2566853110 "False";
BA_ "GenMsgInstanced" BO_ 2566853111 "False";
BA_ "GenMsgInstanced" BO_ 2566853112 "False";
BA_ "GenMsgInstanced" BO_ 2566853113 "False";
BA_ "GenMsgInstanced" BO_ 2566853114 "False";
BA_ "GenMsgInstanced" BO_ 2566853115 "False";
BA_ "GenMsgInstanced" BO_ 2566853116 "False";
BA_ "GenMsgInstanced" BO_ 2566853117 "False";
BA_ "GenMsgInstanced" BO_ 2566853118 "False";
BA_ "GenMsgInstanced" BO_ 2566853119 "False";
BA_ "GenMsgInstanced" BO_ 2566853622 "False";
BA_ "GenMsgInstanced" BO_ 2566853877 "False";
BA_ "GenMsgInstanced" BO_ 2566854134 "False";
BA_ "GenMsgInstanced" BO_ 2566854390 "False";
BA_ "GenMsgInstanced" BO_ 2566854391 "False";
BA_ "GenMsgInstanced" BO_ 2566854392 "False";
BA_ "GenMsgInstanced" BO_ 2566854393 "False";
BA_ "GenMsgInstanced" BO_ 2566854394 "False";
BA_ "GenMsgInstanced" BO_ 2566854395 "False";
BA_ "GenMsgInstanced" BO_ 2566854396 "False";
BA_ "GenMsgInstanced" BO_ 2566854397 "False";
BA_ "GenMsgInstanced" BO_ 2566854398 "False";
BA_ "GenMsgInstanced" BO_ 2566854399 "False";
BA_ "GenMsgInstanced" BO_ 2566854646 "False";
BA_ "GenMsgInstanced" BO_ 2566854647 "False";
BA_ "GenMsgInstanced" BO_ 2566854648 "False";
BA_ "GenMsgInstanced" BO_ 2566854649 "False";
BA_ "GenMsgInstanced" BO_ 2566854650 "False";
BA_ "GenMsgInstanced" BO_ 2566854651 "False";
BA_ "GenMsgInstanced" BO_ 2566854652 "False";
BA_ "GenMsgInstanced" BO_ 2566854653 "False";
BA_ "GenMsgInstanced" BO_ 2566854654 "False";
BA_ "GenMsgInstanced" BO_ 2566854655 "False";
BA_ "GenMsgInstanced" BO_ 2566854902 "False";
BA_ "GenMsgInstanced" BO_ 2566855158 "False";
BA_ "GenMsgInstanced" BO_ 2566855159 "False";
BA_ "GenMsgInstanced" BO_ 2566855160 "False";
BA_ "GenMsgInstanced" BO_ 2566855161 "False";
BA_ "GenMsgInstanced" BO_ 2566855162 "False";
BA_ "GenMsgInstanced" BO_ 2566855163 "False";
BA_ "GenMsgInstanced" BO_ 2566855164 "False";
BA_ "GenMsgInstanced" BO_ 2566855165 "False";
BA_ "GenMsgInstanced" BO_ 2566855166 "False";
BA_ "GenMsgInstanced" BO_ 2566855167 "False";
BA_ "GenMsgInstanced" BO_ 2566856694 "False";
BA_ "GenMsgInstanced" BO_ 2566856695 "False";
BA_ "GenMsgInstanced" BO_ 2566856696 "False";
BA_ "GenMsgInstanced" BO_ 2566856697 "False";
BA_ "GenMsgInstanced" BO_ 2566856698 "False";
BA_ "GenMsgInstanced" BO_ 2566856699 "False";
BA_ "GenMsgInstanced" BO_ 2566856700 "False";
BA_ "GenMsgInstanced" BO_ 2566856701 "False";
BA_ "GenMsgInstanced" BO_ 2566856702 "False";
BA_ "GenMsgInstanced" BO_ 2566856703 "False";
BA_ "GenMsgInstanced" BO_ 2566857718 "False";
BA_ "GenMsgInstanced" BO_ 2566858230 "False";
BA_ "GenMsgInstanced" BO_ 2566858486 "False";
BA_ "GenMsgInstanced" BO_ 2566858487 "False";
BA_ "GenMsgInstanced" BO_ 2566858488 "False";
BA_ "GenMsgInstanced" BO_ 2566858489 "False";
BA_ "GenMsgInstanced" BO_ 2566858490 "False";
BA_ "GenMsgInstanced" BO_ 2566858491 "False";
BA_ "GenMsgInstanced" BO_ 2566858492 "False";
BA_ "GenMsgInstanced" BO_ 2566858493 "False";
BA_ "GenMsgInstanced" BO_ 2566858494 "False";
BA_ "GenMsgInstanced" BO_ 2566858495 "False";
BA_ "GenMsgInstanced" BO_ 2566858742 "False";
BA_ "GenMsgInstanced" BO_ 2566858743 "False";
BA_ "GenMsgInstanced" BO_ 2566858744 "False";
BA_ "GenMsgInstanced" BO_ 2566858745 "False";
BA_ "GenMsgInstanced" BO_ 2566858746 "False";
BA_ "GenMsgInstanced" BO_ 2566858747 "False";
BA_ "GenMsgInstanced" BO_ 2566858748 "False";
BA_ "GenMsgInstanced" BO_ 2566858749 "False";
BA_ "GenMsgInstanced" BO_ 2566858750 "False";
BA_ "GenMsgInstanced" BO_ 2566858751 "False";
BA_ "GenMsgInstanced" BO_ 2566858998 "False";
BA_ "GenMsgInstanced" BO_ 2566861814 "False";
BA_ "GenMsgInstanced" BO_ 2566862326 "False";
BA_ "GenMsgInstanced" BO_ 2566862582 "False";
BA_ "GenMsgInstanced" BO_ 2566862583 "False";
BA_ "GenMsgInstanced" BO_ 2566862584 "False";
BA_ "GenMsgInstanced" BO_ 2566862585 "False";
BA_ "GenMsgInstanced" BO_ 2566862586 "False";
BA_ "GenMsgInstanced" BO_ 2566862587 "False";
BA_ "GenMsgInstanced" BO_ 2566862588 "False";
BA_ "GenMsgInstanced" BO_ 2566862589 "False";
BA_ "GenMsgInstanced" BO_ 2566862590 "False";
BA_ "GenMsgInstanced" BO_ 2566862591 "False";
BA_ "GenMsgInstanced" BO_ 2566862838 "False";
BA_ "GenMsgInstanced" BO_ 2566862839 "False";
BA_ "GenMsgInstanced" BO_ 2566862840 "False";
BA_ "GenMsgInstanced" BO_ 2566862841 "False";
BA_ "GenMsgInstanced" BO_ 2566862842 "False";
BA_ "GenMsgInstanced" BO_ 2566862843 "False";
BA_ "GenMsgInstanced" BO_ 2566862844 "False";
BA_ "GenMsgInstanced" BO_ 2566862845 "False";
BA_ "GenMsgInstanced" BO_ 2566862846 "False";
BA_ "GenMsgInstanced" BO_ 2566862847 "False";
BA_ "GenMsgInstanced" BO_ 2566863094 "False";
BA_ "GenMsgInstanced" BO_ 2566865141 "False";
BA_ "GenMsgInstanced" BO_ 2566865397 "False";
BA_ "GenMsgInstanced" BO_ 2566866165 "False";
BA_ "GenSigType" SG_ 2566852863 BATT_tempBoardOverSev_9 1;
BA_ "GenSigType" SG_ 2566852863 BATT_bmsProcessorError_9 1;
BA_ "GenSigType" SG_ 2566852863 BATT_tempBoardOverWar_9 1;
BA_ "GenSigType" SG_ 2566852863 BATT_brickOverCharge_9 1;
BA_ "GenSigType" SG_ 2566852863 BATT_brickOverDischarge_9 1;
BA_ "GenSigType" SG_ 2566852863 BATT_tempModuleOverWar_9 1;
BA_ "GenSigType" SG_ 2566852863 BATT_bmsMemoryError_9 1;
BA_ "GenSigType" SG_ 2566852863 BATT_tempModuleUnderMod_9 1;
BA_ "GenSigType" SG_ 2566852863 BATT_afeError_9 1;
BA_ "GenSigType" SG_ 2566852863 BATT_sensePackVoltError_9 1;
BA_ "GenSigType" SG_ 2566852863 BATT_iOverHardware_9 1;
BA_ "GenSigType" SG_ 2566852863 BATT_packModIdFault_9 1;
BA_ "GenSigType" SG_ 2566852863 BATT_packCellSoftShort_9 1;
BA_ "GenSigType" SG_ 2566852863 BATT_tempBoardOverMod_9 1;
BA_ "GenSigType" SG_ 2566852863 BATT_fetChgShortedAux_9 1;
BA_ "GenSigType" SG_ 2566852863 BATT_tempModuleOverMod_9 1;
BA_ "GenSigType" SG_ 2566852863 BATT_tempModuleOverSev_9 1;
BA_ "GenSigType" SG_ 2566852863 BATT_taskLockupError_9 1;
BA_ "GenSigType" SG_ 2566852863 BATT_tempBrickImbalance_9 1;
BA_ "GenSigType" SG_ 2566852863 BATT_vBrickUnderWar_9 1;
BA_ "GenSigType" SG_ 2566852863 BATT_iOverDischarge_9 1;
BA_ "GenSigType" SG_ 2566852863 BATT_vBrickOverMod_9 1;
BA_ "GenSigType" SG_ 2566852863 BATT_fetDsgFailToClose_9 1;
BA_ "GenSigType" SG_ 2566852863 BATT_prechargeFetFail_9 1;
BA_ "GenSigType" SG_ 2566852863 BATT_capLow_9 1;
BA_ "GenSigType" SG_ 2566852863 BATT_fetDsgShortedAux_9 1;
BA_ "GenSigType" SG_ 2566852863 BATT_packFetDsgWelded_9 1;
BA_ "GenSigType" SG_ 2566852863 BATT_packModExitedFromBus_9 1;
BA_ "GenSigType" SG_ 2566852863 BATT_packFetChgWelded_9 1;
BA_ "GenSigType" SG_ 2566852863 BATT_vBrickImbalance_9 1;
BA_ "GenSigType" SG_ 2566852863 BATT_fetChgFailToClose_9 1;
BA_ "GenSigType" SG_ 2566852863 BATT_packModSelectFault_9 1;
BA_ "GenSigType" SG_ 2566852863 BATT_ramOverUtilError_9 1;
BA_ "GenSigType" SG_ 2566852863 BATT_packModMIA_9 1;
BA_ "GenSigType" SG_ 2566852863 BATT_resPackHigh_9 1;
BA_ "GenSigType" SG_ 2566852863 BATT_chargerError_9 1;
BA_ "GenSigType" SG_ 2566852863 BATT_powerPackInsufficient_9 1;
BA_ "GenSigType" SG_ 2566852863 BATT_packModConnectFault_9 1;
BA_ "GenSigType" SG_ 2566852863 BATT_packModImbalance_9 1;
BA_ "GenSigType" SG_ 2566852863 BATT_senseLoadVoltError_9 1;
BA_ "GenSigType" SG_ 2566852863 BATT_abnormalResetReason_9 1;
BA_ "GenSigType" SG_ 2566852863 BATT_iUnderCharge_9 1;
BA_ "GenSigType" SG_ 2566852863 BATT_fetDsgShorted_9 1;
BA_ "GenSigType" SG_ 2566852863 BATT_inverterDriveMIA_9 1;
BA_ "GenSigType" SG_ 2566852863 BATT_loggerFull_9 1;
BA_ "GenSigType" SG_ 2566852863 BATT_hostMIA_9 1;
BA_ "GenSigType" SG_ 2566852863 BATT_senseCurrentError_9 1;
BA_ "GenSigType" SG_ 2566852863 BATT_senseBrickTempError_9 1;
BA_ "GenSigType" SG_ 2566852863 BATT_iOverCharge_9 1;
BA_ "GenSigType" SG_ 2566852863 BATT_prechargeTooSlow_9 1;
BA_ "GenSigType" SG_ 2566852863 BATT_prechargeTooFast_9 1;
BA_ "GenSigType" SG_ 2566852863 BATT_prechargeTimeout_9 1;
BA_ "GenSigType" SG_ 2566852863 BATT_fetChgShorted_9 1;
BA_ "GenSigType" SG_ 2566852863 BATT_vBrickUnderMod_9 1;
BA_ "GenSigType" SG_ 2566852863 BATT_chargerMIA_9 1;
BA_ "GenSigType" SG_ 2566852863 BATT_vBrickUnderSev_9 1;
BA_ "GenSigType" SG_ 2566852863 BATT_afeFault_9 1;
BA_ "GenSigType" SG_ 2566852863 BATT_tempModuleUnderWar_9 1;
BA_ "GenSigType" SG_ 2566852863 BATT_tempModuleUnderSev_9 1;
BA_ "GenSigType" SG_ 2566852863 BATT_fetOverTemp_9 1;
BA_ "GenSigType" SG_ 2566852863 BATT_loggerAlmostFull_9 1;
BA_ "GenSigType" SG_ 2566852863 BATT_vBrickOverWar_9 1;
BA_ "GenSigType" SG_ 2566852863 BATT_vBrickOverSev_9 1;
BA_ "GenSigType" SG_ 2566853110 BATT_packModCurrImbalance_0 1;
BA_ "GenSigType" SG_ 2566853110 BATT_flashAppCRCError_0 1;
BA_ "GenSigType" SG_ 2566853110 BATT_modThermistorOpenWire_0 1;
BA_ "GenSigType" SG_ 2566853110 BATT_vBrickImbalanceWarning_0 1;
BA_ "GenSigType" SG_ 2566853110 BATT_multiIgnLoFault_0 1;
BA_ "GenSigType" SG_ 2566853110 BATT_flashBootCRCError_0 1;
BA_ "GenSigType" SG_ 2566853110 BATT_cellOpenWire_0 1;
BA_ "GenSigType" SG_ 2566853110 BATT_packLevelArbitrationFault_0 1;
BA_ "GenSigType" SG_ 2566853110 BATT_harnessImpedanceFault_0 1;
BA_ "GenSigType" SG_ 2566853110 BATT_chargeNotNeeded_0 1;
BA_ "GenSigType" SG_ 2566853110 BATT_packModTempImbalance_0 1;
BA_ "GenSigType" SG_ 2566853110 BATT_modThermistorShorted_0 1;
BA_ "GenSigType" SG_ 2566853111 BATT_harnessImpedanceFault_1 1;
BA_ "GenSigType" SG_ 2566853111 BATT_vBrickImbalanceWarning_1 1;
BA_ "GenSigType" SG_ 2566853111 BATT_flashAppCRCError_1 1;
BA_ "GenSigType" SG_ 2566853111 BATT_cellOpenWire_1 1;
BA_ "GenSigType" SG_ 2566853111 BATT_packModCurrImbalance_1 1;
BA_ "GenSigType" SG_ 2566853111 BATT_flashBootCRCError_1 1;
BA_ "GenSigType" SG_ 2566853111 BATT_chargeNotNeeded_1 1;
BA_ "GenSigType" SG_ 2566853111 BATT_packModTempImbalance_1 1;
BA_ "GenSigType" SG_ 2566853111 BATT_modThermistorShorted_1 1;
BA_ "GenSigType" SG_ 2566853111 BATT_modThermistorOpenWire_1 1;
BA_ "GenSigType" SG_ 2566853111 BATT_packLevelArbitrationFault_1 1;
BA_ "GenSigType" SG_ 2566853111 BATT_multiIgnLoFault_1 1;
BA_ "GenSigType" SG_ 2566853112 BATT_flashAppCRCError_2 1;
BA_ "GenSigType" SG_ 2566853112 BATT_cellOpenWire_2 1;
BA_ "GenSigType" SG_ 2566853112 BATT_packModCurrImbalance_2 1;
BA_ "GenSigType" SG_ 2566853112 BATT_modThermistorOpenWire_2 1;
BA_ "GenSigType" SG_ 2566853112 BATT_flashBootCRCError_2 1;
BA_ "GenSigType" SG_ 2566853112 BATT_chargeNotNeeded_2 1;
BA_ "GenSigType" SG_ 2566853112 BATT_packModTempImbalance_2 1;
BA_ "GenSigType" SG_ 2566853112 BATT_vBrickImbalanceWarning_2 1;
BA_ "GenSigType" SG_ 2566853112 BATT_harnessImpedanceFault_2 1;
BA_ "GenSigType" SG_ 2566853112 BATT_packLevelArbitrationFault_2 1;
BA_ "GenSigType" SG_ 2566853112 BATT_multiIgnLoFault_2 1;
BA_ "GenSigType" SG_ 2566853112 BATT_modThermistorShorted_2 1;
BA_ "GenSigType" SG_ 2566853113 BATT_cellOpenWire_3 1;
BA_ "GenSigType" SG_ 2566853113 BATT_modThermistorShorted_3 1;
BA_ "GenSigType" SG_ 2566853113 BATT_modThermistorOpenWire_3 1;
BA_ "GenSigType" SG_ 2566853113 BATT_multiIgnLoFault_3 1;
BA_ "GenSigType" SG_ 2566853113 BATT_harnessImpedanceFault_3 1;
BA_ "GenSigType" SG_ 2566853113 BATT_vBrickImbalanceWarning_3 1;
BA_ "GenSigType" SG_ 2566853113 BATT_packLevelArbitrationFault_3 1;
BA_ "GenSigType" SG_ 2566853113 BATT_packModCurrImbalance_3 1;
BA_ "GenSigType" SG_ 2566853113 BATT_flashAppCRCError_3 1;
BA_ "GenSigType" SG_ 2566853113 BATT_flashBootCRCError_3 1;
BA_ "GenSigType" SG_ 2566853113 BATT_chargeNotNeeded_3 1;
BA_ "GenSigType" SG_ 2566853113 BATT_packModTempImbalance_3 1;
BA_ "GenSigType" SG_ 2566853114 BATT_modThermistorOpenWire_4 1;
BA_ "GenSigType" SG_ 2566853114 BATT_modThermistorShorted_4 1;
BA_ "GenSigType" SG_ 2566853114 BATT_multiIgnLoFault_4 1;
BA_ "GenSigType" SG_ 2566853114 BATT_packLevelArbitrationFault_4 1;
BA_ "GenSigType" SG_ 2566853114 BATT_vBrickImbalanceWarning_4 1;
BA_ "GenSigType" SG_ 2566853114 BATT_flashAppCRCError_4 1;
BA_ "GenSigType" SG_ 2566853114 BATT_harnessImpedanceFault_4 1;
BA_ "GenSigType" SG_ 2566853114 BATT_packModCurrImbalance_4 1;
BA_ "GenSigType" SG_ 2566853114 BATT_cellOpenWire_4 1;
BA_ "GenSigType" SG_ 2566853114 BATT_flashBootCRCError_4 1;
BA_ "GenSigType" SG_ 2566853114 BATT_chargeNotNeeded_4 1;
BA_ "GenSigType" SG_ 2566853114 BATT_packModTempImbalance_4 1;
BA_ "GenSigType" SG_ 2566853115 BATT_packModTempImbalance_5 1;
BA_ "GenSigType" SG_ 2566853115 BATT_packModCurrImbalance_5 1;
BA_ "GenSigType" SG_ 2566853115 BATT_modThermistorOpenWire_5 1;
BA_ "GenSigType" SG_ 2566853115 BATT_chargeNotNeeded_5 1;
BA_ "GenSigType" SG_ 2566853115 BATT_cellOpenWire_5 1;
BA_ "GenSigType" SG_ 2566853115 BATT_multiIgnLoFault_5 1;
BA_ "GenSigType" SG_ 2566853115 BATT_modThermistorShorted_5 1;
BA_ "GenSigType" SG_ 2566853115 BATT_flashBootCRCError_5 1;
BA_ "GenSigType" SG_ 2566853115 BATT_flashAppCRCError_5 1;
BA_ "GenSigType" SG_ 2566853115 BATT_harnessImpedanceFault_5 1;
BA_ "GenSigType" SG_ 2566853115 BATT_packLevelArbitrationFault_5 1;
BA_ "GenSigType" SG_ 2566853115 BATT_vBrickImbalanceWarning_5 1;
BA_ "GenSigType" SG_ 2566853116 BATT_packModTempImbalance_6 1;
BA_ "GenSigType" SG_ 2566853116 BATT_vBrickImbalanceWarning_6 1;
BA_ "GenSigType" SG_ 2566853116 BATT_flashAppCRCError_6 1;
BA_ "GenSigType" SG_ 2566853116 BATT_cellOpenWire_6 1;
BA_ "GenSigType" SG_ 2566853116 BATT_packModCurrImbalance_6 1;
BA_ "GenSigType" SG_ 2566853116 BATT_flashBootCRCError_6 1;
BA_ "GenSigType" SG_ 2566853116 BATT_modThermistorOpenWire_6 1;
BA_ "GenSigType" SG_ 2566853116 BATT_chargeNotNeeded_6 1;
BA_ "GenSigType" SG_ 2566853116 BATT_multiIgnLoFault_6 1;
BA_ "GenSigType" SG_ 2566853116 BATT_modThermistorShorted_6 1;
BA_ "GenSigType" SG_ 2566853116 BATT_harnessImpedanceFault_6 1;
BA_ "GenSigType" SG_ 2566853116 BATT_packLevelArbitrationFault_6 1;
BA_ "GenSigType" SG_ 2566853117 BATT_modThermistorOpenWire_7 1;
BA_ "GenSigType" SG_ 2566853117 BATT_vBrickImbalanceWarning_7 1;
BA_ "GenSigType" SG_ 2566853117 BATT_harnessImpedanceFault_7 1;
BA_ "GenSigType" SG_ 2566853117 BATT_packLevelArbitrationFault_7 1;
BA_ "GenSigType" SG_ 2566853117 BATT_packModCurrImbalance_7 1;
BA_ "GenSigType" SG_ 2566853117 BATT_flashBootCRCError_7 1;
BA_ "GenSigType" SG_ 2566853117 BATT_chargeNotNeeded_7 1;
BA_ "GenSigType" SG_ 2566853117 BATT_packModTempImbalance_7 1;
BA_ "GenSigType" SG_ 2566853117 BATT_flashAppCRCError_7 1;
BA_ "GenSigType" SG_ 2566853117 BATT_cellOpenWire_7 1;
BA_ "GenSigType" SG_ 2566853117 BATT_multiIgnLoFault_7 1;
BA_ "GenSigType" SG_ 2566853117 BATT_modThermistorShorted_7 1;
BA_ "GenSigType" SG_ 2566853118 BATT_packModCurrImbalance_8 1;
BA_ "GenSigType" SG_ 2566853118 BATT_flashBootCRCError_8 1;
BA_ "GenSigType" SG_ 2566853118 BATT_flashAppCRCError_8 1;
BA_ "GenSigType" SG_ 2566853118 BATT_cellOpenWire_8 1;
BA_ "GenSigType" SG_ 2566853118 BATT_chargeNotNeeded_8 1;
BA_ "GenSigType" SG_ 2566853118 BATT_packModTempImbalance_8 1;
BA_ "GenSigType" SG_ 2566853118 BATT_modThermistorShorted_8 1;
BA_ "GenSigType" SG_ 2566853118 BATT_modThermistorOpenWire_8 1;
BA_ "GenSigType" SG_ 2566853118 BATT_packLevelArbitrationFault_8 1;
BA_ "GenSigType" SG_ 2566853118 BATT_multiIgnLoFault_8 1;
BA_ "GenSigType" SG_ 2566853118 BATT_vBrickImbalanceWarning_8 1;
BA_ "GenSigType" SG_ 2566853118 BATT_harnessImpedanceFault_8 1;
BA_ "GenSigType" SG_ 2566853119 BATT_cellOpenWire_9 1;
BA_ "GenSigType" SG_ 2566853119 BATT_flashBootCRCError_9 1;
BA_ "GenSigType" SG_ 2566853119 BATT_flashAppCRCError_9 1;
BA_ "GenSigType" SG_ 2566853119 BATT_packModTempImbalance_9 1;
BA_ "GenSigType" SG_ 2566853119 BATT_packModCurrImbalance_9 1;
BA_ "GenSigType" SG_ 2566853119 BATT_modThermistorOpenWire_9 1;
BA_ "GenSigType" SG_ 2566853119 BATT_chargeNotNeeded_9 1;
BA_ "GenSigType" SG_ 2566853119 BATT_multiIgnLoFault_9 1;
BA_ "GenSigType" SG_ 2566853119 BATT_modThermistorShorted_9 1;
BA_ "GenSigType" SG_ 2566853119 BATT_harnessImpedanceFault_9 1;
BA_ "GenSigType" SG_ 2566853119 BATT_packLevelArbitrationFault_9 1;
BA_ "GenSigType" SG_ 2566853119 BATT_vBrickImbalanceWarning_9 1;
BA_ "GenSigType" SG_ 2566853877 BATT_isIgnLo_Requested 0;
BA_ "GenSigType" SG_ 2566853877 BATT_modReqCntr 0;
BA_ "GenSigType" SG_ 2566853877 BATT_stateRequest 0;
BA_ "GenSigType" SG_ 2566853877 BATT_startNodeId 0;
BA_ "GenSigType" SG_ 2566853877 BATT_isPushBtn_Requested 0;
BA_ "GenSigType" SG_ 2566854390 BATT_capBrick08_0 1;
BA_ "GenSigType" SG_ 2566854390 BATT_capBrick07_0 1;
BA_ "GenSigType" SG_ 2566854390 BATT_capBrick06_0 1;
BA_ "GenSigType" SG_ 2566854390 BATT_capBrick05_0 1;
BA_ "GenSigType" SG_ 2566854391 BATT_capBrick08_1 1;
BA_ "GenSigType" SG_ 2566854391 BATT_capBrick07_1 1;
BA_ "GenSigType" SG_ 2566854391 BATT_capBrick06_1 1;
BA_ "GenSigType" SG_ 2566854391 BATT_capBrick05_1 1;
BA_ "GenSigType" SG_ 2566854392 BATT_capBrick08_2 1;
BA_ "GenSigType" SG_ 2566854392 BATT_capBrick07_2 1;
BA_ "GenSigType" SG_ 2566854392 BATT_capBrick06_2 1;
BA_ "GenSigType" SG_ 2566854392 BATT_capBrick05_2 1;
BA_ "GenSigType" SG_ 2566854393 BATT_capBrick08_3 1;
BA_ "GenSigType" SG_ 2566854393 BATT_capBrick07_3 1;
BA_ "GenSigType" SG_ 2566854393 BATT_capBrick06_3 1;
BA_ "GenSigType" SG_ 2566854393 BATT_capBrick05_3 1;
BA_ "GenSigType" SG_ 2566854394 BATT_capBrick08_4 1;
BA_ "GenSigType" SG_ 2566854394 BATT_capBrick07_4 1;
BA_ "GenSigType" SG_ 2566854394 BATT_capBrick06_4 1;
BA_ "GenSigType" SG_ 2566854394 BATT_capBrick05_4 1;
BA_ "GenSigType" SG_ 2566854395 BATT_capBrick08_5 1;
BA_ "GenSigType" SG_ 2566854395 BATT_capBrick07_5 1;
BA_ "GenSigType" SG_ 2566854395 BATT_capBrick06_5 1;
BA_ "GenSigType" SG_ 2566854395 BATT_capBrick05_5 1;
BA_ "GenSigType" SG_ 2566854396 BATT_capBrick08_6 1;
BA_ "GenSigType" SG_ 2566854396 BATT_capBrick07_6 1;
BA_ "GenSigType" SG_ 2566854396 BATT_capBrick06_6 1;
BA_ "GenSigType" SG_ 2566854396 BATT_capBrick05_6 1;
BA_ "GenSigType" SG_ 2566854397 BATT_capBrick08_7 1;
BA_ "GenSigType" SG_ 2566854397 BATT_capBrick07_7 1;
BA_ "GenSigType" SG_ 2566854397 BATT_capBrick06_7 1;
BA_ "GenSigType" SG_ 2566854397 BATT_capBrick05_7 1;
BA_ "GenSigType" SG_ 2566854398 BATT_capBrick08_8 1;
BA_ "GenSigType" SG_ 2566854398 BATT_capBrick07_8 1;
BA_ "GenSigType" SG_ 2566854398 BATT_capBrick06_8 1;
BA_ "GenSigType" SG_ 2566854398 BATT_capBrick05_8 1;
BA_ "GenSigType" SG_ 2566854399 BATT_capBrick08_9 1;
BA_ "GenSigType" SG_ 2566854399 BATT_capBrick07_9 1;
BA_ "GenSigType" SG_ 2566854399 BATT_capBrick06_9 1;
BA_ "GenSigType" SG_ 2566854399 BATT_capBrick05_9 1;
BA_ "GenSigType" SG_ 2566854646 BATT_vBrick06_0 1;
BA_ "GenSigType" SG_ 2566854646 BATT_vBrick07_0 1;
BA_ "GenSigType" SG_ 2566854646 BATT_vBrick05_0 1;
BA_ "GenSigType" SG_ 2566854646 BATT_vBrick08_0 1;
BA_ "GenSigType" SG_ 2566854647 BATT_vBrick06_1 1;
BA_ "GenSigType" SG_ 2566854647 BATT_vBrick07_1 1;
BA_ "GenSigType" SG_ 2566854647 BATT_vBrick05_1 1;
BA_ "GenSigType" SG_ 2566854647 BATT_vBrick08_1 1;
BA_ "GenSigType" SG_ 2566854648 BATT_vBrick06_2 1;
BA_ "GenSigType" SG_ 2566854648 BATT_vBrick07_2 1;
BA_ "GenSigType" SG_ 2566854648 BATT_vBrick05_2 1;
BA_ "GenSigType" SG_ 2566854648 BATT_vBrick08_2 1;
BA_ "GenSigType" SG_ 2566854649 BATT_vBrick06_3 1;
BA_ "GenSigType" SG_ 2566854649 BATT_vBrick07_3 1;
BA_ "GenSigType" SG_ 2566854649 BATT_vBrick05_3 1;
BA_ "GenSigType" SG_ 2566854649 BATT_vBrick08_3 1;
BA_ "GenSigType" SG_ 2566854650 BATT_vBrick06_4 1;
BA_ "GenSigType" SG_ 2566854650 BATT_vBrick07_4 1;
BA_ "GenSigType" SG_ 2566854650 BATT_vBrick05_4 1;
BA_ "GenSigType" SG_ 2566854650 BATT_vBrick08_4 1;
BA_ "GenSigType" SG_ 2566854651 BATT_vBrick06_5 1;
BA_ "GenSigType" SG_ 2566854651 BATT_vBrick07_5 1;
BA_ "GenSigType" SG_ 2566854651 BATT_vBrick05_5 1;
BA_ "GenSigType" SG_ 2566854651 BATT_vBrick08_5 1;
BA_ "GenSigType" SG_ 2566854652 BATT_vBrick06_6 1;
BA_ "GenSigType" SG_ 2566854652 BATT_vBrick07_6 1;
BA_ "GenSigType" SG_ 2566854652 BATT_vBrick05_6 1;
BA_ "GenSigType" SG_ 2566854652 BATT_vBrick08_6 1;
BA_ "GenSigType" SG_ 2566854653 BATT_vBrick06_7 1;
BA_ "GenSigType" SG_ 2566854653 BATT_vBrick07_7 1;
BA_ "GenSigType" SG_ 2566854653 BATT_vBrick05_7 1;
BA_ "GenSigType" SG_ 2566854653 BATT_vBrick08_7 1;
BA_ "GenSigType" SG_ 2566854654 BATT_vBrick06_8 1;
BA_ "GenSigType" SG_ 2566854654 BATT_vBrick07_8 1;
BA_ "GenSigType" SG_ 2566854654 BATT_vBrick05_8 1;
BA_ "GenSigType" SG_ 2566854654 BATT_vBrick08_8 1;
BA_ "GenSigType" SG_ 2566854655 BATT_vBrick06_9 1;
BA_ "GenSigType" SG_ 2566854655 BATT_vBrick07_9 1;
BA_ "GenSigType" SG_ 2566854655 BATT_vBrick05_9 1;
BA_ "GenSigType" SG_ 2566854655 BATT_vBrick08_9 1;
BA_ "GenSigType" SG_ 2566855158 BATT_tPreChg_0 0;
BA_ "GenSigType" SG_ 2566855158 BATT_tShunt_0 0;
BA_ "GenSigType" SG_ 2566855158 BATT_tFET_0 0;
BA_ "GenSigType" SG_ 2566855159 BATT_tPreChg_1 0;
BA_ "GenSigType" SG_ 2566855159 BATT_tShunt_1 0;
BA_ "GenSigType" SG_ 2566855159 BATT_tFET_1 0;
BA_ "GenSigType" SG_ 2566855160 BATT_tPreChg_2 0;
BA_ "GenSigType" SG_ 2566855160 BATT_tShunt_2 0;
BA_ "GenSigType" SG_ 2566855160 BATT_tFET_2 0;
BA_ "GenSigType" SG_ 2566855161 BATT_tPreChg_3 0;
BA_ "GenSigType" SG_ 2566855161 BATT_tShunt_3 0;
BA_ "GenSigType" SG_ 2566855161 BATT_tFET_3 0;
BA_ "GenSigType" SG_ 2566855162 BATT_tPreChg_4 0;
BA_ "GenSigType" SG_ 2566855162 BATT_tShunt_4 0;
BA_ "GenSigType" SG_ 2566855162 BATT_tFET_4 0;
BA_ "GenSigType" SG_ 2566855163 BATT_tPreChg_5 0;
BA_ "GenSigType" SG_ 2566855163 BATT_tShunt_5 0;
BA_ "GenSigType" SG_ 2566855163 BATT_tFET_5 0;
BA_ "GenSigType" SG_ 2566855164 BATT_tPreChg_6 0;
BA_ "GenSigType" SG_ 2566855164 BATT_tShunt_6 0;
BA_ "GenSigType" SG_ 2566855164 BATT_tFET_6 0;
BA_ "GenSigType" SG_ 2566855165 BATT_tPreChg_7 0;
BA_ "GenSigType" SG_ 2566855165 BATT_tShunt_7 0;
BA_ "GenSigType" SG_ 2566855165 BATT_tFET_7 0;
BA_ "GenSigType" SG_ 2566855166 BATT_tPreChg_8 0;
BA_ "GenSigType" SG_ 2566855166 BATT_tShunt_8 0;
BA_ "GenSigType" SG_ 2566855166 BATT_tFET_8 0;
BA_ "GenSigType" SG_ 2566855167 BATT_tPreChg_9 0;
BA_ "GenSigType" SG_ 2566855167 BATT_tShunt_9 0;
BA_ "GenSigType" SG_ 2566855167 BATT_tFET_9 0;
BA_ "GenSigType" SG_ 2566858486 BATT_capBrick12_0 1;
BA_ "GenSigType" SG_ 2566858486 BATT_capBrick10_0 1;
BA_ "GenSigType" SG_ 2566858486 BATT_capBrick09_0 1;
BA_ "GenSigType" SG_ 2566858486 BATT_capBrick11_0 1;
BA_ "GenSigType" SG_ 2566858487 BATT_capBrick11_1 1;
BA_ "GenSigType" SG_ 2566858487 BATT_capBrick09_1 1;
BA_ "GenSigType" SG_ 2566858487 BATT_capBrick10_1 1;
BA_ "GenSigType" SG_ 2566858487 BATT_capBrick12_1 1;
BA_ "GenSigType" SG_ 2566858488 BATT_capBrick10_2 1;
BA_ "GenSigType" SG_ 2566858488 BATT_capBrick12_2 1;
BA_ "GenSigType" SG_ 2566858488 BATT_capBrick09_2 1;
BA_ "GenSigType" SG_ 2566858488 BATT_capBrick11_2 1;
BA_ "GenSigType" SG_ 2566858489 BATT_capBrick10_3 1;
BA_ "GenSigType" SG_ 2566858489 BATT_capBrick11_3 1;
BA_ "GenSigType" SG_ 2566858489 BATT_capBrick09_3 1;
BA_ "GenSigType" SG_ 2566858489 BATT_capBrick12_3 1;
BA_ "GenSigType" SG_ 2566858490 BATT_capBrick10_4 1;
BA_ "GenSigType" SG_ 2566858490 BATT_capBrick12_4 1;
BA_ "GenSigType" SG_ 2566858490 BATT_capBrick09_4 1;
BA_ "GenSigType" SG_ 2566858490 BATT_capBrick11_4 1;
BA_ "GenSigType" SG_ 2566858491 BATT_capBrick12_5 1;
BA_ "GenSigType" SG_ 2566858491 BATT_capBrick11_5 1;
BA_ "GenSigType" SG_ 2566858491 BATT_capBrick09_5 1;
BA_ "GenSigType" SG_ 2566858491 BATT_capBrick10_5 1;
BA_ "GenSigType" SG_ 2566858492 BATT_capBrick10_6 1;
BA_ "GenSigType" SG_ 2566858492 BATT_capBrick09_6 1;
BA_ "GenSigType" SG_ 2566858492 BATT_capBrick12_6 1;
BA_ "GenSigType" SG_ 2566858492 BATT_capBrick11_6 1;
BA_ "GenSigType" SG_ 2566858493 BATT_capBrick09_7 1;
BA_ "GenSigType" SG_ 2566858493 BATT_capBrick10_7 1;
BA_ "GenSigType" SG_ 2566858493 BATT_capBrick11_7 1;
BA_ "GenSigType" SG_ 2566858493 BATT_capBrick12_7 1;
BA_ "GenSigType" SG_ 2566858494 BATT_capBrick12_8 1;
BA_ "GenSigType" SG_ 2566858494 BATT_capBrick11_8 1;
BA_ "GenSigType" SG_ 2566858494 BATT_capBrick09_8 1;
BA_ "GenSigType" SG_ 2566858494 BATT_capBrick10_8 1;
BA_ "GenSigType" SG_ 2566858495 BATT_capBrick12_9 1;
BA_ "GenSigType" SG_ 2566858495 BATT_capBrick11_9 1;
BA_ "GenSigType" SG_ 2566858495 BATT_capBrick09_9 1;
BA_ "GenSigType" SG_ 2566858495 BATT_capBrick10_9 1;
BA_ "GenSigType" SG_ 2566858742 BATT_vBrick12_0 1;
BA_ "GenSigType" SG_ 2566858742 BATT_vBrick11_0 1;
BA_ "GenSigType" SG_ 2566858742 BATT_vBrick10_0 1;
BA_ "GenSigType" SG_ 2566858742 BATT_vBrick09_0 1;
BA_ "GenSigType" SG_ 2566858743 BATT_vBrick12_1 1;
BA_ "GenSigType" SG_ 2566858743 BATT_vBrick11_1 1;
BA_ "GenSigType" SG_ 2566858743 BATT_vBrick10_1 1;
BA_ "GenSigType" SG_ 2566858743 BATT_vBrick09_1 1;
BA_ "GenSigType" SG_ 2566858744 BATT_vBrick12_2 1;
BA_ "GenSigType" SG_ 2566858744 BATT_vBrick11_2 1;
BA_ "GenSigType" SG_ 2566858744 BATT_vBrick10_2 1;
BA_ "GenSigType" SG_ 2566858744 BATT_vBrick09_2 1;
BA_ "GenSigType" SG_ 2566858745 BATT_vBrick12_3 1;
BA_ "GenSigType" SG_ 2566858745 BATT_vBrick11_3 1;
BA_ "GenSigType" SG_ 2566858745 BATT_vBrick10_3 1;
BA_ "GenSigType" SG_ 2566858745 BATT_vBrick09_3 1;
BA_ "GenSigType" SG_ 2566858746 BATT_vBrick12_4 1;
BA_ "GenSigType" SG_ 2566858746 BATT_vBrick11_4 1;
BA_ "GenSigType" SG_ 2566858746 BATT_vBrick10_4 1;
BA_ "GenSigType" SG_ 2566858746 BATT_vBrick09_4 1;
BA_ "GenSigType" SG_ 2566858747 BATT_vBrick12_5 1;
BA_ "GenSigType" SG_ 2566858747 BATT_vBrick11_5 1;
BA_ "GenSigType" SG_ 2566858747 BATT_vBrick10_5 1;
BA_ "GenSigType" SG_ 2566858747 BATT_vBrick09_5 1;
BA_ "GenSigType" SG_ 2566858748 BATT_vBrick12_6 1;
BA_ "GenSigType" SG_ 2566858748 BATT_vBrick11_6 1;
BA_ "GenSigType" SG_ 2566858748 BATT_vBrick10_6 1;
BA_ "GenSigType" SG_ 2566858748 BATT_vBrick09_6 1;
BA_ "GenSigType" SG_ 2566858749 BATT_vBrick12_7 1;
BA_ "GenSigType" SG_ 2566858749 BATT_vBrick11_7 1;
BA_ "GenSigType" SG_ 2566858749 BATT_vBrick10_7 1;
BA_ "GenSigType" SG_ 2566858749 BATT_vBrick09_7 1;
BA_ "GenSigType" SG_ 2566858750 BATT_vBrick12_8 1;
BA_ "GenSigType" SG_ 2566858750 BATT_vBrick11_8 1;
BA_ "GenSigType" SG_ 2566858750 BATT_vBrick10_8 1;
BA_ "GenSigType" SG_ 2566858750 BATT_vBrick09_8 1;
BA_ "GenSigType" SG_ 2566858751 BATT_vBrick12_9 1;
BA_ "GenSigType" SG_ 2566858751 BATT_vBrick11_9 1;
BA_ "GenSigType" SG_ 2566858751 BATT_vBrick10_9 1;
BA_ "GenSigType" SG_ 2566858751 BATT_vBrick09_9 1;
BA_ "GenSigType" SG_ 2566862582 BATT_capBrick13_0 1;
BA_ "GenSigType" SG_ 2566862582 BATT_sohcPrimed_0 1;
BA_ "GenSigType" SG_ 2566862582 BATT_sohcUpdated_0 1;
BA_ "GenSigType" SG_ 2566862582 BATT_capBrick14_0 1;
BA_ "GenSigType" SG_ 2566862583 BATT_sohcPrimed_1 1;
BA_ "GenSigType" SG_ 2566862583 BATT_sohcUpdated_1 1;
BA_ "GenSigType" SG_ 2566862583 BATT_capBrick13_1 1;
BA_ "GenSigType" SG_ 2566862583 BATT_capBrick14_1 1;
BA_ "GenSigType" SG_ 2566862584 BATT_sohcUpdated_2 1;
BA_ "GenSigType" SG_ 2566862584 BATT_capBrick13_2 1;
BA_ "GenSigType" SG_ 2566862584 BATT_capBrick14_2 1;
BA_ "GenSigType" SG_ 2566862584 BATT_sohcPrimed_2 1;
BA_ "GenSigType" SG_ 2566862585 BATT_capBrick14_3 1;
BA_ "GenSigType" SG_ 2566862585 BATT_sohcPrimed_3 1;
BA_ "GenSigType" SG_ 2566862585 BATT_sohcUpdated_3 1;
BA_ "GenSigType" SG_ 2566862585 BATT_capBrick13_3 1;
BA_ "GenSigType" SG_ 2566862586 BATT_sohcPrimed_4 1;
BA_ "GenSigType" SG_ 2566862586 BATT_capBrick13_4 1;
BA_ "GenSigType" SG_ 2566862586 BATT_capBrick14_4 1;
BA_ "GenSigType" SG_ 2566862586 BATT_sohcUpdated_4 1;
BA_ "GenSigType" SG_ 2566862587 BATT_sohcPrimed_5 1;
BA_ "GenSigType" SG_ 2566862587 BATT_capBrick14_5 1;
BA_ "GenSigType" SG_ 2566862587 BATT_sohcUpdated_5 1;
BA_ "GenSigType" SG_ 2566862587 BATT_capBrick13_5 1;
BA_ "GenSigType" SG_ 2566862588 BATT_capBrick13_6 1;
BA_ "GenSigType" SG_ 2566862588 BATT_sohcPrimed_6 1;
BA_ "GenSigType" SG_ 2566862588 BATT_sohcUpdated_6 1;
BA_ "GenSigType" SG_ 2566862588 BATT_capBrick14_6 1;
BA_ "GenSigType" SG_ 2566862589 BATT_sohcUpdated_7 1;
BA_ "GenSigType" SG_ 2566862589 BATT_capBrick14_7 1;
BA_ "GenSigType" SG_ 2566862589 BATT_capBrick13_7 1;
BA_ "GenSigType" SG_ 2566862589 BATT_sohcPrimed_7 1;
BA_ "GenSigType" SG_ 2566862590 BATT_capBrick13_8 1;
BA_ "GenSigType" SG_ 2566862590 BATT_capBrick14_8 1;
BA_ "GenSigType" SG_ 2566862590 BATT_sohcUpdated_8 1;
BA_ "GenSigType" SG_ 2566862590 BATT_sohcPrimed_8 1;
BA_ "GenSigType" SG_ 2566862591 BATT_sohcUpdated_9 1;
BA_ "GenSigType" SG_ 2566862591 BATT_capBrick14_9 1;
BA_ "GenSigType" SG_ 2566862591 BATT_capBrick13_9 1;
BA_ "GenSigType" SG_ 2566862591 BATT_sohcPrimed_9 1;
BA_ "GenSigType" SG_ 2566862838 BATT_vBrick13_0 1;
BA_ "GenSigType" SG_ 2566862838 BATT_vBrick14_0 1;
BA_ "GenSigType" SG_ 2566862839 BATT_vBrick14_1 1;
BA_ "GenSigType" SG_ 2566862839 BATT_vBrick13_1 1;
BA_ "GenSigType" SG_ 2566862840 BATT_vBrick13_2 1;
BA_ "GenSigType" SG_ 2566862840 BATT_vBrick14_2 1;
BA_ "GenSigType" SG_ 2566862841 BATT_vBrick14_3 1;
BA_ "GenSigType" SG_ 2566862841 BATT_vBrick13_3 1;
BA_ "GenSigType" SG_ 2566862842 BATT_vBrick13_4 1;
BA_ "GenSigType" SG_ 2566862842 BATT_vBrick14_4 1;
BA_ "GenSigType" SG_ 2566862843 BATT_vBrick13_5 1;
BA_ "GenSigType" SG_ 2566862843 BATT_vBrick14_5 1;
BA_ "GenSigType" SG_ 2566862844 BATT_vBrick13_6 1;
BA_ "GenSigType" SG_ 2566862844 BATT_vBrick14_6 1;
BA_ "GenSigType" SG_ 2566862845 BATT_vBrick13_7 1;
BA_ "GenSigType" SG_ 2566862845 BATT_vBrick14_7 1;
BA_ "GenSigType" SG_ 2566862846 BATT_vBrick14_8 1;
BA_ "GenSigType" SG_ 2566862846 BATT_vBrick13_8 1;
BA_ "GenSigType" SG_ 2566862847 BATT_vBrick14_9 1;
BA_ "GenSigType" SG_ 2566862847 BATT_vBrick13_9 1;
BA_ "GenSigType" SG_ 2566865397 BATT_iPackFiltered 0;
BA_ "GenSigType" SG_ 2566865397 BATT_vPackLoad 0;
BA_ "GenSigType" SG_ 2566866165 BATT_tPackModuleMin 1;
BA_ "GenSigType" SG_ 2566866165 BATT_tPackModuleMax 1;
BA_ "GenSigSNA" SG_ 2566853110 BATT_harnessImpedanceFault_0 65535;
BA_ "GenSigSNA" SG_ 2566853111 BATT_harnessImpedanceFault_1 65535;
BA_ "GenSigSNA" SG_ 2566853112 BATT_harnessImpedanceFault_2 65535;
BA_ "GenSigSNA" SG_ 2566853113 BATT_harnessImpedanceFault_3 65535;
BA_ "GenSigSNA" SG_ 2566853114 BATT_harnessImpedanceFault_4 65535;
BA_ "GenSigSNA" SG_ 2566853115 BATT_harnessImpedanceFault_5 65535;
BA_ "GenSigSNA" SG_ 2566853116 BATT_harnessImpedanceFault_6 65535;
BA_ "GenSigSNA" SG_ 2566853117 BATT_harnessImpedanceFault_7 65535;
BA_ "GenSigSNA" SG_ 2566853118 BATT_harnessImpedanceFault_8 65535;
BA_ "GenSigSNA" SG_ 2566853119 BATT_harnessImpedanceFault_9 65535;
BA_ "GenSigSNA" SG_ 2566854390 BATT_capBrick08_0 65535;
BA_ "GenSigSNA" SG_ 2566854390 BATT_capBrick07_0 65535;
BA_ "GenSigSNA" SG_ 2566854390 BATT_capBrick06_0 65535;
BA_ "GenSigSNA" SG_ 2566854390 BATT_capBrick05_0 65535;
BA_ "GenSigSNA" SG_ 2566854391 BATT_capBrick08_1 65535;
BA_ "GenSigSNA" SG_ 2566854391 BATT_capBrick07_1 65535;
BA_ "GenSigSNA" SG_ 2566854391 BATT_capBrick06_1 65535;
BA_ "GenSigSNA" SG_ 2566854391 BATT_capBrick05_1 65535;
BA_ "GenSigSNA" SG_ 2566854392 BATT_capBrick08_2 65535;
BA_ "GenSigSNA" SG_ 2566854392 BATT_capBrick07_2 65535;
BA_ "GenSigSNA" SG_ 2566854392 BATT_capBrick06_2 65535;
BA_ "GenSigSNA" SG_ 2566854392 BATT_capBrick05_2 65535;
BA_ "GenSigSNA" SG_ 2566854393 BATT_capBrick08_3 65535;
BA_ "GenSigSNA" SG_ 2566854393 BATT_capBrick07_3 65535;
BA_ "GenSigSNA" SG_ 2566854393 BATT_capBrick06_3 65535;
BA_ "GenSigSNA" SG_ 2566854393 BATT_capBrick05_3 65535;
BA_ "GenSigSNA" SG_ 2566854394 BATT_capBrick08_4 65535;
BA_ "GenSigSNA" SG_ 2566854394 BATT_capBrick07_4 65535;
BA_ "GenSigSNA" SG_ 2566854394 BATT_capBrick06_4 65535;
BA_ "GenSigSNA" SG_ 2566854394 BATT_capBrick05_4 65535;
BA_ "GenSigSNA" SG_ 2566854395 BATT_capBrick08_5 65535;
BA_ "GenSigSNA" SG_ 2566854395 BATT_capBrick07_5 65535;
BA_ "GenSigSNA" SG_ 2566854395 BATT_capBrick06_5 65535;
BA_ "GenSigSNA" SG_ 2566854395 BATT_capBrick05_5 65535;
BA_ "GenSigSNA" SG_ 2566854396 BATT_capBrick08_6 65535;
BA_ "GenSigSNA" SG_ 2566854396 BATT_capBrick07_6 65535;
BA_ "GenSigSNA" SG_ 2566854396 BATT_capBrick06_6 65535;
BA_ "GenSigSNA" SG_ 2566854396 BATT_capBrick05_6 65535;
BA_ "GenSigSNA" SG_ 2566854397 BATT_capBrick08_7 65535;
BA_ "GenSigSNA" SG_ 2566854397 BATT_capBrick07_7 65535;
BA_ "GenSigSNA" SG_ 2566854397 BATT_capBrick06_7 65535;
BA_ "GenSigSNA" SG_ 2566854397 BATT_capBrick05_7 65535;
BA_ "GenSigSNA" SG_ 2566854398 BATT_capBrick08_8 65535;
BA_ "GenSigSNA" SG_ 2566854398 BATT_capBrick07_8 65535;
BA_ "GenSigSNA" SG_ 2566854398 BATT_capBrick06_8 65535;
BA_ "GenSigSNA" SG_ 2566854398 BATT_capBrick05_8 65535;
BA_ "GenSigSNA" SG_ 2566854399 BATT_capBrick08_9 65535;
BA_ "GenSigSNA" SG_ 2566854399 BATT_capBrick07_9 65535;
BA_ "GenSigSNA" SG_ 2566854399 BATT_capBrick06_9 65535;
BA_ "GenSigSNA" SG_ 2566854399 BATT_capBrick05_9 65535;
BA_ "GenSigSNA" SG_ 2566854646 BATT_vBrick06_0 65535;
BA_ "GenSigSNA" SG_ 2566854646 BATT_vBrick07_0 65535;
BA_ "GenSigSNA" SG_ 2566854646 BATT_vBrick05_0 65535;
BA_ "GenSigSNA" SG_ 2566854646 BATT_vBrick08_0 65535;
BA_ "GenSigSNA" SG_ 2566854647 BATT_vBrick06_1 65535;
BA_ "GenSigSNA" SG_ 2566854647 BATT_vBrick07_1 65535;
BA_ "GenSigSNA" SG_ 2566854647 BATT_vBrick05_1 65535;
BA_ "GenSigSNA" SG_ 2566854647 BATT_vBrick08_1 65535;
BA_ "GenSigSNA" SG_ 2566854648 BATT_vBrick06_2 65535;
BA_ "GenSigSNA" SG_ 2566854648 BATT_vBrick07_2 65535;
BA_ "GenSigSNA" SG_ 2566854648 BATT_vBrick05_2 65535;
BA_ "GenSigSNA" SG_ 2566854648 BATT_vBrick08_2 65535;
BA_ "GenSigSNA" SG_ 2566854649 BATT_vBrick06_3 65535;
BA_ "GenSigSNA" SG_ 2566854649 BATT_vBrick07_3 65535;
BA_ "GenSigSNA" SG_ 2566854649 BATT_vBrick05_3 65535;
BA_ "GenSigSNA" SG_ 2566854649 BATT_vBrick08_3 65535;
BA_ "GenSigSNA" SG_ 2566854650 BATT_vBrick06_4 65535;
BA_ "GenSigSNA" SG_ 2566854650 BATT_vBrick07_4 65535;
BA_ "GenSigSNA" SG_ 2566854650 BATT_vBrick05_4 65535;
BA_ "GenSigSNA" SG_ 2566854650 BATT_vBrick08_4 65535;
BA_ "GenSigSNA" SG_ 2566854651 BATT_vBrick06_5 65535;
BA_ "GenSigSNA" SG_ 2566854651 BATT_vBrick07_5 65535;
BA_ "GenSigSNA" SG_ 2566854651 BATT_vBrick05_5 65535;
BA_ "GenSigSNA" SG_ 2566854651 BATT_vBrick08_5 65535;
BA_ "GenSigSNA" SG_ 2566854652 BATT_vBrick06_6 65535;
BA_ "GenSigSNA" SG_ 2566854652 BATT_vBrick07_6 65535;
BA_ "GenSigSNA" SG_ 2566854652 BATT_vBrick05_6 65535;
BA_ "GenSigSNA" SG_ 2566854652 BATT_vBrick08_6 65535;
BA_ "GenSigSNA" SG_ 2566854653 BATT_vBrick06_7 65535;
BA_ "GenSigSNA" SG_ 2566854653 BATT_vBrick07_7 65535;
BA_ "GenSigSNA" SG_ 2566854653 BATT_vBrick05_7 65535;
BA_ "GenSigSNA" SG_ 2566854653 BATT_vBrick08_7 65535;
BA_ "GenSigSNA" SG_ 2566854654 BATT_vBrick06_8 65535;
BA_ "GenSigSNA" SG_ 2566854654 BATT_vBrick07_8 65535;
BA_ "GenSigSNA" SG_ 2566854654 BATT_vBrick05_8 65535;
BA_ "GenSigSNA" SG_ 2566854654 BATT_vBrick08_8 65535;
BA_ "GenSigSNA" SG_ 2566854655 BATT_vBrick06_9 65535;
BA_ "GenSigSNA" SG_ 2566854655 BATT_vBrick07_9 65535;
BA_ "GenSigSNA" SG_ 2566854655 BATT_vBrick05_9 65535;
BA_ "GenSigSNA" SG_ 2566854655 BATT_vBrick08_9 65535;
BA_ "GenSigSNA" SG_ 2566855158 BATT_tPreChg_0 65535;
BA_ "GenSigSNA" SG_ 2566855158 BATT_tShunt_0 65535;
BA_ "GenSigSNA" SG_ 2566855158 BATT_tFET_0 65535;
BA_ "GenSigSNA" SG_ 2566855159 BATT_tPreChg_1 65535;
BA_ "GenSigSNA" SG_ 2566855159 BATT_tShunt_1 65535;
BA_ "GenSigSNA" SG_ 2566855159 BATT_tFET_1 65535;
BA_ "GenSigSNA" SG_ 2566855160 BATT_tPreChg_2 65535;
BA_ "GenSigSNA" SG_ 2566855160 BATT_tShunt_2 65535;
BA_ "GenSigSNA" SG_ 2566855160 BATT_tFET_2 65535;
BA_ "GenSigSNA" SG_ 2566855161 BATT_tPreChg_3 65535;
BA_ "GenSigSNA" SG_ 2566855161 BATT_tShunt_3 65535;
BA_ "GenSigSNA" SG_ 2566855161 BATT_tFET_3 65535;
BA_ "GenSigSNA" SG_ 2566855162 BATT_tPreChg_4 65535;
BA_ "GenSigSNA" SG_ 2566855162 BATT_tShunt_4 65535;
BA_ "GenSigSNA" SG_ 2566855162 BATT_tFET_4 65535;
BA_ "GenSigSNA" SG_ 2566855163 BATT_tPreChg_5 65535;
BA_ "GenSigSNA" SG_ 2566855163 BATT_tShunt_5 65535;
BA_ "GenSigSNA" SG_ 2566855163 BATT_tFET_5 65535;
BA_ "GenSigSNA" SG_ 2566855164 BATT_tPreChg_6 65535;
BA_ "GenSigSNA" SG_ 2566855164 BATT_tShunt_6 65535;
BA_ "GenSigSNA" SG_ 2566855164 BATT_tFET_6 65535;
BA_ "GenSigSNA" SG_ 2566855165 BATT_tPreChg_7 65535;
BA_ "GenSigSNA" SG_ 2566855165 BATT_tShunt_7 65535;
BA_ "GenSigSNA" SG_ 2566855165 BATT_tFET_7 65535;
BA_ "GenSigSNA" SG_ 2566855166 BATT_tPreChg_8 65535;
BA_ "GenSigSNA" SG_ 2566855166 BATT_tShunt_8 65535;
BA_ "GenSigSNA" SG_ 2566855166 BATT_tFET_8 65535;
BA_ "GenSigSNA" SG_ 2566855167 BATT_tPreChg_9 65535;
BA_ "GenSigSNA" SG_ 2566855167 BATT_tShunt_9 65535;
BA_ "GenSigSNA" SG_ 2566855167 BATT_tFET_9 65535;
BA_ "GenSigSNA" SG_ 2566858486 BATT_capBrick12_0 65535;
BA_ "GenSigSNA" SG_ 2566858486 BATT_capBrick10_0 65535;
BA_ "GenSigSNA" SG_ 2566858486 BATT_capBrick09_0 65535;
BA_ "GenSigSNA" SG_ 2566858486 BATT_capBrick11_0 65535;
BA_ "GenSigSNA" SG_ 2566858487 BATT_capBrick11_1 65535;
BA_ "GenSigSNA" SG_ 2566858487 BATT_capBrick09_1 65535;
BA_ "GenSigSNA" SG_ 2566858487 BATT_capBrick10_1 65535;
BA_ "GenSigSNA" SG_ 2566858487 BATT_capBrick12_1 65535;
BA_ "GenSigSNA" SG_ 2566858488 BATT_capBrick10_2 65535;
BA_ "GenSigSNA" SG_ 2566858488 BATT_capBrick12_2 65535;
BA_ "GenSigSNA" SG_ 2566858488 BATT_capBrick09_2 65535;
BA_ "GenSigSNA" SG_ 2566858488 BATT_capBrick11_2 65535;
BA_ "GenSigSNA" SG_ 2566858489 BATT_capBrick10_3 65535;
BA_ "GenSigSNA" SG_ 2566858489 BATT_capBrick11_3 65535;
BA_ "GenSigSNA" SG_ 2566858489 BATT_capBrick09_3 65535;
BA_ "GenSigSNA" SG_ 2566858489 BATT_capBrick12_3 65535;
BA_ "GenSigSNA" SG_ 2566858490 BATT_capBrick10_4 65535;
BA_ "GenSigSNA" SG_ 2566858490 BATT_capBrick12_4 65535;
BA_ "GenSigSNA" SG_ 2566858490 BATT_capBrick09_4 65535;
BA_ "GenSigSNA" SG_ 2566858490 BATT_capBrick11_4 65535;
BA_ "GenSigSNA" SG_ 2566858491 BATT_capBrick12_5 65535;
BA_ "GenSigSNA" SG_ 2566858491 BATT_capBrick11_5 65535;
BA_ "GenSigSNA" SG_ 2566858491 BATT_capBrick09_5 65535;
BA_ "GenSigSNA" SG_ 2566858491 BATT_capBrick10_5 65535;
BA_ "GenSigSNA" SG_ 2566858492 BATT_capBrick10_6 65535;
BA_ "GenSigSNA" SG_ 2566858492 BATT_capBrick09_6 65535;
BA_ "GenSigSNA" SG_ 2566858492 BATT_capBrick12_6 65535;
BA_ "GenSigSNA" SG_ 2566858492 BATT_capBrick11_6 65535;
BA_ "GenSigSNA" SG_ 2566858493 BATT_capBrick09_7 65535;
BA_ "GenSigSNA" SG_ 2566858493 BATT_capBrick10_7 65535;
BA_ "GenSigSNA" SG_ 2566858493 BATT_capBrick11_7 65535;
BA_ "GenSigSNA" SG_ 2566858493 BATT_capBrick12_7 65535;
BA_ "GenSigSNA" SG_ 2566858494 BATT_capBrick12_8 65535;
BA_ "GenSigSNA" SG_ 2566858494 BATT_capBrick11_8 65535;
BA_ "GenSigSNA" SG_ 2566858494 BATT_capBrick09_8 65535;
BA_ "GenSigSNA" SG_ 2566858494 BATT_capBrick10_8 65535;
BA_ "GenSigSNA" SG_ 2566858495 BATT_capBrick12_9 65535;
BA_ "GenSigSNA" SG_ 2566858495 BATT_capBrick11_9 65535;
BA_ "GenSigSNA" SG_ 2566858495 BATT_capBrick09_9 65535;
BA_ "GenSigSNA" SG_ 2566858495 BATT_capBrick10_9 65535;
BA_ "GenSigSNA" SG_ 2566858742 BATT_vBrick12_0 65535;
BA_ "GenSigSNA" SG_ 2566858742 BATT_vBrick11_0 65535;
BA_ "GenSigSNA" SG_ 2566858742 BATT_vBrick10_0 65535;
BA_ "GenSigSNA" SG_ 2566858742 BATT_vBrick09_0 65535;
BA_ "GenSigSNA" SG_ 2566858743 BATT_vBrick12_1 65535;
BA_ "GenSigSNA" SG_ 2566858743 BATT_vBrick11_1 65535;
BA_ "GenSigSNA" SG_ 2566858743 BATT_vBrick10_1 65535;
BA_ "GenSigSNA" SG_ 2566858743 BATT_vBrick09_1 65535;
BA_ "GenSigSNA" SG_ 2566858744 BATT_vBrick12_2 65535;
BA_ "GenSigSNA" SG_ 2566858744 BATT_vBrick11_2 65535;
BA_ "GenSigSNA" SG_ 2566858744 BATT_vBrick10_2 65535;
BA_ "GenSigSNA" SG_ 2566858744 BATT_vBrick09_2 65535;
BA_ "GenSigSNA" SG_ 2566858745 BATT_vBrick12_3 65535;
BA_ "GenSigSNA" SG_ 2566858745 BATT_vBrick11_3 65535;
BA_ "GenSigSNA" SG_ 2566858745 BATT_vBrick10_3 65535;
BA_ "GenSigSNA" SG_ 2566858745 BATT_vBrick09_3 65535;
BA_ "GenSigSNA" SG_ 2566858746 BATT_vBrick12_4 65535;
BA_ "GenSigSNA" SG_ 2566858746 BATT_vBrick11_4 65535;
BA_ "GenSigSNA" SG_ 2566858746 BATT_vBrick10_4 65535;
BA_ "GenSigSNA" SG_ 2566858746 BATT_vBrick09_4 65535;
BA_ "GenSigSNA" SG_ 2566858747 BATT_vBrick12_5 65535;
BA_ "GenSigSNA" SG_ 2566858747 BATT_vBrick11_5 65535;
BA_ "GenSigSNA" SG_ 2566858747 BATT_vBrick10_5 65535;
BA_ "GenSigSNA" SG_ 2566858747 BATT_vBrick09_5 65535;
BA_ "GenSigSNA" SG_ 2566858748 BATT_vBrick12_6 65535;
BA_ "GenSigSNA" SG_ 2566858748 BATT_vBrick11_6 65535;
BA_ "GenSigSNA" SG_ 2566858748 BATT_vBrick10_6 65535;
BA_ "GenSigSNA" SG_ 2566858748 BATT_vBrick09_6 65535;
BA_ "GenSigSNA" SG_ 2566858749 BATT_vBrick12_7 65535;
BA_ "GenSigSNA" SG_ 2566858749 BATT_vBrick11_7 65535;
BA_ "GenSigSNA" SG_ 2566858749 BATT_vBrick10_7 65535;
BA_ "GenSigSNA" SG_ 2566858749 BATT_vBrick09_7 65535;
BA_ "GenSigSNA" SG_ 2566858750 BATT_vBrick12_8 65535;
BA_ "GenSigSNA" SG_ 2566858750 BATT_vBrick11_8 65535;
BA_ "GenSigSNA" SG_ 2566858750 BATT_vBrick10_8 65535;
BA_ "GenSigSNA" SG_ 2566858750 BATT_vBrick09_8 65535;
BA_ "GenSigSNA" SG_ 2566858751 BATT_vBrick12_9 65535;
BA_ "GenSigSNA" SG_ 2566858751 BATT_vBrick11_9 65535;
BA_ "GenSigSNA" SG_ 2566858751 BATT_vBrick10_9 65535;
BA_ "GenSigSNA" SG_ 2566858751 BATT_vBrick09_9 65535;
BA_ "GenSigSNA" SG_ 2566862582 BATT_capBrick13_0 65535;
BA_ "GenSigSNA" SG_ 2566862582 BATT_capBrick14_0 65535;
BA_ "GenSigSNA" SG_ 2566862583 BATT_capBrick13_1 65535;
BA_ "GenSigSNA" SG_ 2566862583 BATT_capBrick14_1 65535;
BA_ "GenSigSNA" SG_ 2566862584 BATT_capBrick13_2 65535;
BA_ "GenSigSNA" SG_ 2566862584 BATT_capBrick14_2 65535;
BA_ "GenSigSNA" SG_ 2566862585 BATT_capBrick14_3 65535;
BA_ "GenSigSNA" SG_ 2566862585 BATT_capBrick13_3 65535;
BA_ "GenSigSNA" SG_ 2566862586 BATT_capBrick13_4 65535;
BA_ "GenSigSNA" SG_ 2566862586 BATT_capBrick14_4 65535;
BA_ "GenSigSNA" SG_ 2566862587 BATT_capBrick14_5 65535;
BA_ "GenSigSNA" SG_ 2566862587 BATT_capBrick13_5 65535;
BA_ "GenSigSNA" SG_ 2566862588 BATT_capBrick13_6 65535;
BA_ "GenSigSNA" SG_ 2566862588 BATT_capBrick14_6 65535;
BA_ "GenSigSNA" SG_ 2566862589 BATT_capBrick14_7 65535;
BA_ "GenSigSNA" SG_ 2566862589 BATT_capBrick13_7 65535;
BA_ "GenSigSNA" SG_ 2566862590 BATT_capBrick13_8 65535;
BA_ "GenSigSNA" SG_ 2566862590 BATT_capBrick14_8 65535;
BA_ "GenSigSNA" SG_ 2566862591 BATT_capBrick14_9 65535;
BA_ "GenSigSNA" SG_ 2566862591 BATT_capBrick13_9 65535;
BA_ "GenSigSNA" SG_ 2566862838 BATT_vBrick13_0 65535;
BA_ "GenSigSNA" SG_ 2566862838 BATT_vBrick14_0 65535;
BA_ "GenSigSNA" SG_ 2566862839 BATT_vBrick14_1 65535;
BA_ "GenSigSNA" SG_ 2566862839 BATT_vBrick13_1 65535;
BA_ "GenSigSNA" SG_ 2566862840 BATT_vBrick13_2 65535;
BA_ "GenSigSNA" SG_ 2566862840 BATT_vBrick14_2 65535;
BA_ "GenSigSNA" SG_ 2566862841 BATT_vBrick14_3 65535;
BA_ "GenSigSNA" SG_ 2566862841 BATT_vBrick13_3 65535;
BA_ "GenSigSNA" SG_ 2566862842 BATT_vBrick13_4 65535;
BA_ "GenSigSNA" SG_ 2566862842 BATT_vBrick14_4 65535;
BA_ "GenSigSNA" SG_ 2566862843 BATT_vBrick13_5 65535;
BA_ "GenSigSNA" SG_ 2566862843 BATT_vBrick14_5 65535;
BA_ "GenSigSNA" SG_ 2566862844 BATT_vBrick13_6 65535;
BA_ "GenSigSNA" SG_ 2566862844 BATT_vBrick14_6 65535;
BA_ "GenSigSNA" SG_ 2566862845 BATT_vBrick13_7 65535;
BA_ "GenSigSNA" SG_ 2566862845 BATT_vBrick14_7 65535;
BA_ "GenSigSNA" SG_ 2566862846 BATT_vBrick14_8 65535;
BA_ "GenSigSNA" SG_ 2566862846 BATT_vBrick13_8 65535;
BA_ "GenSigSNA" SG_ 2566862847 BATT_vBrick14_9 65535;
BA_ "GenSigSNA" SG_ 2566862847 BATT_vBrick13_9 65535;
BA_ "GenSigSNA" SG_ 2566865397 BATT_iPackFiltered 32767;
BA_ "GenSigSNA" SG_ 2566865397 BATT_vPack 65535;
BA_ "GenSigSNA" SG_ 2566865397 BATT_iPack 32767;
BA_ "GenSigSNA" SG_ 2566865397 BATT_vPackLoad 65535;
BA_ "GenSigSNA" SG_ 2566866165 BATT_vPackBrickMax 4095;
BA_ "GenSigSNA" SG_ 2566866165 BATT_vPackBrickMin 4095;
BA_ "GenSigSNA" SG_ 2566866165 BATT_tPackModuleMin 2047;
BA_ "GenSigSNA" SG_ 2566866165 BATT_vPackModuleMinID 15;
BA_ "GenSigSNA" SG_ 2566866165 BATT_vPackModuleMaxID 15;
BA_ "GenSigSNA" SG_ 2566866165 BATT_tPackModuleMax 2047;
BA_ "GenSigSNA" SG_ 2566866165 BATT_tPackModuleMinID 15;
BA_ "GenSigSNA" SG_ 2566866165 BATT_tPackModuleMaxID 15;
BA_ "Access" SG_ 2566853877 BATT_nodeIdSerialNumber 1;
VAL_ 2566853877 BATT_stateRequest  3 "Sleep"  2 "Charge"  1 "Drive"  0 "None"  ;
VAL_ 2566854390 BATT_capBrick08_0  65535 "SNA"  ;
VAL_ 2566854390 BATT_capBrick07_0  65535 "SNA"  ;
VAL_ 2566854390 BATT_capBrick06_0  65535 "SNA"  ;
VAL_ 2566854390 BATT_capBrick05_0  65535 "SNA"  ;
VAL_ 2566854391 BATT_capBrick08_1  65535 "SNA"  ;
VAL_ 2566854391 BATT_capBrick07_1  65535 "SNA"  ;
VAL_ 2566854391 BATT_capBrick06_1  65535 "SNA"  ;
VAL_ 2566854391 BATT_capBrick05_1  65535 "SNA"  ;
VAL_ 2566854392 BATT_capBrick08_2  65535 "SNA"  ;
VAL_ 2566854392 BATT_capBrick07_2  65535 "SNA"  ;
VAL_ 2566854392 BATT_capBrick06_2  65535 "SNA"  ;
VAL_ 2566854392 BATT_capBrick05_2  65535 "SNA"  ;
VAL_ 2566854393 BATT_capBrick08_3  65535 "SNA"  ;
VAL_ 2566854393 BATT_capBrick07_3  65535 "SNA"  ;
VAL_ 2566854393 BATT_capBrick06_3  65535 "SNA"  ;
VAL_ 2566854393 BATT_capBrick05_3  65535 "SNA"  ;
VAL_ 2566854394 BATT_capBrick08_4  65535 "SNA"  ;
VAL_ 2566854394 BATT_capBrick07_4  65535 "SNA"  ;
VAL_ 2566854394 BATT_capBrick06_4  65535 "SNA"  ;
VAL_ 2566854394 BATT_capBrick05_4  65535 "SNA"  ;
VAL_ 2566854395 BATT_capBrick08_5  65535 "SNA"  ;
VAL_ 2566854395 BATT_capBrick07_5  65535 "SNA"  ;
VAL_ 2566854395 BATT_capBrick06_5  65535 "SNA"  ;
VAL_ 2566854395 BATT_capBrick05_5  65535 "SNA"  ;
VAL_ 2566854396 BATT_capBrick08_6  65535 "SNA"  ;
VAL_ 2566854396 BATT_capBrick07_6  65535 "SNA"  ;
VAL_ 2566854396 BATT_capBrick06_6  65535 "SNA"  ;
VAL_ 2566854396 BATT_capBrick05_6  65535 "SNA"  ;
VAL_ 2566854397 BATT_capBrick08_7  65535 "SNA"  ;
VAL_ 2566854397 BATT_capBrick07_7  65535 "SNA"  ;
VAL_ 2566854397 BATT_capBrick06_7  65535 "SNA"  ;
VAL_ 2566854397 BATT_capBrick05_7  65535 "SNA"  ;
VAL_ 2566854398 BATT_capBrick08_8  65535 "SNA"  ;
VAL_ 2566854398 BATT_capBrick07_8  65535 "SNA"  ;
VAL_ 2566854398 BATT_capBrick06_8  65535 "SNA"  ;
VAL_ 2566854398 BATT_capBrick05_8  65535 "SNA"  ;
VAL_ 2566854399 BATT_capBrick08_9  65535 "SNA"  ;
VAL_ 2566854399 BATT_capBrick07_9  65535 "SNA"  ;
VAL_ 2566854399 BATT_capBrick06_9  65535 "SNA"  ;
VAL_ 2566854399 BATT_capBrick05_9  65535 "SNA"  ;
VAL_ 2566854646 BATT_vBrick06_0  65535 "SNA"  ;
VAL_ 2566854646 BATT_vBrick07_0  65535 "SNA"  ;
VAL_ 2566854646 BATT_vBrick05_0  65535 "SNA"  ;
VAL_ 2566854646 BATT_vBrick08_0  65535 "SNA"  ;
VAL_ 2566854647 BATT_vBrick06_1  65535 "SNA"  ;
VAL_ 2566854647 BATT_vBrick07_1  65535 "SNA"  ;
VAL_ 2566854647 BATT_vBrick05_1  65535 "SNA"  ;
VAL_ 2566854647 BATT_vBrick08_1  65535 "SNA"  ;
VAL_ 2566854648 BATT_vBrick06_2  65535 "SNA"  ;
VAL_ 2566854648 BATT_vBrick07_2  65535 "SNA"  ;
VAL_ 2566854648 BATT_vBrick05_2  65535 "SNA"  ;
VAL_ 2566854648 BATT_vBrick08_2  65535 "SNA"  ;
VAL_ 2566854649 BATT_vBrick06_3  65535 "SNA"  ;
VAL_ 2566854649 BATT_vBrick07_3  65535 "SNA"  ;
VAL_ 2566854649 BATT_vBrick05_3  65535 "SNA"  ;
VAL_ 2566854649 BATT_vBrick08_3  65535 "SNA"  ;
VAL_ 2566854650 BATT_vBrick06_4  65535 "SNA"  ;
VAL_ 2566854650 BATT_vBrick07_4  65535 "SNA"  ;
VAL_ 2566854650 BATT_vBrick05_4  65535 "SNA"  ;
VAL_ 2566854650 BATT_vBrick08_4  65535 "SNA"  ;
VAL_ 2566854651 BATT_vBrick06_5  65535 "SNA"  ;
VAL_ 2566854651 BATT_vBrick07_5  65535 "SNA"  ;
VAL_ 2566854651 BATT_vBrick05_5  65535 "SNA"  ;
VAL_ 2566854651 BATT_vBrick08_5  65535 "SNA"  ;
VAL_ 2566854652 BATT_vBrick06_6  65535 "SNA"  ;
VAL_ 2566854652 BATT_vBrick07_6  65535 "SNA"  ;
VAL_ 2566854652 BATT_vBrick05_6  65535 "SNA"  ;
VAL_ 2566854652 BATT_vBrick08_6  65535 "SNA"  ;
VAL_ 2566854653 BATT_vBrick06_7  65535 "SNA"  ;
VAL_ 2566854653 BATT_vBrick07_7  65535 "SNA"  ;
VAL_ 2566854653 BATT_vBrick05_7  65535 "SNA"  ;
VAL_ 2566854653 BATT_vBrick08_7  65535 "SNA"  ;
VAL_ 2566854654 BATT_vBrick06_8  65535 "SNA"  ;
VAL_ 2566854654 BATT_vBrick07_8  65535 "SNA"  ;
VAL_ 2566854654 BATT_vBrick05_8  65535 "SNA"  ;
VAL_ 2566854654 BATT_vBrick08_8  65535 "SNA"  ;
VAL_ 2566854655 BATT_vBrick06_9  65535 "SNA"  ;
VAL_ 2566854655 BATT_vBrick07_9  65535 "SNA"  ;
VAL_ 2566854655 BATT_vBrick05_9  65535 "SNA"  ;
VAL_ 2566854655 BATT_vBrick08_9  65535 "SNA"  ;
VAL_ 2566855158 BATT_tPreChg_0  65535 "SNA"  ;
VAL_ 2566855158 BATT_tShunt_0  65535 "SNA"  ;
VAL_ 2566855158 BATT_tFET_0  65535 "SNA"  ;
VAL_ 2566855159 BATT_tPreChg_1  65535 "SNA"  ;
VAL_ 2566855159 BATT_tShunt_1  65535 "SNA"  ;
VAL_ 2566855159 BATT_tFET_1  65535 "SNA"  ;
VAL_ 2566855160 BATT_tPreChg_2  65535 "SNA"  ;
VAL_ 2566855160 BATT_tShunt_2  65535 "SNA"  ;
VAL_ 2566855160 BATT_tFET_2  65535 "SNA"  ;
VAL_ 2566855161 BATT_tPreChg_3  65535 "SNA"  ;
VAL_ 2566855161 BATT_tShunt_3  65535 "SNA"  ;
VAL_ 2566855161 BATT_tFET_3  65535 "SNA"  ;
VAL_ 2566855162 BATT_tPreChg_4  65535 "SNA"  ;
VAL_ 2566855162 BATT_tShunt_4  65535 "SNA"  ;
VAL_ 2566855162 BATT_tFET_4  65535 "SNA"  ;
VAL_ 2566855163 BATT_tPreChg_5  65535 "SNA"  ;
VAL_ 2566855163 BATT_tShunt_5  65535 "SNA"  ;
VAL_ 2566855163 BATT_tFET_5  65535 "SNA"  ;
VAL_ 2566855164 BATT_tPreChg_6  65535 "SNA"  ;
VAL_ 2566855164 BATT_tShunt_6  65535 "SNA"  ;
VAL_ 2566855164 BATT_tFET_6  65535 "SNA"  ;
VAL_ 2566855165 BATT_tPreChg_7  65535 "SNA"  ;
VAL_ 2566855165 BATT_tShunt_7  65535 "SNA"  ;
VAL_ 2566855165 BATT_tFET_7  65535 "SNA"  ;
VAL_ 2566855166 BATT_tPreChg_8  65535 "SNA"  ;
VAL_ 2566855166 BATT_tShunt_8  65535 "SNA"  ;
VAL_ 2566855166 BATT_tFET_8  65535 "SNA"  ;
VAL_ 2566855167 BATT_tPreChg_9  65535 "SNA"  ;
VAL_ 2566855167 BATT_tShunt_9  65535 "SNA"  ;
VAL_ 2566855167 BATT_tFET_9  65535 "SNA"  ;
VAL_ 2566858486 BATT_capBrick12_0  65535 "SNA"  ;
VAL_ 2566858486 BATT_capBrick10_0  65535 "SNA"  ;
VAL_ 2566858486 BATT_capBrick09_0  65535 "SNA"  ;
VAL_ 2566858486 BATT_capBrick11_0  65535 "SNA"  ;
VAL_ 2566858487 BATT_capBrick11_1  65535 "SNA"  ;
VAL_ 2566858487 BATT_capBrick09_1  65535 "SNA"  ;
VAL_ 2566858487 BATT_capBrick10_1  65535 "SNA"  ;
VAL_ 2566858487 BATT_capBrick12_1  65535 "SNA"  ;
VAL_ 2566858488 BATT_capBrick10_2  65535 "SNA"  ;
VAL_ 2566858488 BATT_capBrick12_2  65535 "SNA"  ;
VAL_ 2566858488 BATT_capBrick09_2  65535 "SNA"  ;
VAL_ 2566858488 BATT_capBrick11_2  65535 "SNA"  ;
VAL_ 2566858489 BATT_capBrick10_3  65535 "SNA"  ;
VAL_ 2566858489 BATT_capBrick11_3  65535 "SNA"  ;
VAL_ 2566858489 BATT_capBrick09_3  65535 "SNA"  ;
VAL_ 2566858489 BATT_capBrick12_3  65535 "SNA"  ;
VAL_ 2566858490 BATT_capBrick10_4  65535 "SNA"  ;
VAL_ 2566858490 BATT_capBrick12_4  65535 "SNA"  ;
VAL_ 2566858490 BATT_capBrick09_4  65535 "SNA"  ;
VAL_ 2566858490 BATT_capBrick11_4  65535 "SNA"  ;
VAL_ 2566858491 BATT_capBrick12_5  65535 "SNA"  ;
VAL_ 2566858491 BATT_capBrick11_5  65535 "SNA"  ;
VAL_ 2566858491 BATT_capBrick09_5  65535 "SNA"  ;
VAL_ 2566858491 BATT_capBrick10_5  65535 "SNA"  ;
VAL_ 2566858492 BATT_capBrick10_6  65535 "SNA"  ;
VAL_ 2566858492 BATT_capBrick09_6  65535 "SNA"  ;
VAL_ 2566858492 BATT_capBrick12_6  65535 "SNA"  ;
VAL_ 2566858492 BATT_capBrick11_6  65535 "SNA"  ;
VAL_ 2566858493 BATT_capBrick09_7  65535 "SNA"  ;
VAL_ 2566858493 BATT_capBrick10_7  65535 "SNA"  ;
VAL_ 2566858493 BATT_capBrick11_7  65535 "SNA"  ;
VAL_ 2566858493 BATT_capBrick12_7  65535 "SNA"  ;
VAL_ 2566858494 BATT_capBrick12_8  65535 "SNA"  ;
VAL_ 2566858494 BATT_capBrick11_8  65535 "SNA"  ;
VAL_ 2566858494 BATT_capBrick09_8  65535 "SNA"  ;
VAL_ 2566858494 BATT_capBrick10_8  65535 "SNA"  ;
VAL_ 2566858495 BATT_capBrick12_9  65535 "SNA"  ;
VAL_ 2566858495 BATT_capBrick11_9  65535 "SNA"  ;
VAL_ 2566858495 BATT_capBrick09_9  65535 "SNA"  ;
VAL_ 2566858495 BATT_capBrick10_9  65535 "SNA"  ;
VAL_ 2566858742 BATT_vBrick12_0  65535 "SNA"  ;
VAL_ 2566858742 BATT_vBrick11_0  65535 "SNA"  ;
VAL_ 2566858742 BATT_vBrick10_0  65535 "SNA"  ;
VAL_ 2566858742 BATT_vBrick09_0  65535 "SNA"  ;
VAL_ 2566858743 BATT_vBrick12_1  65535 "SNA"  ;
VAL_ 2566858743 BATT_vBrick11_1  65535 "SNA"  ;
VAL_ 2566858743 BATT_vBrick10_1  65535 "SNA"  ;
VAL_ 2566858743 BATT_vBrick09_1  65535 "SNA"  ;
VAL_ 2566858744 BATT_vBrick12_2  65535 "SNA"  ;
VAL_ 2566858744 BATT_vBrick11_2  65535 "SNA"  ;
VAL_ 2566858744 BATT_vBrick10_2  65535 "SNA"  ;
VAL_ 2566858744 BATT_vBrick09_2  65535 "SNA"  ;
VAL_ 2566858745 BATT_vBrick12_3  65535 "SNA"  ;
VAL_ 2566858745 BATT_vBrick11_3  65535 "SNA"  ;
VAL_ 2566858745 BATT_vBrick10_3  65535 "SNA"  ;
VAL_ 2566858745 BATT_vBrick09_3  65535 "SNA"  ;
VAL_ 2566858746 BATT_vBrick12_4  65535 "SNA"  ;
VAL_ 2566858746 BATT_vBrick11_4  65535 "SNA"  ;
VAL_ 2566858746 BATT_vBrick10_4  65535 "SNA"  ;
VAL_ 2566858746 BATT_vBrick09_4  65535 "SNA"  ;
VAL_ 2566858747 BATT_vBrick12_5  65535 "SNA"  ;
VAL_ 2566858747 BATT_vBrick11_5  65535 "SNA"  ;
VAL_ 2566858747 BATT_vBrick10_5  65535 "SNA"  ;
VAL_ 2566858747 BATT_vBrick09_5  65535 "SNA"  ;
VAL_ 2566858748 BATT_vBrick12_6  65535 "SNA"  ;
VAL_ 2566858748 BATT_vBrick11_6  65535 "SNA"  ;
VAL_ 2566858748 BATT_vBrick10_6  65535 "SNA"  ;
VAL_ 2566858748 BATT_vBrick09_6  65535 "SNA"  ;
VAL_ 2566858749 BATT_vBrick12_7  65535 "SNA"  ;
VAL_ 2566858749 BATT_vBrick11_7  65535 "SNA"  ;
VAL_ 2566858749 BATT_vBrick10_7  65535 "SNA"  ;
VAL_ 2566858749 BATT_vBrick09_7  65535 "SNA"  ;
VAL_ 2566858750 BATT_vBrick12_8  65535 "SNA"  ;
VAL_ 2566858750 BATT_vBrick11_8  65535 "SNA"  ;
VAL_ 2566858750 BATT_vBrick10_8  65535 "SNA"  ;
VAL_ 2566858750 BATT_vBrick09_8  65535 "SNA"  ;
VAL_ 2566858751 BATT_vBrick12_9  65535 "SNA"  ;
VAL_ 2566858751 BATT_vBrick11_9  65535 "SNA"  ;
VAL_ 2566858751 BATT_vBrick10_9  65535 "SNA"  ;
VAL_ 2566858751 BATT_vBrick09_9  65535 "SNA"  ;
VAL_ 2566862582 BATT_capBrick13_0  65535 "SNA"  ;
VAL_ 2566862582 BATT_capBrick14_0  65535 "SNA"  ;
VAL_ 2566862583 BATT_capBrick13_1  65535 "SNA"  ;
VAL_ 2566862583 BATT_capBrick14_1  65535 "SNA"  ;
VAL_ 2566862584 BATT_capBrick13_2  65535 "SNA"  ;
VAL_ 2566862584 BATT_capBrick14_2  65535 "SNA"  ;
VAL_ 2566862585 BATT_capBrick14_3  65535 "SNA"  ;
VAL_ 2566862585 BATT_capBrick13_3  65535 "SNA"  ;
VAL_ 2566862586 BATT_capBrick13_4  65535 "SNA"  ;
VAL_ 2566862586 BATT_capBrick14_4  65535 "SNA"  ;
VAL_ 2566862587 BATT_capBrick14_5  65535 "SNA"  ;
VAL_ 2566862587 BATT_capBrick13_5  65535 "SNA"  ;
VAL_ 2566862588 BATT_capBrick13_6  65535 "SNA"  ;
VAL_ 2566862588 BATT_capBrick14_6  65535 "SNA"  ;
VAL_ 2566862589 BATT_capBrick14_7  65535 "SNA"  ;
VAL_ 2566862589 BATT_capBrick13_7  65535 "SNA"  ;
VAL_ 2566862590 BATT_capBrick13_8  65535 "SNA"  ;
VAL_ 2566862590 BATT_capBrick14_8  65535 "SNA"  ;
VAL_ 2566862591 BATT_capBrick14_9  65535 "SNA"  ;
VAL_ 2566862591 BATT_capBrick13_9  65535 "SNA"  ;
VAL_ 2566862838 BATT_vBrick13_0  65535 "SNA"  ;
VAL_ 2566862838 BATT_vBrick14_0  65535 "SNA"  ;
VAL_ 2566862839 BATT_vBrick14_1  65535 "SNA"  ;
VAL_ 2566862839 BATT_vBrick13_1  65535 "SNA"  ;
VAL_ 2566862840 BATT_vBrick13_2  65535 "SNA"  ;
VAL_ 2566862840 BATT_vBrick14_2  65535 "SNA"  ;
VAL_ 2566862841 BATT_vBrick14_3  65535 "SNA"  ;
VAL_ 2566862841 BATT_vBrick13_3  65535 "SNA"  ;
VAL_ 2566862842 BATT_vBrick13_4  65535 "SNA"  ;
VAL_ 2566862842 BATT_vBrick14_4  65535 "SNA"  ;
VAL_ 2566862843 BATT_vBrick13_5  65535 "SNA"  ;
VAL_ 2566862843 BATT_vBrick14_5  65535 "SNA"  ;
VAL_ 2566862844 BATT_vBrick13_6  65535 "SNA"  ;
VAL_ 2566862844 BATT_vBrick14_6  65535 "SNA"  ;
VAL_ 2566862845 BATT_vBrick13_7  65535 "SNA"  ;
VAL_ 2566862845 BATT_vBrick14_7  65535 "SNA"  ;
VAL_ 2566862846 BATT_vBrick14_8  65535 "SNA"  ;
VAL_ 2566862846 BATT_vBrick13_8  65535 "SNA"  ;
VAL_ 2566862847 BATT_vBrick14_9  65535 "SNA"  ;
VAL_ 2566862847 BATT_vBrick13_9  65535 "SNA"  ;
VAL_ 2566865397 BATT_iPackFiltered  32767 "SNA"  ;
VAL_ 2566865397 BATT_vPack  65535 "SNA"  ;
VAL_ 2566865397 BATT_iPack  32767 "SNA"  ;
VAL_ 2566865397 BATT_vPackLoad  65535 "SNA"  ;
VAL_ 2566866165 BATT_vPackBrickMax  4095 "SNA"  ;
VAL_ 2566866165 BATT_vPackBrickMin  4095 "SNA"  ;
VAL_ 2566866165 BATT_tPackModuleMin  2047 "SNA"  ;
VAL_ 2566866165 BATT_vPackModuleMinID  15 "SNA"  ;
VAL_ 2566866165 BATT_vPackModuleMaxID  15 "SNA"  ;
VAL_ 2566866165 BATT_tPackModuleMax  2047 "SNA"  ;
VAL_ 2566866165 BATT_tPackModuleMinID  15 "SNA"  ;
VAL_ 2566866165 BATT_tPackModuleMaxID  15 "SNA"  ;
